VERSION ""

NS_ :

BS_:

BU_:

BO_ 2364747006 HVESP25MS1: 8 Vector__XXX
 SG_ Hvesp25Module1OperationalStatus : 0|2@1+ (1,0) [0|3] "" Vector__XXX
 SG_ Hvesp25Module2OperationalStatus : 2|2@1+ (1,0) [0|3] "" Vector__XXX
 SG_ Hvesp25Module3OperationalStatus : 4|2@1+ (1,0) [0|3] "" Vector__XXX
 SG_ Hvesp25Module4OperationalStatus : 6|2@1+ (1,0) [0|3] "" Vector__XXX
 SG_ Hvesp25Module5OperationalStatus : 8|2@1+ (1,0) [0|3] "" Vector__XXX
 SG_ Hvesp25Module6OperationalStatus : 10|2@1+ (1,0) [0|3] "" Vector__XXX
 SG_ Hvesp25Module7OperationalStatus : 12|2@1+ (1,0) [0|3] "" Vector__XXX
 SG_ Hvesp25Module8OperationalStatus : 14|2@1+ (1,0) [0|3] "" Vector__XXX
 SG_ Hvesp25Module9OperationalStatus : 16|2@1+ (1,0) [0|3] "" Vector__XXX
 SG_ Hvsp25Mdl10OprtnlStts : 18|2@1+ (1,0) [0|3] "" Vector__XXX
 SG_ Hvsp25Mdl11OprtnlStts : 20|2@1+ (1,0) [0|3] "" Vector__XXX
 SG_ Hvsp25Mdl12OprtnlStts : 22|2@1+ (1,0) [0|3] "" Vector__XXX
 SG_ Hvsp25Mdl13OprtnlStts : 24|2@1+ (1,0) [0|3] "" Vector__XXX
 SG_ Hvsp25Mdl14OprtnlStts : 26|2@1+ (1,0) [0|3] "" Vector__XXX
 SG_ Hvsp25Mdl15OprtnlStts : 28|2@1+ (1,0) [0|3] "" Vector__XXX
 SG_ Hvsp25Mdl16OprtnlStts : 30|2@1+ (1,0) [0|3] "" Vector__XXX
 SG_ Hvsp25Mdl17OprtnlStts : 32|2@1+ (1,0) [0|3] "" Vector__XXX
 SG_ Hvsp25Mdl18OprtnlStts : 34|2@1+ (1,0) [0|3] "" Vector__XXX
 SG_ Hvsp25Mdl19OprtnlStts : 36|2@1+ (1,0) [0|3] "" Vector__XXX
 SG_ Hvsp25Mdl20OprtnlStts : 38|2@1+ (1,0) [0|3] "" Vector__XXX
 SG_ Hvsp25Mdl21OprtnlStts : 40|2@1+ (1,0) [0|3] "" Vector__XXX
 SG_ Hvsp25Mdl22OprtnlStts : 42|2@1+ (1,0) [0|3] "" Vector__XXX
 SG_ Hvsp25Mdl23OprtnlStts : 44|2@1+ (1,0) [0|3] "" Vector__XXX
 SG_ Hvsp25Mdl24OprtnlStts : 46|2@1+ (1,0) [0|3] "" Vector__XXX
 SG_ Hvsp25Mdl25OprtnlStts : 48|2@1+ (1,0) [0|3] "" Vector__XXX
 SG_ Hvsp25Mdl26OprtnlStts : 50|2@1+ (1,0) [0|3] "" Vector__XXX
 SG_ Hvsp25Mdl27OprtnlStts : 52|2@1+ (1,0) [0|3] "" Vector__XXX
 SG_ Hvsp25Mdl28OprtnlStts : 54|2@1+ (1,0) [0|3] "" Vector__XXX
 SG_ Hvsp25Mdl29OprtnlStts : 56|2@1+ (1,0) [0|3] "" Vector__XXX
 SG_ Hvsp25Mdl30OprtnlStts : 58|2@1+ (1,0) [0|3] "" Vector__XXX
 SG_ Hvsp25Mdl31OprtnlStts : 60|2@1+ (1,0) [0|3] "" Vector__XXX
 SG_ Hvsp25Mdl32OprtnlStts : 62|2@1+ (1,0) [0|3] "" Vector__XXX

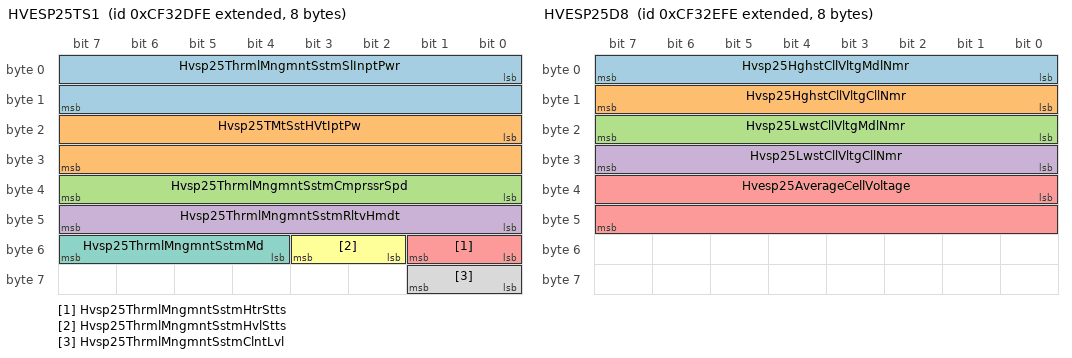
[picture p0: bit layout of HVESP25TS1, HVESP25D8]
BO_ 2364747262 HVESP25TS1: 8 Vector__XXX
 SG_ Hvsp25ThrmlMngmntSstmSlInptPwr : 0|16@1+ (0.5,0) [0|32127.5] "W" Vector__XXX
 SG_ Hvsp25TMtSstHVtIptPw : 16|16@1+ (0.5,0) [0|32127.5] "W" Vector__XXX
 SG_ Hvsp25ThrmlMngmntSstmCmprssrSpd : 32|8@1+ (32,0) [0|8000] "rpm" Vector__XXX
 SG_ Hvsp25ThrmlMngmntSstmRltvHmdt : 40|8@1+ (0.4,0) [0|100] "%" Vector__XXX
 SG_ Hvsp25ThrmlMngmntSstmHtrStts : 48|2@1+ (1,0) [0|3] "" Vector__XXX
 SG_ Hvsp25ThrmlMngmntSstmHvlStts : 50|2@1+ (1,0) [0|3] "" Vector__XXX
 SG_ Hvsp25ThrmlMngmntSstmMd : 52|4@1+ (1,0) [0|15] "" Vector__XXX
 SG_ Hvsp25ThrmlMngmntSstmClntLvl : 56|2@1+ (1,0) [0|3] "" Vector__XXX

BO_ 2364747518 HVESP25D8: 8 Vector__XXX
 SG_ Hvsp25HghstCllVltgMdlNmr : 0|8@1+ (1,0) [0|250] "count" Vector__XXX
 SG_ Hvsp25HghstCllVltgCllNmr : 8|8@1+ (1,0) [0|250] "count" Vector__XXX
 SG_ Hvsp25LwstCllVltgMdlNmr : 16|8@1+ (1,0) [0|250] "count" Vector__XXX
 SG_ Hvsp25LwstCllVltgCllNmr : 24|8@1+ (1,0) [0|250] "count" Vector__XXX
 SG_ Hvesp25AverageCellVoltage : 32|16@1+ (0.001,0) [0|64.255] "V" Vector__XXX

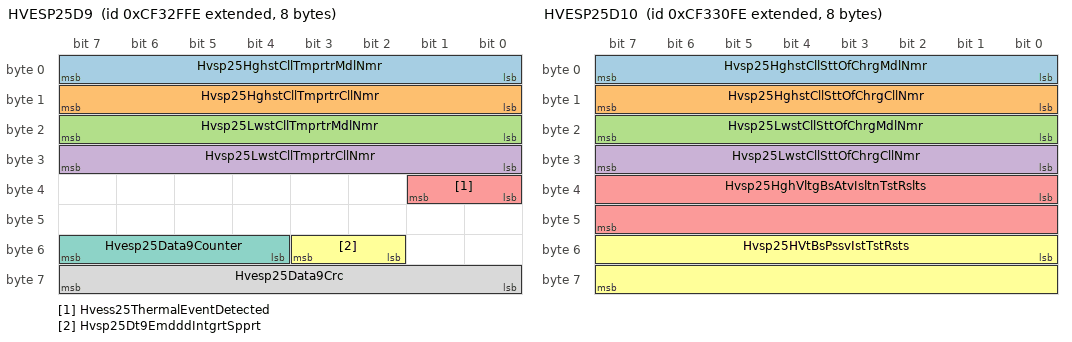
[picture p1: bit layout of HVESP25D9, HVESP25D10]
BO_ 2364747774 HVESP25D9: 8 Vector__XXX
 SG_ Hvsp25HghstCllTmprtrMdlNmr : 0|8@1+ (1,0) [0|250] "count" Vector__XXX
 SG_ Hvsp25HghstCllTmprtrCllNmr : 8|8@1+ (1,0) [0|250] "count" Vector__XXX
 SG_ Hvsp25LwstCllTmprtrMdlNmr : 16|8@1+ (1,0) [0|250] "count" Vector__XXX
 SG_ Hvsp25LwstCllTmprtrCllNmr : 24|8@1+ (1,0) [0|250] "count" Vector__XXX
 SG_ Hvess25ThermalEventDetected : 32|2@1+ (1,0) [0|3] "" Vector__XXX
 SG_ Hvsp25Dt9EmdddIntgrtSpprt : 50|2@1+ (1,0) [0|3] "" Vector__XXX
 SG_ Hvesp25Data9Counter : 52|4@1+ (1,0) [0|15] "" Vector__XXX
 SG_ Hvesp25Data9Crc : 56|8@1+ (1,0) [0|250] "count" Vector__XXX

BO_ 2364748030 HVESP25D10: 8 Vector__XXX
 SG_ Hvsp25HghstCllSttOfChrgMdlNmr : 0|8@1+ (1,0) [0|250] "count" Vector__XXX
 SG_ Hvsp25HghstCllSttOfChrgCllNmr : 8|8@1+ (1,0) [0|250] "count" Vector__XXX
 SG_ Hvsp25LwstCllSttOfChrgMdlNmr : 16|8@1+ (1,0) [0|250] "count" Vector__XXX
 SG_ Hvsp25LwstCllSttOfChrgCllNmr : 24|8@1+ (1,0) [0|250] "count" Vector__XXX
 SG_ Hvsp25HghVltgBsAtvIsltnTstRslts : 32|16@1+ (0.1,0) [0|6425.5] "OhmPerV" Vector__XXX
 SG_ Hvsp25HVtBsPssvIstTstRsts : 48|16@1+ (0.1,0) [0|6425.5] "OhmPerV" Vector__XXX

BO_ 2364748286 HVESP25D11: 8 Vector__XXX
 SG_ Hvsp25BsVltgNgtvTChsssGrndVltg : 0|16@1+ (0.05,0) [0|3212.75] "V" Vector__XXX
 SG_ Hvsp25VltgLvlNgtvTChsssGrndVltg : 16|16@1+ (0.05,0) [0|3212.75] "V" Vector__XXX
 SG_ Hvesp25ActualChargeRate : 32|16@1+ (0.05,0) [0|3212.75] "kW" Vector__XXX

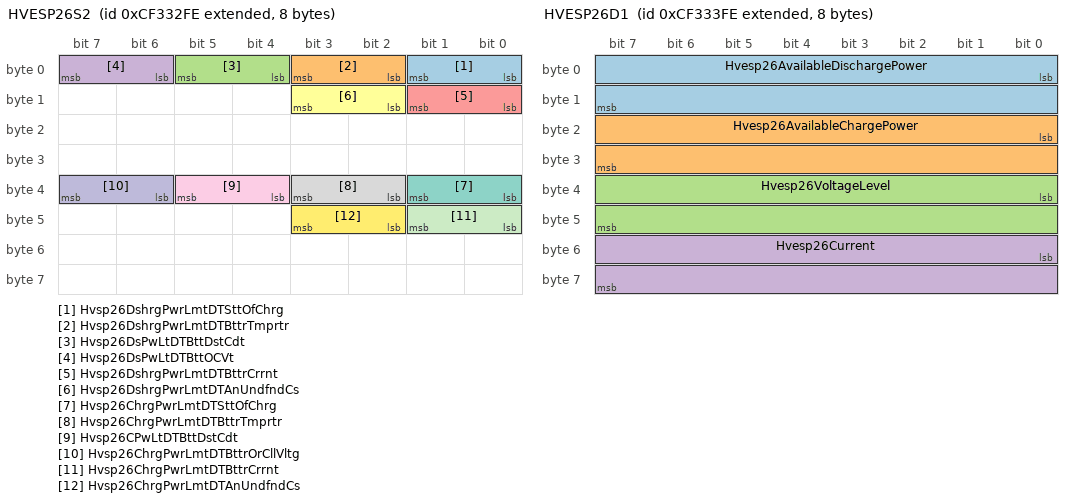
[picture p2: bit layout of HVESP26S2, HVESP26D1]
BO_ 2364748542 HVESP26S2: 8 Vector__XXX
 SG_ Hvsp26DshrgPwrLmtDTSttOfChrg : 0|2@1+ (1,0) [0|3] "" Vector__XXX
 SG_ Hvsp26DshrgPwrLmtDTBttrTmprtr : 2|2@1+ (1,0) [0|3] "" Vector__XXX
 SG_ Hvsp26DsPwLtDTBttDstCdt : 4|2@1+ (1,0) [0|3] "" Vector__XXX
 SG_ Hvsp26DsPwLtDTBttOCVt : 6|2@1+ (1,0) [0|3] "" Vector__XXX
 SG_ Hvsp26DshrgPwrLmtDTBttrCrrnt : 8|2@1+ (1,0) [0|3] "" Vector__XXX
 SG_ Hvsp26DshrgPwrLmtDTAnUndfndCs : 10|2@1+ (1,0) [0|3] "" Vector__XXX
 SG_ Hvsp26ChrgPwrLmtDTSttOfChrg : 32|2@1+ (1,0) [0|3] "" Vector__XXX
 SG_ Hvsp26ChrgPwrLmtDTBttrTmprtr : 34|2@1+ (1,0) [0|3] "" Vector__XXX
 SG_ Hvsp26CPwLtDTBttDstCdt : 36|2@1+ (1,0) [0|3] "" Vector__XXX
 SG_ Hvsp26ChrgPwrLmtDTBttrOrCllVltg : 38|2@1+ (1,0) [0|3] "" Vector__XXX
 SG_ Hvsp26ChrgPwrLmtDTBttrCrrnt : 40|2@1+ (1,0) [0|3] "" Vector__XXX
 SG_ Hvsp26ChrgPwrLmtDTAnUndfndCs : 42|2@1+ (1,0) [0|3] "" Vector__XXX

BO_ 2364748798 HVESP26D1: 8 Vector__XXX
 SG_ Hvesp26AvailableDischargePower : 0|16@1+ (0.05,0) [0|3212.75] "kW" Vector__XXX
 SG_ Hvesp26AvailableChargePower : 16|16@1+ (0.05,0) [0|3212.75] "kW" Vector__XXX
 SG_ Hvesp26VoltageLevel : 32|16@1+ (0.05,0) [0|3212.75] "V" Vector__XXX
 SG_ Hvesp26Current : 48|16@1+ (0.05,-1600) [-1600|1612.75] "A" Vector__XXX

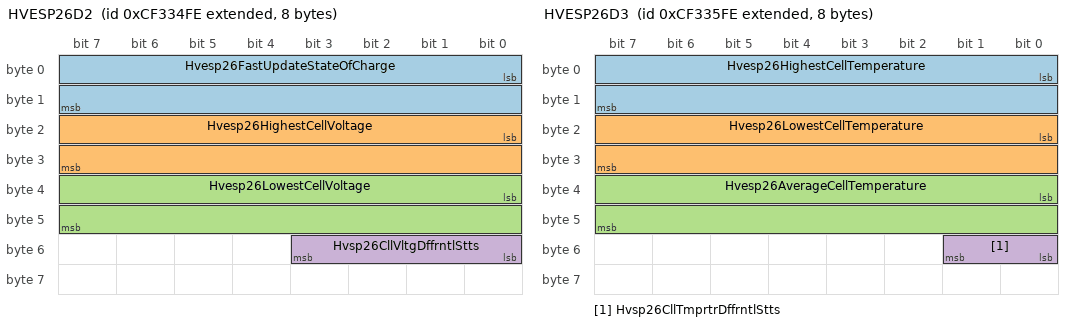
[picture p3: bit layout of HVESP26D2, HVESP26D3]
BO_ 2364749054 HVESP26D2: 8 Vector__XXX
 SG_ Hvesp26FastUpdateStateOfCharge : 0|16@1+ (0.0015625,0) [0|100.3984375] "%" Vector__XXX
 SG_ Hvesp26HighestCellVoltage : 16|16@1+ (0.001,0) [0|64.255] "V" Vector__XXX
 SG_ Hvesp26LowestCellVoltage : 32|16@1+ (0.001,0) [0|64.255] "V" Vector__XXX
 SG_ Hvsp26CllVltgDffrntlStts : 48|4@1+ (1,0) [0|15] "" Vector__XXX

BO_ 2364749310 HVESP26D3: 8 Vector__XXX
 SG_ Hvesp26HighestCellTemperature : 0|16@1+ (0.03125,-273) [-273|1734.96875] "degC" Vector__XXX
 SG_ Hvesp26LowestCellTemperature : 16|16@1+ (0.03125,-273) [-273|1734.96875] "degC" Vector__XXX
 SG_ Hvesp26AverageCellTemperature : 32|16@1+ (0.03125,-273) [-273|1734.96875] "degC" Vector__XXX
 SG_ Hvsp26CllTmprtrDffrntlStts : 48|2@1+ (1,0) [0|3] "" Vector__XXX

BO_ 2364749566 HVESP26D4: 8 Vector__XXX
 SG_ Hvesp26DischargeCapacity : 0|16@1+ (0.01,0) [0|642.55] "Ah" Vector__XXX
 SG_ Hvesp26ChargeCapacity : 16|16@1+ (0.01,0) [0|642.55] "Ah" Vector__XXX
 SG_ Hvesp26CellBalancingCount : 32|16@1+ (1,0) [0|64255] "count" Vector__XXX

BO_ 2364749822 HVESP26D5: 8 Vector__XXX
 SG_ Hvesp26LowestCellStateOfCharge : 32|16@1+ (0.0015625,0) [0|100.3984375] "%" Vector__XXX
 SG_ Hvesp26HighestCellStateOfCharge : 48|16@1+ (0.0015625,0) [0|100.3984375] "%" Vector__XXX
 SG_ Hvsp26MxmmInstntnsDshrgCrrntLmt : 0|16@1+ (0.05,-1600) [-1600|0] "A" Vector__XXX
 SG_ Hvsp26MxmmInstntnsChrgCrrntLmt : 16|16@1+ (0.05,-1600) [0|1612.75] "A" Vector__XXX

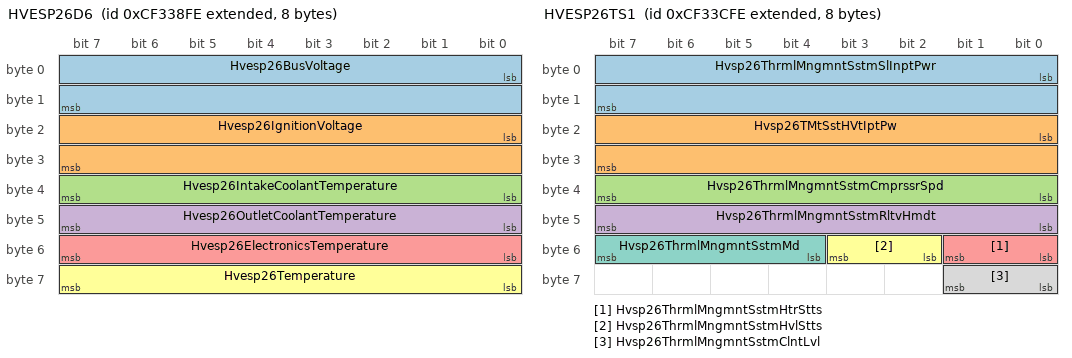
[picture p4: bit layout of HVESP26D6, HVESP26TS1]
BO_ 2364750078 HVESP26D6: 8 Vector__XXX
 SG_ Hvesp26BusVoltage : 0|16@1+ (0.05,0) [0|3212.75] "V" Vector__XXX
 SG_ Hvesp26IgnitionVoltage : 16|16@1+ (0.01,0) [0|642.55] "V" Vector__XXX
 SG_ Hvesp26IntakeCoolantTemperature : 32|8@1+ (1,-40) [-40|210] "degC" Vector__XXX
 SG_ Hvesp26OutletCoolantTemperature : 40|8@1+ (1,-40) [-40|210] "degC" Vector__XXX
 SG_ Hvesp26ElectronicsTemperature : 48|8@1+ (1,-40) [-40|210] "degC" Vector__XXX
 SG_ Hvesp26Temperature : 56|8@1+ (1,-40) [-40|210] "degC" Vector__XXX

BO_ 2364750334 HVESP26S1: 8 Vector__XXX
 SG_ Hvsp26HghVltgBsPstvCnttrStt : 0|2@1+ (1,0) [0|3] "" Vector__XXX
 SG_ Hvsp26HghVltgBsNgtvCnttrStt : 2|2@1+ (1,0) [0|3] "" Vector__XXX
 SG_ Hvsp26HghVltgBsDsnntFrwrnng : 4|4@1+ (1,0) [0|15] "" Vector__XXX
 SG_ Hvsp26HghVltgBsPrChrgRlStt : 8|2@1+ (1,0) [0|3] "" Vector__XXX
 SG_ Hvsp26CntrOfPkCnttrStt : 10|2@1+ (1,0) [0|3] "" Vector__XXX
 SG_ Hvsp26HghVltgBsAtvIsltnTstStts : 12|4@1+ (1,0) [0|15] "" Vector__XXX
 SG_ Hvsp26HghVltgBsPssvIsltnTstStts : 16|4@1+ (1,0) [0|15] "" Vector__XXX
 SG_ Hvesp26HvilStatus : 20|2@1+ (1,0) [0|3] "" Vector__XXX
 SG_ Hvesp26InertiaSwitchStatus : 22|2@1+ (1,0) [0|3] "" Vector__XXX
 SG_ Hvesp26StateOfChargeStatus : 24|4@1+ (1,0) [0|15] "" Vector__XXX
 SG_ Hvesp26CellBalanceStatus : 28|2@1+ (1,0) [0|3] "" Vector__XXX
 SG_ Hvesp26CellBalancingActive : 30|2@1+ (1,0) [0|3] "" Vector__XXX
 SG_ Hvesp26InternalChargerStatus : 32|2@1+ (1,0) [0|3] "" Vector__XXX
 SG_ Hvsp26HghVltgBsCnntnStts : 40|4@1+ (1,0) [0|15] "" Vector__XXX
 SG_ Hvesp26OperationalStatus : 44|4@1+ (1,0) [0|15] "" Vector__XXX
 SG_ Hvesp26Status1Counter : 52|4@1+ (1,0) [0|15] "" Vector__XXX
 SG_ Hvesp26Status1Crc : 56|8@1+ (1,0) [0|250] "count" Vector__XXX

BO_ 2364750590 HVESP26D7: 8 Vector__XXX
 SG_ Hvesp26DischargeEnergyCapacity : 0|24@1+ (0.001,0) [0|16449.535] "kWh" Vector__XXX
 SG_ Hvesp26ChargeEnergyCapacity : 24|24@1+ (0.001,0) [0|16449.535] "kWh" Vector__XXX
 SG_ Hvsp26MxmmChrgVltgLmt : 48|16@1+ (0.05,0) [0|3212.75] "V" Vector__XXX

BO_ 2364750846 HVESP26MS1: 8 Vector__XXX
 SG_ Hvesp26Module1OperationalStatus : 0|2@1+ (1,0) [0|3] "" Vector__XXX
 SG_ Hvesp26Module2OperationalStatus : 2|2@1+ (1,0) [0|3] "" Vector__XXX
 SG_ Hvesp26Module3OperationalStatus : 4|2@1+ (1,0) [0|3] "" Vector__XXX
 SG_ Hvesp26Module4OperationalStatus : 6|2@1+ (1,0) [0|3] "" Vector__XXX
 SG_ Hvesp26Module5OperationalStatus : 8|2@1+ (1,0) [0|3] "" Vector__XXX
 SG_ Hvesp26Module6OperationalStatus : 10|2@1+ (1,0) [0|3] "" Vector__XXX
 SG_ Hvesp26Module7OperationalStatus : 12|2@1+ (1,0) [0|3] "" Vector__XXX
 SG_ Hvesp26Module8OperationalStatus : 14|2@1+ (1,0) [0|3] "" Vector__XXX
 SG_ Hvesp26Module9OperationalStatus : 16|2@1+ (1,0) [0|3] "" Vector__XXX
 SG_ Hvsp26Mdl10OprtnlStts : 18|2@1+ (1,0) [0|3] "" Vector__XXX
 SG_ Hvsp26Mdl11OprtnlStts : 20|2@1+ (1,0) [0|3] "" Vector__XXX
 SG_ Hvsp26Mdl12OprtnlStts : 22|2@1+ (1,0) [0|3] "" Vector__XXX
 SG_ Hvsp26Mdl13OprtnlStts : 24|2@1+ (1,0) [0|3] "" Vector__XXX
 SG_ Hvsp26Mdl14OprtnlStts : 26|2@1+ (1,0) [0|3] "" Vector__XXX
 SG_ Hvsp26Mdl15OprtnlStts : 28|2@1+ (1,0) [0|3] "" Vector__XXX
 SG_ Hvsp26Mdl16OprtnlStts : 30|2@1+ (1,0) [0|3] "" Vector__XXX
 SG_ Hvsp26Mdl17OprtnlStts : 32|2@1+ (1,0) [0|3] "" Vector__XXX
 SG_ Hvsp26Mdl18OprtnlStts : 34|2@1+ (1,0) [0|3] "" Vector__XXX
 SG_ Hvsp26Mdl19OprtnlStts : 36|2@1+ (1,0) [0|3] "" Vector__XXX
 SG_ Hvsp26Mdl20OprtnlStts : 38|2@1+ (1,0) [0|3] "" Vector__XXX
 SG_ Hvsp26Mdl21OprtnlStts : 40|2@1+ (1,0) [0|3] "" Vector__XXX
 SG_ Hvsp26Mdl22OprtnlStts : 42|2@1+ (1,0) [0|3] "" Vector__XXX
 SG_ Hvsp26Mdl23OprtnlStts : 44|2@1+ (1,0) [0|3] "" Vector__XXX
 SG_ Hvsp26Mdl24OprtnlStts : 46|2@1+ (1,0) [0|3] "" Vector__XXX
 SG_ Hvsp26Mdl25OprtnlStts : 48|2@1+ (1,0) [0|3] "" Vector__XXX
 SG_ Hvsp26Mdl26OprtnlStts : 50|2@1+ (1,0) [0|3] "" Vector__XXX
 SG_ Hvsp26Mdl27OprtnlStts : 52|2@1+ (1,0) [0|3] "" Vector__XXX
 SG_ Hvsp26Mdl28OprtnlStts : 54|2@1+ (1,0) [0|3] "" Vector__XXX
 SG_ Hvsp26Mdl29OprtnlStts : 56|2@1+ (1,0) [0|3] "" Vector__XXX
 SG_ Hvsp26Mdl30OprtnlStts : 58|2@1+ (1,0) [0|3] "" Vector__XXX
 SG_ Hvsp26Mdl31OprtnlStts : 60|2@1+ (1,0) [0|3] "" Vector__XXX
 SG_ Hvsp26Mdl32OprtnlStts : 62|2@1+ (1,0) [0|3] "" Vector__XXX

BO_ 2364751102 HVESP26TS1: 8 Vector__XXX
 SG_ Hvsp26ThrmlMngmntSstmSlInptPwr : 0|16@1+ (0.5,0) [0|32127.5] "W" Vector__XXX
 SG_ Hvsp26TMtSstHVtIptPw : 16|16@1+ (0.5,0) [0|32127.5] "W" Vector__XXX
 SG_ Hvsp26ThrmlMngmntSstmCmprssrSpd : 32|8@1+ (32,0) [0|8000] "rpm" Vector__XXX
 SG_ Hvsp26ThrmlMngmntSstmRltvHmdt : 40|8@1+ (0.4,0) [0|100] "%" Vector__XXX
 SG_ Hvsp26ThrmlMngmntSstmHtrStts : 48|2@1+ (1,0) [0|3] "" Vector__XXX
 SG_ Hvsp26ThrmlMngmntSstmHvlStts : 50|2@1+ (1,0) [0|3] "" Vector__XXX
 SG_ Hvsp26ThrmlMngmntSstmMd : 52|4@1+ (1,0) [0|15] "" Vector__XXX
 SG_ Hvsp26ThrmlMngmntSstmClntLvl : 56|2@1+ (1,0) [0|3] "" Vector__XXX

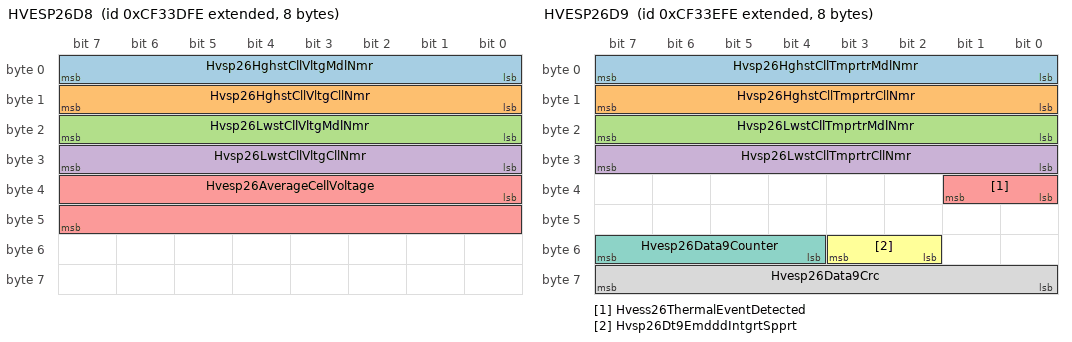
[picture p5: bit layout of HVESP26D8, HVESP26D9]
BO_ 2364751358 HVESP26D8: 8 Vector__XXX
 SG_ Hvsp26HghstCllVltgMdlNmr : 0|8@1+ (1,0) [0|250] "count" Vector__XXX
 SG_ Hvsp26HghstCllVltgCllNmr : 8|8@1+ (1,0) [0|250] "count" Vector__XXX
 SG_ Hvsp26LwstCllVltgMdlNmr : 16|8@1+ (1,0) [0|250] "count" Vector__XXX
 SG_ Hvsp26LwstCllVltgCllNmr : 24|8@1+ (1,0) [0|250] "count" Vector__XXX
 SG_ Hvesp26AverageCellVoltage : 32|16@1+ (0.001,0) [0|64.255] "V" Vector__XXX

BO_ 2364751614 HVESP26D9: 8 Vector__XXX
 SG_ Hvsp26HghstCllTmprtrMdlNmr : 0|8@1+ (1,0) [0|250] "count" Vector__XXX
 SG_ Hvsp26HghstCllTmprtrCllNmr : 8|8@1+ (1,0) [0|250] "count" Vector__XXX
 SG_ Hvsp26LwstCllTmprtrMdlNmr : 16|8@1+ (1,0) [0|250] "count" Vector__XXX
 SG_ Hvsp26LwstCllTmprtrCllNmr : 24|8@1+ (1,0) [0|250] "count" Vector__XXX
 SG_ Hvess26ThermalEventDetected : 32|2@1+ (1,0) [0|3] "" Vector__XXX
 SG_ Hvsp26Dt9EmdddIntgrtSpprt : 50|2@1+ (1,0) [0|3] "" Vector__XXX
 SG_ Hvesp26Data9Counter : 52|4@1+ (1,0) [0|15] "" Vector__XXX
 SG_ Hvesp26Data9Crc : 56|8@1+ (1,0) [0|250] "count" Vector__XXX

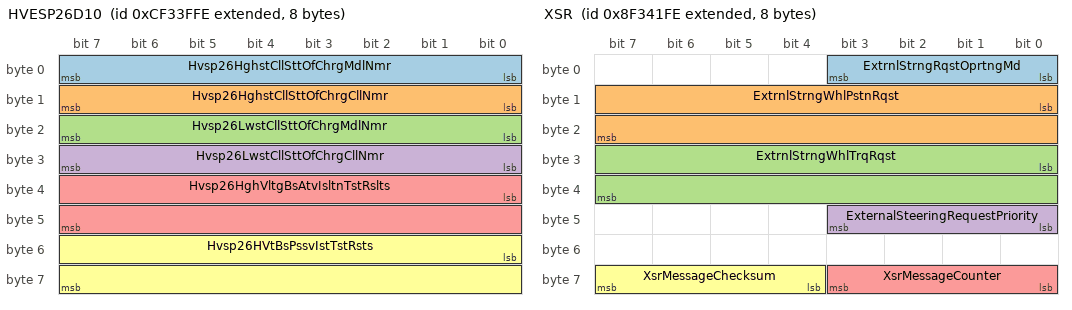
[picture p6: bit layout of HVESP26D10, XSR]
BO_ 2364751870 HVESP26D10: 8 Vector__XXX
 SG_ Hvsp26HghstCllSttOfChrgMdlNmr : 0|8@1+ (1,0) [0|250] "count" Vector__XXX
 SG_ Hvsp26HghstCllSttOfChrgCllNmr : 8|8@1+ (1,0) [0|250] "count" Vector__XXX
 SG_ Hvsp26LwstCllSttOfChrgMdlNmr : 16|8@1+ (1,0) [0|250] "count" Vector__XXX
 SG_ Hvsp26LwstCllSttOfChrgCllNmr : 24|8@1+ (1,0) [0|250] "count" Vector__XXX
 SG_ Hvsp26HghVltgBsAtvIsltnTstRslts : 32|16@1+ (0.1,0) [0|6425.5] "OhmPerV" Vector__XXX
 SG_ Hvsp26HVtBsPssvIstTstRsts : 48|16@1+ (0.1,0) [0|6425.5] "OhmPerV" Vector__XXX

BO_ 2364752126 HVESP26D11: 8 Vector__XXX
 SG_ Hvsp26BsVltgNgtvTChsssGrndVltg : 0|16@1+ (0.05,0) [0|3212.75] "V" Vector__XXX
 SG_ Hvsp26VltgLvlNgtvTChsssGrndVltg : 16|16@1+ (0.05,0) [0|3212.75] "V" Vector__XXX
 SG_ Hvesp26ActualChargeRate : 32|16@1+ (0.05,0) [0|3212.75] "kW" Vector__XXX

BO_ 2297643518 XSR: 8 Vector__XXX
 SG_ ExtrnlStrngRqstOprtngMd : 0|4@1+ (1,0) [0|15] "" Vector__XXX
 SG_ ExtrnlStrngWhlPstnRqst : 8|16@1+ (0.0625,-2008) [-2008|2007.9375] "deg" Vector__XXX
 SG_ ExtrnlStrngWhlTrqRqst : 24|16@1+ (0.0009765625,-31) [-31|31.7490234375] "Nm" Vector__XXX
 SG_ ExternalSteeringRequestPriority : 40|4@1+ (1,0) [0|15] "" Vector__XXX
 SG_ XsrMessageCounter : 56|4@1+ (1,0) [0|15] "count" Vector__XXX
 SG_ XsrMessageChecksum : 60|4@1+ (1,0) [0|15] "count" Vector__XXX

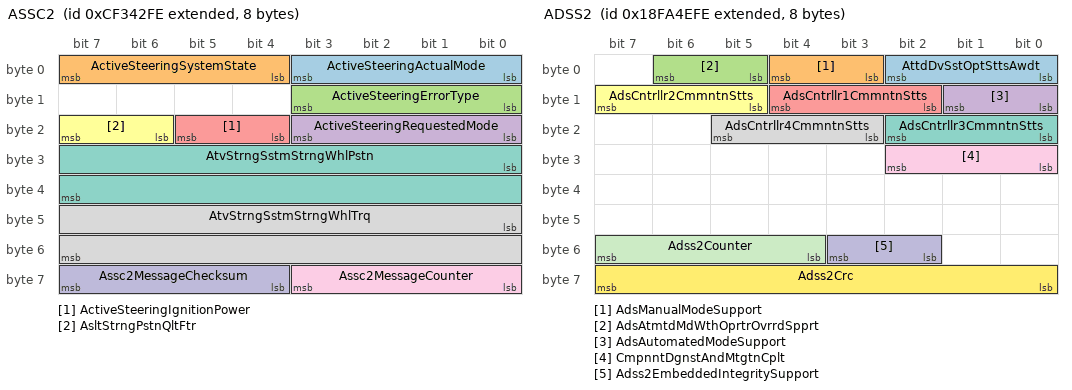
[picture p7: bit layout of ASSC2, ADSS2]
BO_ 2364752638 ASSC2: 8 Vector__XXX
 SG_ ActiveSteeringActualMode : 0|4@1+ (1,0) [0|15] "" Vector__XXX
 SG_ ActiveSteeringSystemState : 4|4@1+ (1,0) [0|15] "" Vector__XXX
 SG_ ActiveSteeringErrorType : 8|4@1+ (1,0) [0|15] "" Vector__XXX
 SG_ ActiveSteeringRequestedMode : 16|4@1+ (1,0) [0|15] "" Vector__XXX
 SG_ ActiveSteeringIgnitionPower : 20|2@1+ (1,0) [0|3] "" Vector__XXX
 SG_ AsltStrngPstnQltFtr : 22|2@1+ (1,0) [0|3] "" Vector__XXX
 SG_ AtvStrngSstmStrngWhlPstn : 24|16@1+ (0.0625,-2008) [-2008|2007.9375] "deg" Vector__XXX
 SG_ AtvStrngSstmStrngWhlTrq : 40|16@1+ (0.0009765625,-31) [-31|31.7490234375] "Nm" Vector__XXX
 SG_ Assc2MessageCounter : 56|4@1+ (1,0) [0|15] "count" Vector__XXX
 SG_ Assc2MessageChecksum : 60|4@1+ (1,0) [0|15] "count" Vector__XXX

BO_ 2566540286 A2SCRDSI5: 8 Vector__XXX
 SG_ Atttt2DsExstFdDs2PssExtddR : 0|16@1+ (0.1,-100) [-100|6325.5] "kPa" Vector__XXX
 SG_ Atttt2DsExstFdDs3PssExtddR : 16|16@1+ (0.1,-100) [-100|6325.5] "kPa" Vector__XXX

BO_ 2566540542 A1SCRDSI5: 8 Vector__XXX
 SG_ Atttt1DsExstFdDs2PssExtddR : 0|16@1+ (0.1,-100) [-100|6325.5] "kPa" Vector__XXX
 SG_ Atttt1DsExstFdDs3PssExtddR : 16|16@1+ (0.1,-100) [-100|6325.5] "kPa" Vector__XXX

BO_ 2566540798 EVEI: 8 Vector__XXX
 SG_ TotalTripEnergyConsumed : 0|32@1+ (0.1,0) [0|421108121.5] "kWh" Vector__XXX
 SG_ TripDriveEnergyEconomy : 32|16@1+ (0.001953125,0) [0|125.498046875] "kWh/km" Vector__XXX

BO_ 2566541054 ADSS2: 8 Vector__XXX
 SG_ AttdDvSstOptSttsAwdt : 0|3@1+ (1,0) [0|7] "" Vector__XXX
 SG_ AdsManualModeSupport : 3|2@1+ (1,0) [0|3] "" Vector__XXX
 SG_ AdsAtmtdMdWthOprtrOvrrdSpprt : 5|2@1+ (1,0) [0|3] "" Vector__XXX
 SG_ AdsAutomatedModeSupport : 8|2@1+ (1,0) [0|3] "" Vector__XXX
 SG_ AdsCntrllr1CmmntnStts : 10|3@1+ (1,0) [0|7] "" Vector__XXX
 SG_ AdsCntrllr2CmmntnStts : 13|3@1+ (1,0) [0|7] "" Vector__XXX
 SG_ AdsCntrllr3CmmntnStts : 16|3@1+ (1,0) [0|7] "" Vector__XXX
 SG_ AdsCntrllr4CmmntnStts : 19|3@1+ (1,0) [0|7] "" Vector__XXX
 SG_ CmpnntDgnstAndMtgtnCplt : 24|3@1+ (1,0) [0|7] "" Vector__XXX
 SG_ Adss2EmbeddedIntegritySupport : 50|2@1+ (1,0) [0|3] "" Vector__XXX
 SG_ Adss2Counter : 52|4@1+ (1,0) [0|15] "" Vector__XXX
 SG_ Adss2Crc : 56|8@1+ (1,0) [0|250] "count" Vector__XXX

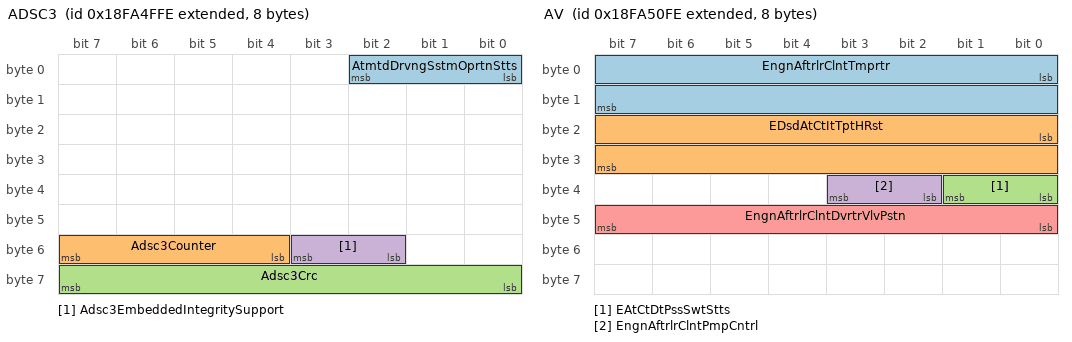
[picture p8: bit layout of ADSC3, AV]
BO_ 2566541310 ADSC3: 8 Vector__XXX
 SG_ AtmtdDrvngSstmOprtnStts : 0|3@1+ (1,0) [0|7] "" Vector__XXX
 SG_ Adsc3Counter : 52|4@1+ (1,0) [0|15] "" Vector__XXX
 SG_ Adsc3Crc : 56|8@1+ (1,0) [0|250] "count" Vector__XXX
 SG_ Adsc3EmbeddedIntegritySupport : 50|2@1+ (1,0) [0|3] "" Vector__XXX

BO_ 2566541566 AV: 8 Vector__XXX
 SG_ EngnAftrlrClntTmprtr : 0|16@1+ (0.03125,-273) [-273|1734.96875] "degC" Vector__XXX
 SG_ EDsdAtCtItTptHRst : 16|16@1+ (0.03125,-273) [-273|1734.96875] "degC" Vector__XXX
 SG_ EAtCtDtPssSwtStts : 32|2@1+ (1,0) [0|3] "" Vector__XXX
 SG_ EngnAftrlrClntPmpCntrl : 34|2@1+ (1,0) [0|3] "" Vector__XXX
 SG_ EngnAftrlrClntDvrtrVlvPstn : 40|8@1+ (0.4,0) [0|100] "%" Vector__XXX

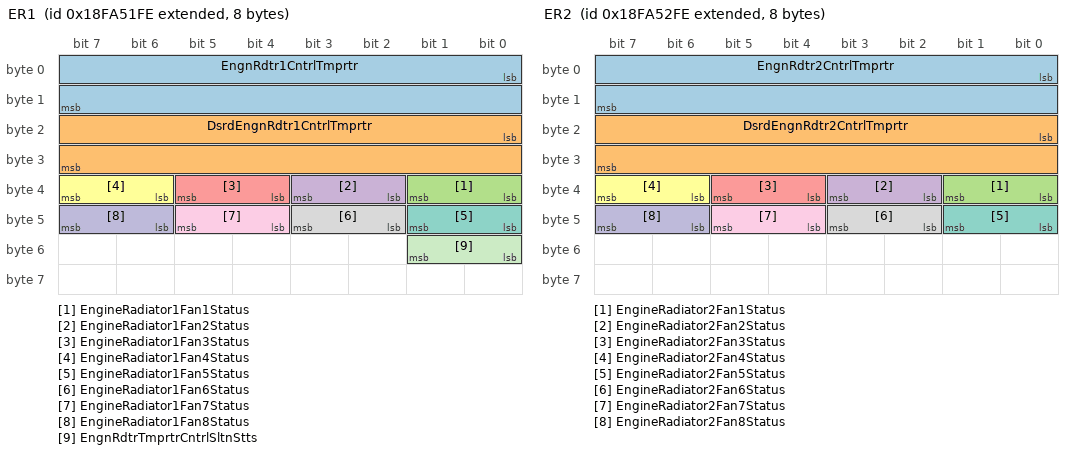
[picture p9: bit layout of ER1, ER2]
BO_ 2566541822 ER1: 8 Vector__XXX
 SG_ EngnRdtr1CntrlTmprtr : 0|16@1+ (0.03125,-273) [-273|1734.96875] "degC" Vector__XXX
 SG_ DsrdEngnRdtr1CntrlTmprtr : 16|16@1+ (0.03125,-273) [-273|1734.96875] "degC" Vector__XXX
 SG_ EngineRadiator1Fan1Status : 32|2@1+ (1,0) [0|3] "" Vector__XXX
 SG_ EngineRadiator1Fan2Status : 34|2@1+ (1,0) [0|3] "" Vector__XXX
 SG_ EngineRadiator1Fan3Status : 36|2@1+ (1,0) [0|3] "" Vector__XXX
 SG_ EngineRadiator1Fan4Status : 38|2@1+ (1,0) [0|3] "" Vector__XXX
 SG_ EngineRadiator1Fan5Status : 40|2@1+ (1,0) [0|3] "" Vector__XXX
 SG_ EngineRadiator1Fan6Status : 42|2@1+ (1,0) [0|3] "" Vector__XXX
 SG_ EngineRadiator1Fan7Status : 44|2@1+ (1,0) [0|3] "" Vector__XXX
 SG_ EngineRadiator1Fan8Status : 46|2@1+ (1,0) [0|3] "" Vector__XXX
 SG_ EngnRdtrTmprtrCntrlSltnStts : 48|2@1+ (1,0) [0|3] "" Vector__XXX

BO_ 2566542078 ER2: 8 Vector__XXX
 SG_ EngnRdtr2CntrlTmprtr : 0|16@1+ (0.03125,-273) [-273|1734.96875] "degC" Vector__XXX
 SG_ DsrdEngnRdtr2CntrlTmprtr : 16|16@1+ (0.03125,-273) [-273|1734.96875] "degC" Vector__XXX
 SG_ EngineRadiator2Fan1Status : 32|2@1+ (1,0) [0|3] "" Vector__XXX
 SG_ EngineRadiator2Fan2Status : 34|2@1+ (1,0) [0|3] "" Vector__XXX
 SG_ EngineRadiator2Fan3Status : 36|2@1+ (1,0) [0|3] "" Vector__XXX
 SG_ EngineRadiator2Fan4Status : 38|2@1+ (1,0) [0|3] "" Vector__XXX
 SG_ EngineRadiator2Fan5Status : 40|2@1+ (1,0) [0|3] "" Vector__XXX
 SG_ EngineRadiator2Fan6Status : 42|2@1+ (1,0) [0|3] "" Vector__XXX
 SG_ EngineRadiator2Fan7Status : 44|2@1+ (1,0) [0|3] "" Vector__XXX
 SG_ EngineRadiator2Fan8Status : 46|2@1+ (1,0) [0|3] "" Vector__XXX

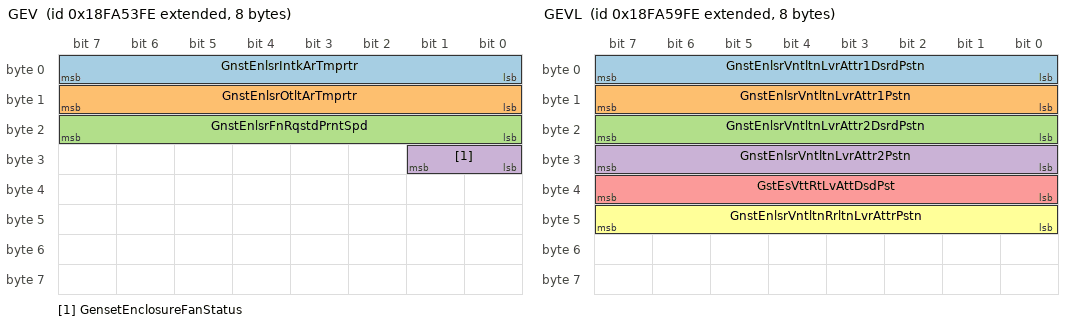
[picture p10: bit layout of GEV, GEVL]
BO_ 2566542334 GEV: 8 Vector__XXX
 SG_ GnstEnlsrIntkArTmprtr : 0|8@1+ (1,-40) [-40|210] "degC" Vector__XXX
 SG_ GnstEnlsrOtltArTmprtr : 8|8@1+ (1,-40) [-40|210] "degC" Vector__XXX
 SG_ GnstEnlsrFnRqstdPrntSpd : 16|8@1+ (0.4,0) [0|100] "%" Vector__XXX
 SG_ GensetEnclosureFanStatus : 24|2@1+ (1,0) [0|3] "" Vector__XXX

BO_ 2566542590 HE1: 8 Vector__XXX
 SG_ HtExhngr1PrmrIntkTmprtr : 0|16@1+ (0.03125,-273) [-273|1734.96875] "degC" Vector__XXX
 SG_ HtExhngr1PrmrOtltTmprtr : 16|16@1+ (0.03125,-273) [-273|1734.96875] "degC" Vector__XXX
 SG_ HtExhngr1SndrIntkTmprtr : 32|16@1+ (0.03125,-273) [-273|1734.96875] "degC" Vector__XXX
 SG_ HtExhngr1SndrOtltTmprtr : 48|16@1+ (0.03125,-273) [-273|1734.96875] "degC" Vector__XXX

BO_ 2566542846 HE2: 8 Vector__XXX
 SG_ HtExhngr2PrmrIntkTmprtr : 0|16@1+ (0.03125,-273) [-273|1734.96875] "degC" Vector__XXX
 SG_ HtExhngr2PrmrOtltTmprtr : 16|16@1+ (0.03125,-273) [-273|1734.96875] "degC" Vector__XXX
 SG_ HtExhngr2SndrIntkTmprtr : 32|16@1+ (0.03125,-273) [-273|1734.96875] "degC" Vector__XXX
 SG_ HtExhngr2SndrOtltTmprtr : 48|16@1+ (0.03125,-273) [-273|1734.96875] "degC" Vector__XXX

BO_ 2566543102 HE3: 8 Vector__XXX
 SG_ HtExhngr3PrmrIntkTmprtr : 0|16@1+ (0.03125,-273) [-273|1734.96875] "degC" Vector__XXX
 SG_ HtExhngr3PrmrOtltTmprtr : 16|16@1+ (0.03125,-273) [-273|1734.96875] "degC" Vector__XXX
 SG_ HtExhngr3SndrIntkTmprtr : 32|16@1+ (0.03125,-273) [-273|1734.96875] "degC" Vector__XXX
 SG_ HtExhngr3SndrOtltTmprtr : 48|16@1+ (0.03125,-273) [-273|1734.96875] "degC" Vector__XXX

BO_ 2566543358 HE4: 8 Vector__XXX
 SG_ HtExhngr4PrmrIntkTmprtr : 0|16@1+ (0.03125,-273) [-273|1734.96875] "degC" Vector__XXX
 SG_ HtExhngr4PrmrOtltTmprtr : 16|16@1+ (0.03125,-273) [-273|1734.96875] "degC" Vector__XXX
 SG_ HtExhngr4SndrIntkTmprtr : 32|16@1+ (0.03125,-273) [-273|1734.96875] "degC" Vector__XXX
 SG_ HtExhngr4SndrOtltTmprtr : 48|16@1+ (0.03125,-273) [-273|1734.96875] "degC" Vector__XXX

BO_ 2566543614 EEGHE: 8 Vector__XXX
 SG_ EngnExhstHtExhngrOtltTmprtr : 0|16@1+ (0.03125,-273) [-273|1734.96875] "degC" Vector__XXX
 SG_ EExstHtExBpssAtt1DsdPst : 16|8@1+ (0.4,0) [0|100] "%" Vector__XXX
 SG_ EngnExhstHtExhngrBpssAttr1Pstn : 24|8@1+ (0.4,0) [0|100] "%" Vector__XXX

BO_ 2566543870 GEVL: 8 Vector__XXX
 SG_ GnstEnlsrVntltnLvrAttr1DsrdPstn : 0|8@1+ (0.4,0) [0|100] "%" Vector__XXX
 SG_ GnstEnlsrVntltnLvrAttr1Pstn : 8|8@1+ (0.4,0) [0|100] "%" Vector__XXX
 SG_ GnstEnlsrVntltnLvrAttr2DsrdPstn : 16|8@1+ (0.4,0) [0|100] "%" Vector__XXX
 SG_ GnstEnlsrVntltnLvrAttr2Pstn : 24|8@1+ (0.4,0) [0|100] "%" Vector__XXX
 SG_ GstEsVttRtLvAttDsdPst : 32|8@1+ (0.4,0) [0|100] "%" Vector__XXX
 SG_ GnstEnlsrVntltnRrltnLvrAttrPstn : 40|8@1+ (0.4,0) [0|100] "%" Vector__XXX

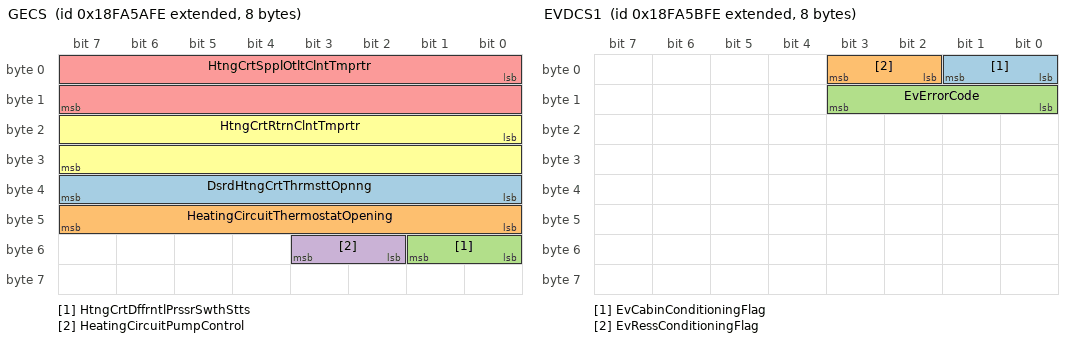
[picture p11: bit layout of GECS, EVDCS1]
BO_ 2566544126 GECS: 8 Vector__XXX
 SG_ DsrdHtngCrtThrmsttOpnng : 32|8@1+ (0.4,0) [0|100] "%" Vector__XXX
 SG_ HeatingCircuitThermostatOpening : 40|8@1+ (0.4,0) [0|100] "%" Vector__XXX
 SG_ HtngCrtDffrntlPrssrSwthStts : 48|2@1+ (1,0) [0|3] "" Vector__XXX
 SG_ HeatingCircuitPumpControl : 50|2@1+ (1,0) [0|3] "" Vector__XXX
 SG_ HtngCrtSpplOtltClntTmprtr : 0|16@1+ (0.03125,-273) [-273|1734.96875] "degC" Vector__XXX
 SG_ HtngCrtRtrnClntTmprtr : 16|16@1+ (0.03125,-273) [-273|1734.96875] "degC" Vector__XXX

BO_ 2566544382 EVDCS1: 8 Vector__XXX
 SG_ EvCabinConditioningFlag : 0|2@1+ (1,0) [0|3] "" Vector__XXX
 SG_ EvRessConditioningFlag : 2|2@1+ (1,0) [0|3] "" Vector__XXX
 SG_ EvErrorCode : 8|4@1+ (1,0) [0|15] "" Vector__XXX

BO_ 2566544638 EVSEDCLIM3: 8 Vector__XXX
 SG_ EvseEnergyToBeDelivered : 0|24@1+ (0.001,0) [0|16449.535] "kWh" Vector__XXX

BO_ 2566545406 EVDCLIM2: 8 Vector__XXX
 SG_ EvBulkStateOfCharge : 0|8@1+ (0.5,0) [0|125] "%" Vector__XXX
 SG_ EvFullStateOfCharge : 8|8@1+ (0.5,0) [0|125] "%" Vector__XXX
 SG_ EvEnergyCapacity : 16|16@1+ (1,0) [0|64255] "kWh" Vector__XXX
 SG_ EvEnergyRequested : 32|16@1+ (1,0) [0|64255] "kWh" Vector__XXX

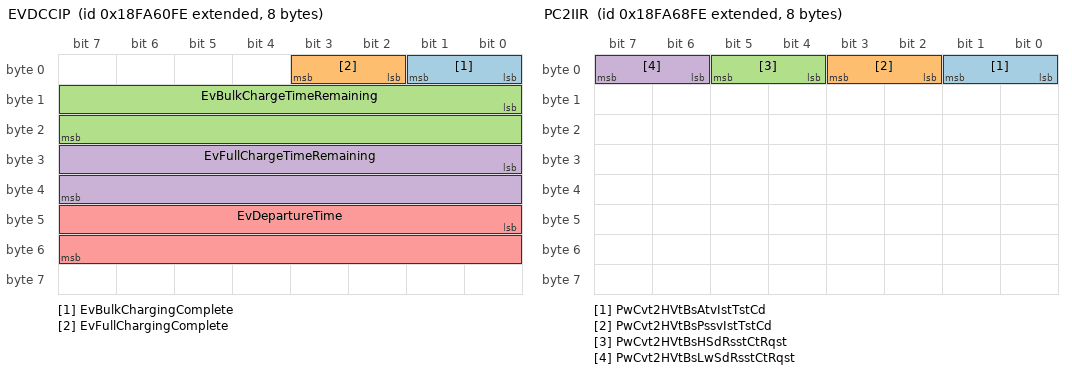
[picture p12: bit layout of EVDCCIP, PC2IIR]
BO_ 2566545662 EVDCCIP: 8 Vector__XXX
 SG_ EvBulkChargingComplete : 0|2@1+ (1,0) [0|3] "" Vector__XXX
 SG_ EvFullChargingComplete : 2|2@1+ (1,0) [0|3] "" Vector__XXX
 SG_ EvBulkChargeTimeRemaining : 8|16@1+ (10,0) [0|642550] "s" Vector__XXX
 SG_ EvFullChargeTimeRemaining : 24|16@1+ (10,0) [0|642550] "s" Vector__XXX
 SG_ EvDepartureTime : 40|16@1+ (10,0) [0|642550] "s" Vector__XXX

BO_ 2566546174 LD2: 8 Vector__XXX
 SG_ TractorHazardLights : 0|2@1+ (1,0) [0|3] "" Vector__XXX

BO_ 2365219838 LCMD2: 8 Vector__XXX
 SG_ LightingData2RequestCommand : 0|2@1+ (1,0) [0|3] "" Vector__XXX
 SG_ TractorHazardLightsCommand : 2|2@1+ (1,0) [0|3] "" Vector__XXX

BO_ 2566546686 ASI5: 8 Vector__XXX
 SG_ Aftrtrtmnt1SrIntkHghTmprtrCnt : 0|32@1+ (1,0) [0|4211081215] "count" Vector__XXX
 SG_ Aftrtrtmnt1TtlEvntCntWthNDfDlvr : 32|32@1+ (1,0) [0|4211081215] "count" Vector__XXX

BO_ 2566546942 ASI4: 8 Vector__XXX
 SG_ AftrtrtmntSrMlfntnCnt : 0|32@1+ (1,0) [0|4211081215] "count" Vector__XXX
 SG_ DieselExhaustFluidFrozenCount : 32|32@1+ (1,0) [0|4211081215] "count" Vector__XXX

BO_ 2566547198 ASI3: 8 Vector__XXX
 SG_ DslExhstFldTnk1EmptCnt : 0|32@1+ (1,0) [0|4211081215] "count" Vector__XXX
 SG_ DslExhstFldQltMlfntnCnt : 32|32@1+ (1,0) [0|4211081215] "count" Vector__XXX

BO_ 2633656318 FR1: 8 Vector__XXX
 SG_ EngineOilResistance : 0|32@1+ (1000,0) [0|4211081215000] "ohm" Vector__XXX
 SG_ HydraulicOilResistance : 32|32@1+ (1000,0) [0|4211081215000] "ohm" Vector__XXX

BO_ 2566547710 PC2IIR: 8 Vector__XXX
 SG_ PwCvt2HVtBsAtvIstTstCd : 0|2@1+ (1,0) [0|3] "" Vector__XXX
 SG_ PwCvt2HVtBsPssvIstTstCd : 2|2@1+ (1,0) [0|3] "" Vector__XXX
 SG_ PwCvt2HVtBsHSdRsstCtRqst : 4|2@1+ (1,0) [0|3] "" Vector__XXX
 SG_ PwCvt2HVtBsLwSdRsstCtRqst : 6|2@1+ (1,0) [0|3] "" Vector__XXX

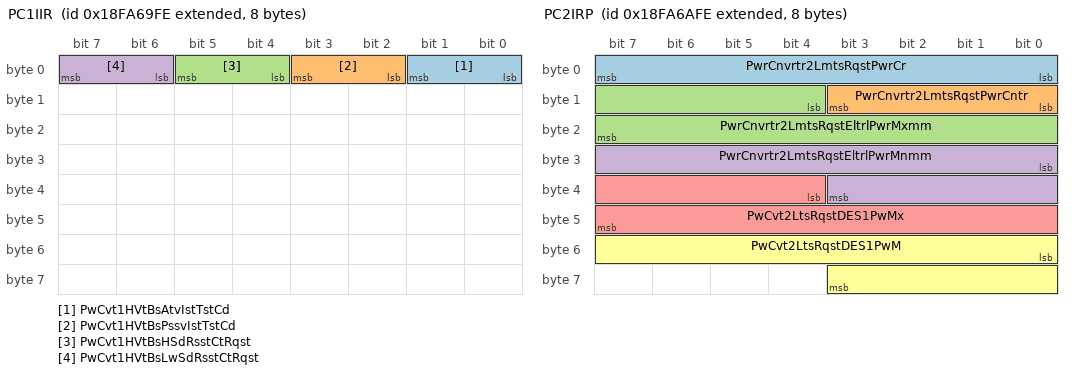
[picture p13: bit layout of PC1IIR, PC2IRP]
BO_ 2566547966 PC1IIR: 8 Vector__XXX
 SG_ PwCvt1HVtBsAtvIstTstCd : 0|2@1+ (1,0) [0|3] "" Vector__XXX
 SG_ PwCvt1HVtBsPssvIstTstCd : 2|2@1+ (1,0) [0|3] "" Vector__XXX
 SG_ PwCvt1HVtBsHSdRsstCtRqst : 4|2@1+ (1,0) [0|3] "" Vector__XXX
 SG_ PwCvt1HVtBsLwSdRsstCtRqst : 6|2@1+ (1,0) [0|3] "" Vector__XXX

BO_ 2566548222 PC2IRP: 8 Vector__XXX
 SG_ PwrCnvrtr2LmtsRqstPwrCr : 0|8@1+ (1,0) [0|250] "count" Vector__XXX
 SG_ PwrCnvrtr2LmtsRqstPwrCntr : 8|4@1+ (1,0) [0|15] "" Vector__XXX
 SG_ PwrCnvrtr2LmtsRqstEltrlPwrMxmm : 12|12@1+ (0.0625,-125) [-125|125.9375] "%" Vector__XXX
 SG_ PwrCnvrtr2LmtsRqstEltrlPwrMnmm : 24|12@1+ (0.0625,-125) [-125|125.9375] "%" Vector__XXX
 SG_ PwCvt2LtsRqstDES1PwMx : 36|12@1+ (0.0625,-125) [-125|125.9375] "%" Vector__XXX
 SG_ PwCvt2LtsRqstDES1PwM : 48|12@1+ (0.0625,-125) [-125|125.9375] "%" Vector__XXX

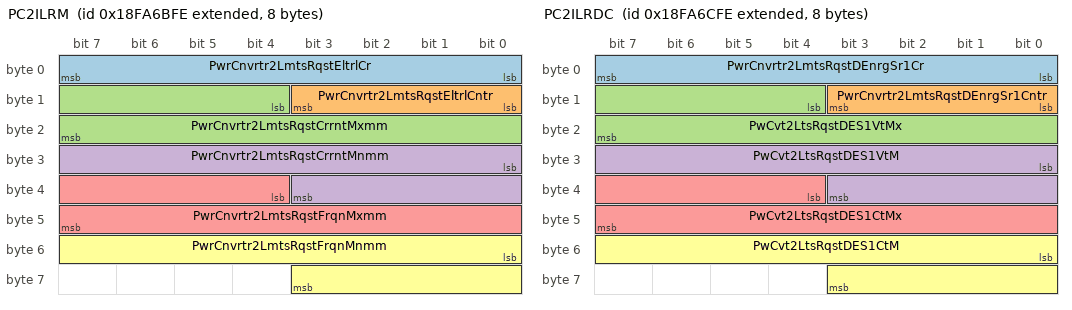
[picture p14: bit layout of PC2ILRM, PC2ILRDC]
BO_ 2566548478 PC2ILRM: 8 Vector__XXX
 SG_ PwrCnvrtr2LmtsRqstEltrlCr : 0|8@1+ (1,0) [0|250] "count" Vector__XXX
 SG_ PwrCnvrtr2LmtsRqstEltrlCntr : 8|4@1+ (1,0) [0|15] "" Vector__XXX
 SG_ PwrCnvrtr2LmtsRqstCrrntMxmm : 12|12@1+ (0.0625,-125) [-125|125.9375] "%" Vector__XXX
 SG_ PwrCnvrtr2LmtsRqstCrrntMnmm : 24|12@1+ (0.0625,-125) [-125|125.9375] "%" Vector__XXX
 SG_ PwrCnvrtr2LmtsRqstFrqnMxmm : 36|12@1+ (0.0625,-125) [-125|125.9375] "%" Vector__XXX
 SG_ PwrCnvrtr2LmtsRqstFrqnMnmm : 48|12@1+ (0.0625,-125) [-125|125.9375] "%" Vector__XXX

BO_ 2566548734 PC2ILRDC: 8 Vector__XXX
 SG_ PwrCnvrtr2LmtsRqstDEnrgSr1Cr : 0|8@1+ (1,0) [0|250] "count" Vector__XXX
 SG_ PwrCnvrtr2LmtsRqstDEnrgSr1Cntr : 8|4@1+ (1,0) [0|15] "" Vector__XXX
 SG_ PwCvt2LtsRqstDES1VtMx : 12|12@1+ (0.0625,-125) [-125|125.9375] "%" Vector__XXX
 SG_ PwCvt2LtsRqstDES1VtM : 24|12@1+ (0.0625,-125) [-125|125.9375] "%" Vector__XXX
 SG_ PwCvt2LtsRqstDES1CtMx : 36|12@1+ (0.0625,-125) [-125|125.9375] "%" Vector__XXX
 SG_ PwCvt2LtsRqstDES1CtM : 48|12@1+ (0.0625,-125) [-125|125.9375] "%" Vector__XXX

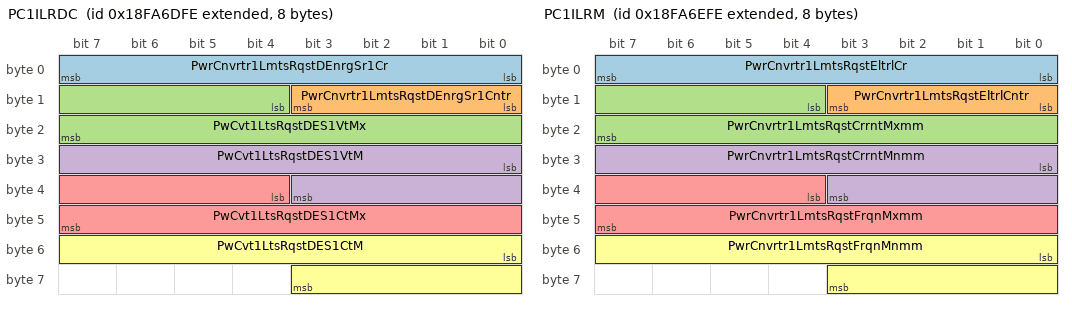
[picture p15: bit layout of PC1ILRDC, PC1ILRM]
BO_ 2566548990 PC1ILRDC: 8 Vector__XXX
 SG_ PwrCnvrtr1LmtsRqstDEnrgSr1Cr : 0|8@1+ (1,0) [0|250] "count" Vector__XXX
 SG_ PwrCnvrtr1LmtsRqstDEnrgSr1Cntr : 8|4@1+ (1,0) [0|15] "" Vector__XXX
 SG_ PwCvt1LtsRqstDES1VtMx : 12|12@1+ (0.0625,-125) [-125|125.9375] "%" Vector__XXX
 SG_ PwCvt1LtsRqstDES1VtM : 24|12@1+ (0.0625,-125) [-125|125.9375] "%" Vector__XXX
 SG_ PwCvt1LtsRqstDES1CtMx : 36|12@1+ (0.0625,-125) [-125|125.9375] "%" Vector__XXX
 SG_ PwCvt1LtsRqstDES1CtM : 48|12@1+ (0.0625,-125) [-125|125.9375] "%" Vector__XXX

BO_ 2566549246 PC1ILRM: 8 Vector__XXX
 SG_ PwrCnvrtr1LmtsRqstEltrlCr : 0|8@1+ (1,0) [0|250] "count" Vector__XXX
 SG_ PwrCnvrtr1LmtsRqstEltrlCntr : 8|4@1+ (1,0) [0|15] "" Vector__XXX
 SG_ PwrCnvrtr1LmtsRqstCrrntMxmm : 12|12@1+ (0.0625,-125) [-125|125.9375] "%" Vector__XXX
 SG_ PwrCnvrtr1LmtsRqstCrrntMnmm : 24|12@1+ (0.0625,-125) [-125|125.9375] "%" Vector__XXX
 SG_ PwrCnvrtr1LmtsRqstFrqnMxmm : 36|12@1+ (0.0625,-125) [-125|125.9375] "%" Vector__XXX
 SG_ PwrCnvrtr1LmtsRqstFrqnMnmm : 48|12@1+ (0.0625,-125) [-125|125.9375] "%" Vector__XXX

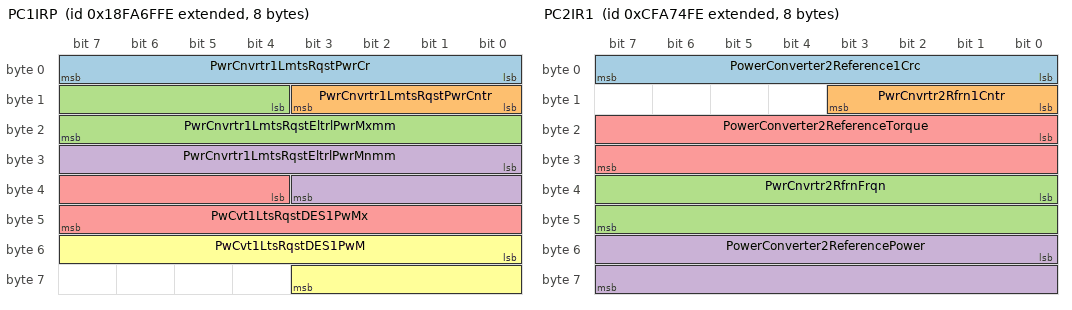
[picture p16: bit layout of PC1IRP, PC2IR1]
BO_ 2566549502 PC1IRP: 8 Vector__XXX
 SG_ PwrCnvrtr1LmtsRqstPwrCr : 0|8@1+ (1,0) [0|250] "count" Vector__XXX
 SG_ PwrCnvrtr1LmtsRqstPwrCntr : 8|4@1+ (1,0) [0|15] "" Vector__XXX
 SG_ PwrCnvrtr1LmtsRqstEltrlPwrMxmm : 12|12@1+ (0.0625,-125) [-125|125.9375] "%" Vector__XXX
 SG_ PwrCnvrtr1LmtsRqstEltrlPwrMnmm : 24|12@1+ (0.0625,-125) [-125|125.9375] "%" Vector__XXX
 SG_ PwCvt1LtsRqstDES1PwMx : 36|12@1+ (0.0625,-125) [-125|125.9375] "%" Vector__XXX
 SG_ PwCvt1LtsRqstDES1PwM : 48|12@1+ (0.0625,-125) [-125|125.9375] "%" Vector__XXX

BO_ 2566549758 PC1LD: 16 Vector__XXX
 SG_ PwrCnvrtr1TtlEnrgCnsmd : 0|32@1+ (100,0) [0|421108121500] "Watt-hour" Vector__XXX
 SG_ PwrCnvrtr1TtlEnrgGnrtd : 32|32@1+ (100,0) [0|421108121500] "Watt-hour" Vector__XXX
 SG_ PwrCnvrtr1TtlChrgCnsmd : 64|32@1+ (100,0) [0|421108121500] "Ah" Vector__XXX
 SG_ PwrCnvrtr1TtlChrgGnrtd : 96|32@1+ (100,0) [0|421108121500] "Ah" Vector__XXX

BO_ 2566550014 PC2LD: 16 Vector__XXX
 SG_ PwrCnvrtr2TtlEnrgCnsmd : 0|32@1+ (100,0) [0|421108121500] "Watt-hour" Vector__XXX
 SG_ PwrCnvrtr2TtlEnrgGnrtd : 32|32@1+ (100,0) [0|421108121500] "Watt-hour" Vector__XXX
 SG_ PwrCnvrtr2TtlChrgCnsmd : 64|32@1+ (100,0) [0|421108121500] "Ah" Vector__XXX
 SG_ PwrCnvrtr2TtlChrgGnrtd : 96|32@1+ (100,0) [0|421108121500] "Ah" Vector__XXX

BO_ 2566550270 PC2IAPL: 8 Vector__XXX
 SG_ PwrCnvrtr2PwrLmtdDTUndfndRsn : 0|2@1+ (1,0) [0|3] "" Vector__XXX
 SG_ PwCvt2PwLtdDTDES1CtMx : 2|2@1+ (1,0) [0|3] "" Vector__XXX
 SG_ PwCvt2PwLtdDTDES1CtM : 4|2@1+ (1,0) [0|3] "" Vector__XXX
 SG_ PwCvt2PwLtdDTDES1VtMx : 6|2@1+ (1,0) [0|3] "" Vector__XXX
 SG_ PwCvt2PwLtdDTDES1VtM : 8|2@1+ (1,0) [0|3] "" Vector__XXX
 SG_ PwrCnvrtr2PwrLmtdDTEltrlPwrMxmm : 10|2@1+ (1,0) [0|3] "" Vector__XXX
 SG_ PwrCnvrtr2PwrLmtdDTEltrlPwrMnmm : 12|2@1+ (1,0) [0|3] "" Vector__XXX
 SG_ PwCvt2PwLtdDTDES1PwMx : 14|2@1+ (1,0) [0|3] "" Vector__XXX
 SG_ PwCvt2PwLtdDTDES1PwM : 16|2@1+ (1,0) [0|3] "" Vector__XXX
 SG_ PwrCnvrtr2PwrLmtdDTCrrntMxmm : 18|2@1+ (1,0) [0|3] "" Vector__XXX
 SG_ PwrCnvrtr2PwrLmtdDTCrrntMnmm : 20|2@1+ (1,0) [0|3] "" Vector__XXX
 SG_ PwrCnvrtr2PwrLmtdDTFrqnMxmm : 22|2@1+ (1,0) [0|3] "" Vector__XXX
 SG_ PwrCnvrtr2PwrLmtdDTFrqnMnmm : 24|2@1+ (1,0) [0|3] "" Vector__XXX
 SG_ PwrCnvrtr2PwrLmtdDTInvrtrTmprtr : 28|2@1+ (1,0) [0|3] "" Vector__XXX
 SG_ PwrCnvrtr2PwrLmtdDTTmprtr : 30|2@1+ (1,0) [0|3] "" Vector__XXX
 SG_ PwrCnvrtr2PwrLmtdDTFltCndtn : 32|2@1+ (1,0) [0|3] "" Vector__XXX
 SG_ PwCvt2PwLtdDTAtvCtRtLt : 34|2@1+ (1,0) [0|3] "" Vector__XXX
 SG_ PwCvt2CtLtdDTMCtsts : 38|2@1+ (1,0) [0|3] "" Vector__XXX

BO_ 2566550526 PC1IAPL: 8 Vector__XXX
 SG_ PwrCnvrtr1PwrLmtdDTUndfndRsn : 0|2@1+ (1,0) [0|3] "" Vector__XXX
 SG_ PwCvt1PwLtdDTDES1CtMx : 2|2@1+ (1,0) [0|3] "" Vector__XXX
 SG_ PwCvt1PwLtdDTDES1CtM : 4|2@1+ (1,0) [0|3] "" Vector__XXX
 SG_ PwCvt1PwLtdDTDES1VtMx : 6|2@1+ (1,0) [0|3] "" Vector__XXX
 SG_ PwCvt1PwLtdDTDES1VtM : 8|2@1+ (1,0) [0|3] "" Vector__XXX
 SG_ PwrCnvrtr1PwrLmtdDTEltrlPwrMxmm : 10|2@1+ (1,0) [0|3] "" Vector__XXX
 SG_ PwrCnvrtr1PwrLmtdDTEltrlPwrMnmm : 12|2@1+ (1,0) [0|3] "" Vector__XXX
 SG_ PwCvt1PwLtdDTDES1PwMx : 14|2@1+ (1,0) [0|3] "" Vector__XXX
 SG_ PwCvt1PwLtdDTDES1PwM : 16|2@1+ (1,0) [0|3] "" Vector__XXX
 SG_ PwrCnvrtr1PwrLmtdDTCrrntMxmm : 18|2@1+ (1,0) [0|3] "" Vector__XXX
 SG_ PwrCnvrtr1PwrLmtdDTCrrntMnmm : 20|2@1+ (1,0) [0|3] "" Vector__XXX
 SG_ PwrCnvrtr1PwrLmtdDTFrqnMxmm : 22|2@1+ (1,0) [0|3] "" Vector__XXX
 SG_ PwrCnvrtr1PwrLmtdDTFrqnMnmm : 24|2@1+ (1,0) [0|3] "" Vector__XXX
 SG_ PwrCnvrtr1PwrLmtdDTInvrtrTmprtr : 28|2@1+ (1,0) [0|3] "" Vector__XXX
 SG_ PwrCnvrtr1PwrLmtdDTTmprtr : 30|2@1+ (1,0) [0|3] "" Vector__XXX
 SG_ PwrCnvrtr1PwrLmtdDTFltCndtn : 32|2@1+ (1,0) [0|3] "" Vector__XXX
 SG_ PwCvt1PwLtdDTAtvCtRtLt : 34|2@1+ (1,0) [0|3] "" Vector__XXX
 SG_ PwCvt1CtLtdDTMCtsts : 38|2@1+ (1,0) [0|3] "" Vector__XXX

BO_ 2365224190 PC2IR1: 8 Vector__XXX
 SG_ PowerConverter2Reference1Crc : 0|8@1+ (1,0) [0|250] "count" Vector__XXX
 SG_ PwrCnvrtr2Rfrn1Cntr : 8|4@1+ (1,0) [0|15] "" Vector__XXX
 SG_ PwrCnvrtr2RfrnFrqn : 32|16@1+ (4,0) [0|257020] "rpm" Vector__XXX
 SG_ PowerConverter2ReferencePower : 48|16@1+ (0.0625,0) [0|4015.9375] "kW" Vector__XXX
 SG_ PowerConverter2ReferenceTorque : 16|16@1+ (0.5,0) [0|32127.5] "Nm" Vector__XXX

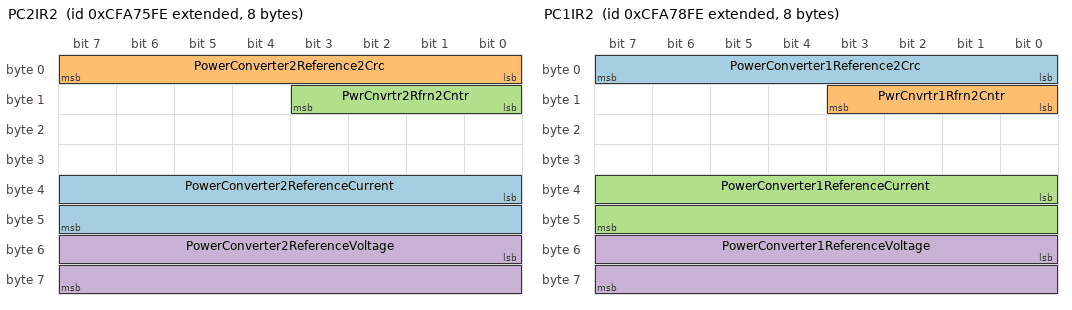
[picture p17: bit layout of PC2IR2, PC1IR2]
BO_ 2365224446 PC2IR2: 8 Vector__XXX
 SG_ PowerConverter2ReferenceCurrent : 32|16@1+ (0.125,0) [0|8031.875] "A" Vector__XXX
 SG_ PowerConverter2Reference2Crc : 0|8@1+ (1,0) [0|250] "count" Vector__XXX
 SG_ PwrCnvrtr2Rfrn2Cntr : 8|4@1+ (1,0) [0|15] "" Vector__XXX
 SG_ PowerConverter2ReferenceVoltage : 48|16@1+ (0.125,0) [0|8031.875] "V" Vector__XXX

BO_ 2566551294 PC2IT: 8 Vector__XXX
 SG_ PowerConverter2Temperature1 : 0|8@1+ (1,-40) [-40|210] "degC" Vector__XXX
 SG_ PowerConverter2Temperature2 : 8|8@1+ (1,-40) [-40|210] "degC" Vector__XXX
 SG_ PowerConverter2Temperature3 : 16|8@1+ (1,-40) [-40|210] "degC" Vector__XXX
 SG_ PowerConverter2Temperature4 : 24|8@1+ (1,-40) [-40|210] "degC" Vector__XXX

BO_ 2566551550 PC1IT: 8 Vector__XXX
 SG_ PowerConverter1Temperature1 : 0|8@1+ (1,-40) [-40|210] "degC" Vector__XXX
 SG_ PowerConverter1Temperature2 : 8|8@1+ (1,-40) [-40|210] "degC" Vector__XXX
 SG_ PowerConverter1Temperature3 : 16|8@1+ (1,-40) [-40|210] "degC" Vector__XXX
 SG_ PowerConverter1Temperature4 : 24|8@1+ (1,-40) [-40|210] "degC" Vector__XXX

BO_ 2365225214 PC1IR2: 8 Vector__XXX
 SG_ PowerConverter1Reference2Crc : 0|8@1+ (1,0) [0|250] "count" Vector__XXX
 SG_ PwrCnvrtr1Rfrn2Cntr : 8|4@1+ (1,0) [0|15] "" Vector__XXX
 SG_ PowerConverter1ReferenceCurrent : 32|16@1+ (0.125,0) [0|8031.875] "A" Vector__XXX
 SG_ PowerConverter1ReferenceVoltage : 48|16@1+ (0.125,0) [0|8031.875] "V" Vector__XXX

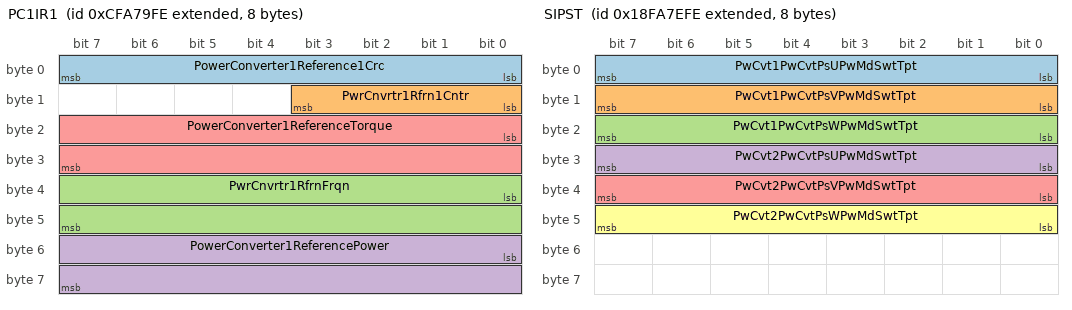
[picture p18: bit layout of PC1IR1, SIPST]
BO_ 2365225470 PC1IR1: 8 Vector__XXX
 SG_ PowerConverter1Reference1Crc : 0|8@1+ (1,0) [0|250] "count" Vector__XXX
 SG_ PwrCnvrtr1Rfrn1Cntr : 8|4@1+ (1,0) [0|15] "" Vector__XXX
 SG_ PwrCnvrtr1RfrnFrqn : 32|16@1+ (4,0) [0|257020] "rpm" Vector__XXX
 SG_ PowerConverter1ReferencePower : 48|16@1+ (0.0625,0) [0|4015.9375] "kW" Vector__XXX
 SG_ PowerConverter1ReferenceTorque : 16|16@1+ (0.5,0) [0|32127.5] "Nm" Vector__XXX

BO_ 2365225726 PC1PC: 8 Vector__XXX
 SG_ PwrCnvrtr1PwrCnvrtrPhsUCrrnt : 0|16@1+ (0.125,0) [0|8031.875] "A" Vector__XXX
 SG_ PwrCnvrtr1PwrCnvrtrPhsVCrrnt : 16|16@1+ (0.125,0) [0|8031.875] "A" Vector__XXX
 SG_ PwrCnvrtr1PwrCnvrtrPhsWCrrnt : 32|16@1+ (0.125,0) [0|8031.875] "A" Vector__XXX

BO_ 2365225982 S21PC: 8 Vector__XXX
 SG_ PwrCnvrtr2PwrCnvrtrPhsUCrrnt : 0|16@1+ (0.125,0) [0|8031.875] "A" Vector__XXX
 SG_ PwrCnvrtr2PwrCnvrtrPhsVCrrnt : 16|16@1+ (0.125,0) [0|8031.875] "A" Vector__XXX
 SG_ PwrCnvrtr2PwrCnvrtrPhsWCrrnt : 32|16@1+ (0.125,0) [0|8031.875] "A" Vector__XXX

BO_ 2365226238 PC1PV: 8 Vector__XXX
 SG_ PwrCnvrtr1PwrCnvrtrPhsUVltg : 0|16@1+ (0.125,0) [0|8031.875] "V" Vector__XXX
 SG_ PwrCnvrtr1PwrCnvrtrPhsVVltg : 16|16@1+ (0.125,0) [0|8031.875] "V" Vector__XXX
 SG_ PwrCnvrtr1PwrCnvrtrPhsWVltg : 32|16@1+ (0.125,0) [0|8031.875] "V" Vector__XXX

BO_ 2365226494 PC2PV: 8 Vector__XXX
 SG_ PwrCnvrtr2PwrCnvrtrPhsUVltg : 0|16@1+ (0.125,0) [0|8031.875] "V" Vector__XXX
 SG_ PwrCnvrtr2PwrCnvrtrPhsVVltg : 16|16@1+ (0.125,0) [0|8031.875] "V" Vector__XXX
 SG_ PwrCnvrtr2PwrCnvrtrPhsWVltg : 32|16@1+ (0.125,0) [0|8031.875] "V" Vector__XXX

BO_ 2566553342 SIPST: 8 Vector__XXX
 SG_ PwCvt1PwCvtPsUPwMdSwtTpt : 0|8@1+ (1,-40) [-40|210] "degC" Vector__XXX
 SG_ PwCvt1PwCvtPsVPwMdSwtTpt : 8|8@1+ (1,-40) [-40|210] "degC" Vector__XXX
 SG_ PwCvt1PwCvtPsWPwMdSwtTpt : 16|8@1+ (1,-40) [-40|210] "degC" Vector__XXX
 SG_ PwCvt2PwCvtPsUPwMdSwtTpt : 24|8@1+ (1,-40) [-40|210] "degC" Vector__XXX
 SG_ PwCvt2PwCvtPsVPwMdSwtTpt : 32|8@1+ (1,-40) [-40|210] "degC" Vector__XXX
 SG_ PwCvt2PwCvtPsWPwMdSwtTpt : 40|8@1+ (1,-40) [-40|210] "degC" Vector__XXX

BO_ 2365227006 PC1PSV: 8 Vector__XXX
 SG_ PwCvt1PwCvtPsUPwMdSwtPwSppVt : 0|16@1+ (0.125,0) [0|8031.875] "V" Vector__XXX
 SG_ PwCvt1PwCvtPsVPwMdSwtPwSppVt : 16|16@1+ (0.125,0) [0|8031.875] "V" Vector__XXX
 SG_ PwCvt1PwCvtPsWPwMdSwtPwSppVt : 32|16@1+ (0.125,0) [0|8031.875] "V" Vector__XXX

BO_ 2365227262 PC2PSV: 8 Vector__XXX
 SG_ PwCvt2PwCvtPsUPwMdSwtPwSppVt : 0|16@1+ (0.125,0) [0|8031.875] "V" Vector__XXX
 SG_ PwCvt2PwCvtPsVPwMdSwtPwSppVt : 16|16@1+ (0.125,0) [0|8031.875] "V" Vector__XXX
 SG_ PwCvt2PwCvtPsWPwMdSwtPwSppVt : 32|16@1+ (0.125,0) [0|8031.875] "V" Vector__XXX

BO_ 2365227518 SIT1: 8 Vector__XXX
 SG_ PwrCnvrtr1PwrCnvrtrACrrntOtpt : 0|16@1+ (0.125,0) [0|8031.875] "A" Vector__XXX
 SG_ PwrCnvrtr2PwrCnvrtrACrrntOtpt : 16|16@1+ (0.125,0) [0|8031.875] "A" Vector__XXX
 SG_ PwCvt1PwCvtPwMdSwtTpt : 32|8@1+ (1,-40) [-40|210] "degC" Vector__XXX
 SG_ PwCvt2PwCvtPwMdSwtTpt : 40|8@1+ (1,-40) [-40|210] "degC" Vector__XXX

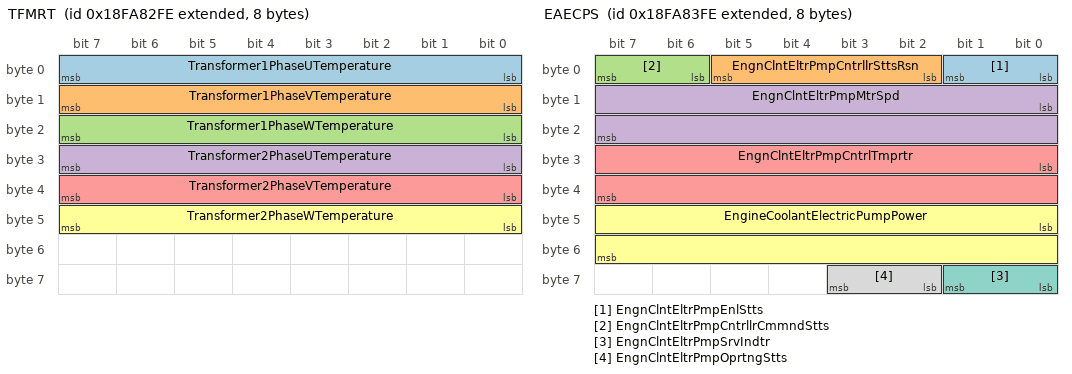
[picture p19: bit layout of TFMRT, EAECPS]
BO_ 2566554366 TFMRT: 8 Vector__XXX
 SG_ Transformer1PhaseUTemperature : 0|8@1+ (1,-40) [-40|210] "degC" Vector__XXX
 SG_ Transformer1PhaseVTemperature : 8|8@1+ (1,-40) [-40|210] "degC" Vector__XXX
 SG_ Transformer1PhaseWTemperature : 16|8@1+ (1,-40) [-40|210] "degC" Vector__XXX
 SG_ Transformer2PhaseUTemperature : 24|8@1+ (1,-40) [-40|210] "degC" Vector__XXX
 SG_ Transformer2PhaseVTemperature : 32|8@1+ (1,-40) [-40|210] "degC" Vector__XXX
 SG_ Transformer2PhaseWTemperature : 40|8@1+ (1,-40) [-40|210] "degC" Vector__XXX

BO_ 2566554622 EAECPS: 8 Vector__XXX
 SG_ EngnClntEltrPmpEnlStts : 0|2@1+ (1,0) [0|3] "" Vector__XXX
 SG_ EngnClntEltrPmpCntrllrSttsRsn : 2|4@1+ (1,0) [0|15] "" Vector__XXX
 SG_ EngnClntEltrPmpCntrllrCmmndStts : 6|2@1+ (1,0) [0|3] "" Vector__XXX
 SG_ EngnClntEltrPmpMtrSpd : 8|16@1+ (0.5,0) [0|32127.5] "rpm" Vector__XXX
 SG_ EngnClntEltrPmpCntrlTmprtr : 24|16@1+ (0.03125,-273) [-273|1734.96875] "degC" Vector__XXX
 SG_ EngineCoolantElectricPumpPower : 40|16@1+ (0.5,0) [0|32127.5] "W" Vector__XXX
 SG_ EngnClntEltrPmpSrvIndtr : 56|2@1+ (1,0) [0|3] "" Vector__XXX
 SG_ EngnClntEltrPmpOprtngStts : 58|2@1+ (1,0) [0|3] "" Vector__XXX

CM_ BO_ 2364747006 "High Voltage Energy Storage Pack 25 Module Status 1";
CM_ SG_ 2364747006 Hvesp25Module1OperationalStatus "HVESP25 Module 1 Operational Status: Operational Status of Module 1 in this High Voltage Energy Storage Pack Instance.  Not Operational is used when the module is initializing or not able to function (e.g. internal module level monitors have failed)....";
CM_ SG_ 2364747006 Hvesp25Module2OperationalStatus "HVESP25 Module 2 Operational Status: Operational Status of Module 2 in this High Voltage Energy Storage Pack Instance.  Not Operational is used when the module is initializing or not able to function (e.g. internal module level monitors have failed)....";
CM_ SG_ 2364747006 Hvesp25Module3OperationalStatus "HVESP25 Module 3 Operational Status: Operational Status of Module 3 in this High Voltage Energy Storage Pack Instance.  Not Operational is used when the module is initializing or not able to function (e.g. internal module level monitors have failed)....";
CM_ SG_ 2364747006 Hvesp25Module4OperationalStatus "HVESP25 Module 4 Operational Status: Operational Status of Module 4 in this High Voltage Energy Storage Pack Instance.  Not Operational is used when the module is initializing or not able to function (e.g. internal module level monitors have failed)....";
CM_ SG_ 2364747006 Hvesp25Module5OperationalStatus "HVESP25 Module 5 Operational Status: Operational Status of Module 5 in this High Voltage Energy Storage Pack Instance.  Not Operational is used when the module is initializing or not able to function (e.g. internal module level monitors have failed)....";
CM_ SG_ 2364747006 Hvesp25Module6OperationalStatus "HVESP25 Module 6 Operational Status: Operational Status of Module 6 in this High Voltage Energy Storage Pack Instance.  Not Operational is used when the module is initializing or not able to function (e.g. internal module level monitors have failed)....";
CM_ SG_ 2364747006 Hvesp25Module7OperationalStatus "HVESP25 Module 7 Operational Status: Operational Status of Module 7 in this High Voltage Energy Storage Pack Instance.  Not Operational is used when the module is initializing or not able to function (e.g. internal module level monitors have failed)....";
CM_ SG_ 2364747006 Hvesp25Module8OperationalStatus "HVESP25 Module 8 Operational Status: Operational Status of Module 8 in this High Voltage Energy Storage Pack Instance.  Not Operational is used when the module is initializing or not able to function (e.g. internal module level monitors have failed)....";
CM_ SG_ 2364747006 Hvesp25Module9OperationalStatus "HVESP25 Module 9 Operational Status: Operational Status of Module 9 in this High Voltage Energy Storage Pack Instance.  Not Operational is used when the module is initializing or not able to function (e.g. internal module level monitors have failed)....";
CM_ SG_ 2364747006 Hvsp25Mdl10OprtnlStts "HVESP25 Module 10 Operational Status: Operational Status of Module 10 in this High Voltage Energy Storage Pack Instance.  Not Operational is used when the module is initializing or not able to function (e.g. internal module level monitors have failed...";
CM_ SG_ 2364747006 Hvsp25Mdl11OprtnlStts "HVESP25 Module 11 Operational Status: Operational Status of Module 11 in this High Voltage Energy Storage Pack Instance.  Not Operational is used when the module is initializing or not able to function (e.g. internal module level monitors have failed...";
CM_ SG_ 2364747006 Hvsp25Mdl12OprtnlStts "HVESP25 Module 12 Operational Status: Operational Status of Module 12 in this High Voltage Energy Storage Pack Instance.  Not Operational is used when the module is initializing or not able to function (e.g. internal module level monitors have failed...";
CM_ SG_ 2364747006 Hvsp25Mdl13OprtnlStts "HVESP25 Module 13 Operational Status: Operational Status of Module 13 in this High Voltage Energy Storage Pack Instance.  Not Operational is used when the module is initializing or not able to function (e.g. internal module level monitors have failed...";
CM_ SG_ 2364747006 Hvsp25Mdl14OprtnlStts "HVESP25 Module 14 Operational Status: Operational Status of Module 14 in this High Voltage Energy Storage Pack Instance.  Not Operational is used when the module is initializing or not able to function (e.g. internal module level monitors have failed...";
CM_ SG_ 2364747006 Hvsp25Mdl15OprtnlStts "HVESP25 Module 15 Operational Status: Operational Status of Module 15 in this High Voltage Energy Storage Pack Instance.  Not Operational is used when the module is initializing or not able to function (e.g. internal module level monitors have failed...";
CM_ SG_ 2364747006 Hvsp25Mdl16OprtnlStts "HVESP25 Module 16 Operational Status: Operational Status of Module 16 in this High Voltage Energy Storage Pack Instance.  Not Operational is used when the module is initializing or not able to function (e.g. internal module level monitors have failed...";
CM_ SG_ 2364747006 Hvsp25Mdl17OprtnlStts "HVESP25 Module 17 Operational Status: Operational Status of Module 17 in this High Voltage Energy Storage Pack Instance.  Not Operational is used when the module is initializing or not able to function (e.g. internal module level monitors have failed...";
CM_ SG_ 2364747006 Hvsp25Mdl18OprtnlStts "HVESP25 Module 18 Operational Status: Operational Status of Module 18 in this High Voltage Energy Storage Pack Instance.  Not Operational is used when the module is initializing or not able to function (e.g. internal module level monitors have failed...";
CM_ SG_ 2364747006 Hvsp25Mdl19OprtnlStts "HVESP25 Module 19 Operational Status: Operational Status of Module 19 in this High Voltage Energy Storage Pack Instance.  Not Operational is used when the module is initializing or not able to function (e.g. internal module level monitors have failed...";
CM_ SG_ 2364747006 Hvsp25Mdl20OprtnlStts "HVESP25 Module 20 Operational Status: Operational Status of Module 20 in this High Voltage Energy Storage Pack Instance.  Not Operational is used when the module is initializing or not able to function (e.g. internal module level monitors have failed...";
CM_ SG_ 2364747006 Hvsp25Mdl21OprtnlStts "HVESP25 Module 21 Operational Status: Operational Status of Module 21 in this High Voltage Energy Storage Pack Instance.  Not Operational is used when the module is initializing or not able to function (e.g. internal module level monitors have failed...";
CM_ SG_ 2364747006 Hvsp25Mdl22OprtnlStts "HVESP25 Module 22 Operational Status: Operational Status of Module 22 in this High Voltage Energy Storage Pack Instance.  Not Operational is used when the module is initializing or not able to function (e.g. internal module level monitors have failed...";
CM_ SG_ 2364747006 Hvsp25Mdl23OprtnlStts "HVESP25 Module 23 Operational Status: Operational Status of Module 23 in this High Voltage Energy Storage Pack Instance.  Not Operational is used when the module is initializing or not able to function (e.g. internal module level monitors have failed...";
CM_ SG_ 2364747006 Hvsp25Mdl24OprtnlStts "HVESP25 Module 24 Operational Status: Operational Status of Module 24 in this High Voltage Energy Storage Pack Instance.  Not Operational is used when the module is initializing or not able to function (e.g. internal module level monitors have failed...";
CM_ SG_ 2364747006 Hvsp25Mdl25OprtnlStts "HVESP25 Module 25 Operational Status: Operational Status of Module 25 in this High Voltage Energy Storage Pack Instance.  Not Operational is used when the module is initializing or not able to function (e.g. internal module level monitors have failed...";
CM_ SG_ 2364747006 Hvsp25Mdl26OprtnlStts "HVESP25 Module 26 Operational Status: Operational Status of Module 26 in this High Voltage Energy Storage Pack Instance.  Not Operational is used when the module is initializing or not able to function (e.g. internal module level monitors have failed...";
CM_ SG_ 2364747006 Hvsp25Mdl27OprtnlStts "HVESP25 Module 27 Operational Status: Operational Status of Module 27 in this High Voltage Energy Storage Pack Instance.  Not Operational is used when the module is initializing or not able to function (e.g. internal module level monitors have failed...";
CM_ SG_ 2364747006 Hvsp25Mdl28OprtnlStts "HVESP25 Module 28 Operational Status: Operational Status of Module 28 in this High Voltage Energy Storage Pack Instance.  Not Operational is used when the module is initializing or not able to function (e.g. internal module level monitors have failed...";
CM_ SG_ 2364747006 Hvsp25Mdl29OprtnlStts "HVESP25 Module 29 Operational Status: Operational Status of Module 29 in this High Voltage Energy Storage Pack Instance.  Not Operational is used when the module is initializing or not able to function (e.g. internal module level monitors have failed...";
CM_ SG_ 2364747006 Hvsp25Mdl30OprtnlStts "HVESP25 Module 30 Operational Status: Operational Status of Module 30 in this High Voltage Energy Storage Pack Instance.  Not Operational is used when the module is initializing or not able to function (e.g. internal module level monitors have failed...";
CM_ SG_ 2364747006 Hvsp25Mdl31OprtnlStts "HVESP25 Module 31 Operational Status: Operational Status of Module 31 in this High Voltage Energy Storage Pack Instance.  Not Operational is used when the module is initializing or not able to function (e.g. internal module level monitors have failed...";
CM_ SG_ 2364747006 Hvsp25Mdl32OprtnlStts "HVESP25 Module 32 Operational Status: Operational Status of Module 32 in this High Voltage Energy Storage Pack Instance.  Not Operational is used when the module is initializing or not able to function (e.g. internal module level monitors have failed...";
CM_ BO_ 2364747262 "High Voltage Energy Storage Pack 25 Thermal Management System Status 1";
CM_ SG_ 2364747262 Hvsp25ThrmlMngmntSstmSlInptPwr "HVESP25 Thermal Management System SLI Input Power: This is the low-voltage power consumed by this HVES Thermal Management System (TMS).This parameter is for one of multiple packs in an HVESS.  If there is only one pack in the system, the HVESS parame...";
CM_ SG_ 2364747262 Hvsp25TMtSstHVtIptPw "HVESP25 Thermal Management System High-Voltage Input Power: This is the high-voltage power consumed by this HVES Thermal Management System (TMS).This parameter is for one of multiple packs in an HVESS.  If there is only one pack in the system, the HV...";
CM_ SG_ 2364747262 Hvsp25ThrmlMngmntSstmCmprssrSpd "HVESP25 Thermal Management System Compressor Speed: When this High Voltage Energy Storage Pack Thermal Management System is equipped with an active cooling system (e.g. air conditioner), this is the Compressor Speed.This parameter is for one of multi...";
CM_ SG_ 2364747262 Hvsp25ThrmlMngmntSstmRltvHmdt "HVESP25 Thermal Management System Relative Humidty: When this High Voltage Energy Storage Pack Thermal Management System is equipped with a relative humidity sensor, this is the  measured Relative Humidity.This parameter is for one of multiple packs ...";
CM_ SG_ 2364747262 Hvsp25ThrmlMngmntSstmHtrStts "HVESP25 Thermal Management System Heater Status: The state of this High Voltage Energy Storage Pack heaterThis parameter is for one of multiple packs in an HVESS.  If there is only one pack in the system, the HVESS parameters should be used. If there...";
CM_ SG_ 2364747262 Hvsp25ThrmlMngmntSstmHvlStts "HVESP25 Thermal Management System HVIL Status: In multiple HVES configurations, this is the status of the High Voltage Interlock Loop from the viewpoint of this Thermal Management System.00b = HVIL Closed01b = HVIL Open10b = Error11b = Not AvailableT...";
CM_ SG_ 2364747262 Hvsp25ThrmlMngmntSstmMd "HVESP25 Thermal Management System Mode: Indicates the operating mode of the Thermal Management System.  The heat transfer medium may be (e.g. liquid or air).  The cooling system may be fans, liquid coolant, or a combination of mediums.  The system ma...";
CM_ SG_ 2364747262 Hvsp25ThrmlMngmntSstmClntLvl "HVESP25 Thermal Management System Coolant Level: Indicates the coolant level in this HVES Thermal Management System (TMS).This parameter is for one of multiple packs in an HVESS.  If there is only one pack in the system, the HVESS parameters should b...";
CM_ BO_ 2364747518 "High Voltage Energy Storage Pack 25 Data 8";
CM_ SG_ 2364747518 Hvsp25HghstCllVltgMdlNmr "HVESP25 Highest Cell Voltage Module Number: Identifies the location of the module containing SPN 17285 (HVESP25 Highest Cell Voltage).This parameter is for one of multiple packs in an HVESS. If there is only one pack in the system, the HVESS paramete...";
CM_ SG_ 2364747518 Hvsp25HghstCllVltgCllNmr "HVESP25 Highest Cell Voltage Cell Number: Identifies the location of SPN 17285 (HVESP25 Highest Cell Voltage) within SPN 17365 (HVESP25 Highest Cell Voltage Module Number).This parameter is for one of multiple packs in an HVESS. If there is only one ...";
CM_ SG_ 2364747518 Hvsp25LwstCllVltgMdlNmr "HVESP25 Lowest Cell Voltage Module Number: Identifies the location of the module containing SPN 17286 (HVESP25 Lowest Cell Voltage).This parameter is for one of multiple packs in an HVESS. If there is only one pack in the system, the HVESS parameters...";
CM_ SG_ 2364747518 Hvsp25LwstCllVltgCllNmr "HVESP25 Lowest Cell Voltage Cell Number: Identifies the location of SPN 17286 (HVESP25 Lowest Cell Voltage) within SPN 17367 (HVESP25 Lowest Cell Voltage Module Number).This parameter is for one of multiple packs in an HVESS. If there is only one pac...";
CM_ SG_ 2364747518 Hvesp25AverageCellVoltage "HVESP25 Average Cell Voltage: The average cell voltage in this High Voltage Energy Storage Pack instance.This parameter is for one of multiple packs in an HVESS.  If there is only one pack in the system, the HVESS parameters should be used. If there ...";
CM_ BO_ 2364747774 "High Voltage Energy Storage Pack 25 Data 9";
CM_ SG_ 2364747774 Hvsp25HghstCllTmprtrMdlNmr "HVESP25 Highest Cell Temperature Module Number: Identifies the location of the module containing SPN 17288 (HVESP25 Highest Cell Temperature).This parameter is for one of multiple packs in an HVESS. If there is only one pack in the system, the HVESS ...";
CM_ SG_ 2364747774 Hvsp25HghstCllTmprtrCllNmr "HVESP25 Highest Cell Temperature Cell Number: Identifies the location of SPN 17288 (HVESP25 Highest Cell Temperature) within SPN 17370 (HVESP25 Highest Cell Temperature Module Number).This parameter is for one of multiple packs in an HVESS. If there ...";
CM_ SG_ 2364747774 Hvsp25LwstCllTmprtrMdlNmr "HVESP25 Lowest Cell Temperature Module Number: Identifies the location of the module containing SPN 17289 (HVESP25 Lowest Cell Temperature).This parameter is for one of multiple packs in an HVESS. If there is only one pack in the system, the HVESS pa...";
CM_ SG_ 2364747774 Hvsp25LwstCllTmprtrCllNmr "HVESP25 Lowest Cell Temperature Cell Number: Identifies the location of SPN 17289 (HVESP25 Lowest Cell Temperature) within SPN 17372 (HVESP25 Lowest Cell Temperature Module Number).This parameter is for one of multiple packs in an HVESS. If there is ...";
CM_ SG_ 2364747774 Hvess25ThermalEventDetected "HVESS25 Thermal Event Detected: A sensor has detected the presence of a thermal event at or near High Voltage Energy Storage Pack instance.00b = No Thermal Event Detected01b = Thermal Event Detected10b = Error11b = Not availableThis parameter is for ...";
CM_ SG_ 2364747774 Hvsp25Dt9EmdddIntgrtSpprt "HVESP25 Data 9 Embedded Integrity Support: Indicates SPN 23048 (HVESP25 Data 9 CRC) and SPN 23047 (HVESP25 Data 9 Counter) are supported by the sender.00b = Embedded CRC and Counter are supported by the sender01b = Protection is provided using an ext...";
CM_ SG_ 2364747774 Hvesp25Data9Counter "HVESP25 Data 9 Counter: The message counter is used to detect situations where the transmitting ECU malfunction repeats the same frame all the time. The receiver of the information may use the counter parameter to detect this situation. The transmitt...";
CM_ SG_ 2364747774 Hvesp25Data9Crc "HVESP25 Data 9 CRC: The CRC is defined as follows: - Length: 8 bits- Polynomial: x^8+x^5+x^3+x^2+x+1- Initial Value: FFh- Input Data Reflection: Not reflected- Result Data Reflection: Not reflected- XOR value: FFh SAE makes no claim of the functional...";
CM_ BO_ 2364748030 "High Voltage Energy Storage Pack 25 Data 10";
CM_ SG_ 2364748030 Hvsp25HghstCllSttOfChrgMdlNmr "HVESP25 Highest Cell State of Charge Module Number: Identifies the location of the module containing SPN 17298 (HVESP25 Highest Cell State of Charge).This parameter is for one of multiple packs in an HVESS. If there is only one pack in the system, th...";
CM_ SG_ 2364748030 Hvsp25HghstCllSttOfChrgCllNmr "HVESP25 Highest Cell State of Charge Cell Number: Identifies the location of SPN 17298 (HVESP25 Highest Cell State of Charge) within SPN 17374 (HVESP25 Highest Cell State of Charge Module Number).This parameter is for one of multiple packs in an HVES...";
CM_ SG_ 2364748030 Hvsp25LwstCllSttOfChrgMdlNmr "HVESP25 Lowest Cell State of Charge Module Number: Identifies the location of the module containing SPN 17297 (HVESP25 Lowest Cell State of Charge).This parameter is for one of multiple packs in an HVESS. If there is only one pack in the system, the ...";
CM_ SG_ 2364748030 Hvsp25LwstCllSttOfChrgCllNmr "HVESP25 Lowest Cell State of Charge Cell Number: Identifies the location of SPN 17297 (HVESP25 Lowest Cell State of Charge) within SPN 17376 (HVESP25 Lowest Cell State of Charge Module Number).This parameter is for one of multiple packs in an HVESS. ...";
CM_ SG_ 2364748030 Hvsp25HghVltgBsAtvIsltnTstRslts "HVESP25 High-Voltage Bus Active Isolation Test Results: The isolation resistance expressed in Ohms per Volt that resulted from the High-Voltage Bus Active Isolation Test.See SPN 17310 (HVESP25 High-Voltage Bus Active Isolation Test Status) for test s...";
CM_ SG_ 2364748030 Hvsp25HVtBsPssvIstTstRsts "HVESP25 High-Voltage Bus Passive Isolation Test Results: The isolation resistance expressed in Ohms per Volt that resulted from the High-Voltage Bus Passive Isolation Test.See SPN 17311 (HVESP25 High-Voltage Bus Passive Isolation Test Status) for tes...";
CM_ BO_ 2364748286 "High Voltage Energy Storage Pack 25 Data 11";
CM_ SG_ 2364748286 Hvsp25BsVltgNgtvTChsssGrndVltg "HVESP25 Bus Voltage Negative to Chassis Ground Voltage: Voltage difference between the most negative terminal of the HVES battery and chassis measured on the hybrid or EV system bus side (not the battery side) of any HVES contained output contactor. ...";
CM_ SG_ 2364748286 Hvsp25VltgLvlNgtvTChsssGrndVltg "HVESP25 Voltage Level Negative to Chassis Ground Voltage: Voltage difference between the most negative terminal of the HVES battery and chassis measured at the battery side of any HVES contained output contactor.  This voltage may be used for system ...";
CM_ SG_ 2364748286 Hvesp25ActualChargeRate "HVESP25 Actual Charge Rate: This signal represents the actual present charge rate of this High Voltage Energy Storage Pack instance.This parameter is for one of multiple packs in an HVESS. If there is only one pack in the system, the HVESS parameters...";
CM_ BO_ 2364748542 "High Voltage Energy Storage Pack 26 Status 2";
CM_ SG_ 2364748542 Hvsp26DshrgPwrLmtDTSttOfChrg "HVESP26 Discharge Power Limit Due to State of Charge: Indicates whether or not discharge power of this HVES instance is being limited due to state of charge.This parameter is for one of multiple packs in an HVESS.  If there is only one pack in the sy...";
CM_ SG_ 2364748542 Hvsp26DshrgPwrLmtDTBttrTmprtr "HVESP26 Discharge Power Limit Due to Battery Temperature: Indicates whether or not discharge power of this HVES instance is being limited due to battery temperature.This parameter is for one of multiple packs in an HVESS.  If there is only one pack i...";
CM_ SG_ 2364748542 Hvsp26DsPwLtDTBttDstCdt "HVESP26 Discharge Power Limit Due to Battery Diagnostic Condition: Indicates whether or not discharge power of this HVES instance is being limited due to a battery diagnostic condition.This parameter is for one of multiple packs in an HVESS.  If ther...";
CM_ SG_ 2364748542 Hvsp26DsPwLtDTBttOCVt "HVESP26 Discharge Power Limit Due to Battery or Cell Voltage: Indicates whether or not discharge power of this HVES instance is being limited due to a battery or cell voltage level.This parameter is for one of multiple packs in an HVESS.  If there is...";
CM_ SG_ 2364748542 Hvsp26DshrgPwrLmtDTBttrCrrnt "HVESP26 Discharge Power Limit Due to Battery Current: Indicates whether or not discharge power of this HVES instance is being limited due to battery current.This parameter is for one of multiple packs in an HVESS.  If there is only one pack in the sy...";
CM_ SG_ 2364748542 Hvsp26DshrgPwrLmtDTAnUndfndCs "HVESP26 Discharge Power Limit Due to an Undefined Cause: Indicates whether or not discharge power of this HVES instance is being limited due to an undefined cause.This parameter is for one of multiple packs in an HVESS.  If there is only one pack in ...";
CM_ SG_ 2364748542 Hvsp26ChrgPwrLmtDTSttOfChrg "HVESP26 Charge Power Limit Due to State of Charge: Indicates whether or not charge power of this HVES instance is being limited due to state of charge.This parameter is for one of multiple packs in an HVESS.  If there is only one pack in the system, ...";
CM_ SG_ 2364748542 Hvsp26ChrgPwrLmtDTBttrTmprtr "HVESP26 Charge Power Limit Due to Battery Temperature: Indicates whether or not charge power of this HVES instance is being limited due to battery temperature.This parameter is for one of multiple packs in an HVESS.  If there is only one pack in the ...";
CM_ SG_ 2364748542 Hvsp26CPwLtDTBttDstCdt "HVESP26 Charge Power Limit Due to Battery Diagnostic Condition: Indicates whether or not charge power of this HVES instance is being limited due to a battery diagnostic condition.This parameter is for one of multiple packs in an HVESS.  If there is o...";
CM_ SG_ 2364748542 Hvsp26ChrgPwrLmtDTBttrOrCllVltg "HVESP26 Charge Power Limit Due to Battery or Cell Voltage: Indicates whether or not charge power of this HVES instance is being limited due to a battery or cell voltage level.This parameter is for one of multiple packs in an HVESS.  If there is only ...";
CM_ SG_ 2364748542 Hvsp26ChrgPwrLmtDTBttrCrrnt "HVESP26 Charge Power Limit Due to Battery Current: Indicates whether or not charge power of this HVES instance is being limited due to battery current.This parameter is for one of multiple packs in an HVESS.  If there is only one pack in the system, ...";
CM_ SG_ 2364748542 Hvsp26ChrgPwrLmtDTAnUndfndCs "HVESP26 Charge Power Limit Due to an Undefined Cause: Indicates whether or not charge power of this HVES instance is being limited due to an undefined cause.This parameter is for one of multiple packs in an HVESS.  If there is only one pack in the sy...";
CM_ BO_ 2364748798 "High Voltage Energy Storage Pack 26 Data 1";
CM_ SG_ 2364748798 Hvesp26AvailableDischargePower "HVESP26 Available Discharge Power: The rate at which this High Voltage Energy Storage Pack instance can currently provide energy for propulsion or other uses.This parameter is for one of multiple packs in an HVESS.  If there is only one pack in the s...";
CM_ SG_ 2364748798 Hvesp26AvailableChargePower "HVESP26 Available Charge Power: The rate at which this High Voltage Energy Storage Pack instance can currently receive energy from a regenerative or recharging system.This parameter is for one of multiple packs in an HVESS.  If there is only one pack...";
CM_ SG_ 2364748798 Hvesp26VoltageLevel "HVESP26 Voltage Level: The voltage level of this High Voltage Energy Storage Pack instance. This parameter should be synchronized with SPN 17425 (HVESP26 Current) such that a realized power value can be calculated. If the HVES component physically co...";
CM_ SG_ 2364748798 Hvesp26Current "HVESP26 Current: The current in or out of this High Voltage Energy Storage Pack instance. This parameter should be synchronized with SPN 17424 (HVESP26 Voltage Level) such that a realized power value can be calculated. This parameter is defined from ...";
CM_ BO_ 2364749054 "High Voltage Energy Storage Pack 26 Data 2";
CM_ SG_ 2364749054 Hvesp26FastUpdateStateOfCharge "HVESP26 Fast Update State of Charge: Indicates this High Voltage Energy Storage Pack instance state of charge. 0% means no charge remaining, 100% means the system is fully charged in terms of physical limits of this energy storage pack instance. Acce...";
CM_ SG_ 2364749054 Hvesp26HighestCellVoltage "HVESP26 Highest Cell Voltage: The highest voltage level reported by any cell in this High Voltage Energy Storage Pack instance. If a single voltage sensor covers more than one cell, the value in this parameter is for the smallest group of cells measu...";
CM_ SG_ 2364749054 Hvesp26LowestCellVoltage "HVESP26 Lowest Cell Voltage: The lowest voltage level reported by any cell in this High Voltage Energy Storage Pack instance. If a single voltage sensor covers more than one cell, the value in this parameter is for the smallest group of cells measure...";
CM_ SG_ 2364749054 Hvsp26CllVltgDffrntlStts "HVESP26 Cell Voltage Differential Status: Indicates whether or not the differential between the highest and lowest cell voltages are within acceptable limits, according to this High Voltage Energy Storage Pack instance. The actual voltage differentia...";
CM_ BO_ 2364749310 "High Voltage Energy Storage Pack 26 Data 3";
CM_ SG_ 2364749310 Hvesp26HighestCellTemperature "HVESP26 Highest Cell Temperature: The highest temperature level reported by any cell in this High Voltage Energy Storage Pack instance. If a single temperature sensor covers more than one cell, the value in this parameter is for the smallest group of...";
CM_ SG_ 2364749310 Hvesp26LowestCellTemperature "HVESP26 Lowest Cell Temperature: The lowest temperature level reported by any cell in this High Voltage Energy Storage Pack instance. If a single temperature sensor covers more than one cell, the value in this parameter is for the smallest group of c...";
CM_ SG_ 2364749310 Hvesp26AverageCellTemperature "HVESP26 Average Cell Temperature: The average temperature level of all cells in this High Voltage Energy Storage Pack instance.This parameter is for one of multiple packs in an HVESS.  If there is only one pack in the system, the HVESS parameters sho...";
CM_ SG_ 2364749310 Hvsp26CllTmprtrDffrntlStts "HVESP26 Cell Temperature Differential Status: Indicates whether or not the differential between the highest and lowest cell temperatures are within acceptable limits per this High Voltage Energy Storage Pack instance. The actual temperature different...";
CM_ BO_ 2364749566 "High Voltage Energy Storage Pack 26 Data 4";
CM_ SG_ 2364749566 Hvesp26DischargeCapacity "HVESP26 Discharge Capacity: The amount of stored electrical charge in this High Voltage Energy Storage Pack instance that is available for use by the hybrid or EV system, i.e. 'how full is the tank'. See SPN 17464 (HVESP26 Discharge Energy Capacity) ...";
CM_ SG_ 2364749566 Hvesp26ChargeCapacity "HVESP26 Charge Capacity: The amount of unused electrical charge storage in this High Voltage Energy Storage Pack instance that is available to be filled by charging, i.e. 'how much empty space is remaining in the tank'. See SPN 17465 (HVESP26 Charge ...";
CM_ SG_ 2364749566 Hvesp26CellBalancingCount "HVESP26 Cell Balancing Count: The number of cells that are currently being balanced in this High Voltage Energy Storage Pack instance.This parameter is for one of multiple packs in an HVESS.  If there is only one pack in the system, the HVESS paramet...";
CM_ BO_ 2364749822 "High Voltage Energy Storage Pack 26 Data 5";
CM_ SG_ 2364749822 Hvesp26LowestCellStateOfCharge "HVESP26 Lowest Cell State of Charge: Indicates the state of charge of the lowest-charged cell in this High Voltage Energy Storage Pack instance. 0% means no charge remaining, 100% means the cell is fully charged. If a single state of charge value cov...";
CM_ SG_ 2364749822 Hvesp26HighestCellStateOfCharge "HVESP26 Highest Cell State of Charge: Indicates the state of charge of the highest-charged cell in this High Voltage Energy Storage Pack instance. 0% means no charge remaining, 100% means the cell is fully charged. If a single state of charge value c...";
CM_ SG_ 2364749822 Hvsp26MxmmInstntnsDshrgCrrntLmt "HVESP26 Maximum Instantaneous Discharge Current Limit: The maximum instantaneous current flow limit out of this High Voltage Energy Storage Pack instance. This parameter is defined from the high voltage energy storage pack's point of view and should ...";
CM_ SG_ 2364749822 Hvsp26MxmmInstntnsChrgCrrntLmt "HVESP26 Maximum Instantaneous Charge Current Limit: The maximum instantaneous current flow limit into this High Voltage Energy Storage Pack instance. This parameter is defined from the high voltage energy storage pack's point of view and should refle...";
CM_ BO_ 2364750078 "High Voltage Energy Storage Pack 26 Data 6";
CM_ SG_ 2364750078 Hvesp26BusVoltage "HVESP26 Bus Voltage: The voltage level of the high voltage bus, as measured by this High Voltage Energy Storage Pack instance on the bus side (not the battery side) of its contactors.This parameter is for one of multiple packs in an HVESS.  If there ...";
CM_ SG_ 2364750078 Hvesp26IgnitionVoltage "HVESP26 Ignition Voltage: The voltage level at the ignition input of this High Voltage Energy Storage Pack controller.This parameter is for one of multiple packs in an HVESS.  If there is only one pack in the system, the HVESS parameters should be us...";
CM_ SG_ 2364750078 Hvesp26IntakeCoolantTemperature "HVESP26 Intake Coolant Temperature: The temperature of liquid coolant as it enters this High Voltage Energy Storage Pack instance.This parameter is for one of multiple packs in an HVESS.  If there is only one pack in the system, the HVESS parameters ...";
CM_ SG_ 2364750078 Hvesp26OutletCoolantTemperature "HVESP26 Outlet Coolant Temperature: The temperature of liquid coolant as it exits this High Voltage Energy Storage Pack instance.This parameter is for one of multiple packs in an HVESS.  If there is only one pack in the system, the HVESS parameters s...";
CM_ SG_ 2364750078 Hvesp26ElectronicsTemperature "HVESP26 Electronics Temperature: The temperature of the electronics or control modules in this High Voltage Energy Storage Pack instance.  If there are multiple temperature sensors then this parameter would be set to the maximum sensor reading.This p...";
CM_ SG_ 2364750078 Hvesp26Temperature "HVESP26 Temperature: The temperature of this High Voltage Energy Storage Pack instance. The value may be determined from a unique sensor specifically for this purpose, or by aggregating various temperature sensor readings within the pack.This paramet...";
CM_ BO_ 2364750334 "High Voltage Energy Storage Pack 26 Status 1";
CM_ SG_ 2364750334 Hvsp26HghVltgBsPstvCnttrStt "HVESP26 High-Voltage Bus (Positive) Contactor State: Position of this High Voltage Energy Storage Pack instance positive side bus contactor.  When this contactor is closed, the positive side of this HVES instance is connected to the positive side of ...";
CM_ SG_ 2364750334 Hvsp26HghVltgBsNgtvCnttrStt "HVESP26 High-Voltage Bus (Negative) Contactor State: Position of this High Voltage Energy Storage Pack instance negative side bus contactor. When this contactor is closed, the negative side of this HVES instance is connected to the negative side of t...";
CM_ SG_ 2364750334 Hvsp26HghVltgBsDsnntFrwrnng "HVESP26 High-Voltage Bus Disconnect Forewarning: Indicates that this High Voltage Energy Storage Pack instance is about to disconnect from the high voltage bus due to unacceptable conditions.This parameter is for one of multiple packs in an HVESS. If...";
CM_ SG_ 2364750334 Hvsp26HghVltgBsPrChrgRlStt "HVESP26 High-Voltage Bus Pre-Charge Relay State: Position of the high-voltage bus contactor pre-charge relay.  When this relay is closed, this High Voltage Energy Storage Pack instance is bringing the high-voltage bus up to its operating level.This p...";
CM_ SG_ 2364750334 Hvsp26CntrOfPkCnttrStt "HVESP26 Center of Pack Contactor State: Position of the center high-voltage contactor. When this contactor is closed, the positive half of this High Voltage Energy Storage Pack instance is connected to the negative half. If a system controls the posi...";
CM_ SG_ 2364750334 Hvsp26HghVltgBsAtvIsltnTstStts "HVESP26 High-Voltage Bus Active Isolation Test Status: Status of the high-voltage bus electrical active isolation test as performed by this High Voltage Energy Storage Pack instance.This parameter is for one of multiple packs in an HVESS. If there is...";
CM_ SG_ 2364750334 Hvsp26HghVltgBsPssvIsltnTstStts "HVESP26 High-Voltage Bus Passive Isolation Test Status: Status of the high-voltage bus electrical passive isolation test as performed by this High Voltage Energy Storage Pack instance.This parameter is for one of multiple packs in an HVESS. If there ...";
CM_ SG_ 2364750334 Hvesp26HvilStatus "HVESP26 HVIL Status: Status of the High Voltage Interlock Loop from the viewpoint of this High Voltage Energy Storage Pack instance.This parameter is for one of multiple packs in an HVESS. If there is only one pack in the system, the HVESS parameters...";
CM_ SG_ 2364750334 Hvesp26InertiaSwitchStatus "HVESP26 Inertia Switch Status: Switch indicating that an impact has been sensed by this High Voltage Energy Storage Pack instance. The impact indication may require action by another controller, or by this HVES instance itself.  For example, a contro...";
CM_ SG_ 2364750334 Hvesp26StateOfChargeStatus "HVESP26 State of Charge Status: Status of this High Voltage Energy Storage Pack instance State of Charge (SOC).  Note:  A given HVES controller may not support all of the states.This parameter is for one of multiple packs in an HVESS.  If there is on...";
CM_ SG_ 2364750334 Hvesp26CellBalanceStatus "HVESP26 Cell Balance Status: Indicates whether or not the cells in this High Voltage Energy Storage Pack instance are balanced.This parameter is for one of multiple packs in an HVESS.  If there is only one pack in the system, the HVESS parameters sho...";
CM_ SG_ 2364750334 Hvesp26CellBalancingActive "HVESP26 Cell Balancing Active: Indicates whether or not the cells in this High Voltage Energy Storage Pack instance are currently being balanced.This parameter is for one of multiple packs in an HVESS.  If there is only one pack in the system, the HV...";
CM_ SG_ 2364750334 Hvesp26InternalChargerStatus "HVESP26 Internal Charger Status: Indicates that the charger in this HVES instance is on.  External chargers may use the External Energy Source Connection Status (SPN 7898) and related SPs.This parameter is for one of multiple packs in an HVESS. If th...";
CM_ SG_ 2364750334 Hvsp26HghVltgBsCnntnStts "HVESP26 High-Voltage Bus Connection Status: This parameter provides high level feedback on this High Voltage Energy Storage Pack instance high voltage bus connection. For specific contactor information, see SPN 17447 (HVESP26 High-Voltage Bus (Positi...";
CM_ SG_ 2364750334 Hvesp26OperationalStatus "HVESP26 Operational Status: Provides feedback on where this High Voltage Energy Storage Pack instance is in its operating spectrum, and includes feedback in response to the Operation Consent [i.e. SPN 17405 (HVESP26 Operation Consent)] and Power Down...";
CM_ SG_ 2364750334 Hvesp26Status1Counter "HVESP26 Status 1 Counter: The message counter is used to detect situations where the transmitting ECU malfunction repeats the same frame all the time. The receiver of the information may use the counter parameter to detect this situation. The transmi...";
CM_ SG_ 2364750334 Hvesp26Status1Crc "HVESP26 Status 1 CRC: The CRC is defined as follows: - Length: 8 bits- Polynomial: x^8+x^5+x^3+x^2+x+1- Initial Value: FFh- Input Data Reflection: Not reflected- Result Data Reflection: Not reflected- XOR value: FFh SAE makes no claim of the function...";
CM_ BO_ 2364750590 "High Voltage Energy Storage Pack 26 Data 7";
CM_ SG_ 2364750590 Hvesp26DischargeEnergyCapacity "HVESP26 Discharge Energy Capacity: The amount of stored electrical energy in this High Voltage Energy Storage Pack instance that is available for use by the hybrid or EV system, i.e. 'how full is the tank'. See SPN 17434 (HVESP26 Discharge Capacity) ...";
CM_ SG_ 2364750590 Hvesp26ChargeEnergyCapacity "HVESP26 Charge Energy Capacity: The amount of unused electrical energy storage available to be filled by charging this High Voltage Energy Storage Pack instance, i.e. 'how much empty space is remaining in the tank'. See SPN 17435 (HVESP26 Charge Capa...";
CM_ SG_ 2364750590 Hvsp26MxmmChrgVltgLmt "HVESP26 Maximum Charge Voltage Limit: The maximum voltage level not to be exceeded while charging this High Voltage Energy Storage Pack instance. If this parameter is not supported, the maximum charge voltage should be limited to SPN 17533 (HVESP26 R...";
CM_ BO_ 2364750846 "High Voltage Energy Storage Pack 26 Module Status 1";
CM_ SG_ 2364750846 Hvesp26Module1OperationalStatus "HVESP26 Module 1 Operational Status: Operational Status of Module 1 in this High Voltage Energy Storage Pack Instance.  Not Operational is used when the module is initializing or not able to function (e.g. internal module level monitors have failed)....";
CM_ SG_ 2364750846 Hvesp26Module2OperationalStatus "HVESP26 Module 2 Operational Status: Operational Status of Module 2 in this High Voltage Energy Storage Pack Instance.  Not Operational is used when the module is initializing or not able to function (e.g. internal module level monitors have failed)....";
CM_ SG_ 2364750846 Hvesp26Module3OperationalStatus "HVESP26 Module 3 Operational Status: Operational Status of Module 3 in this High Voltage Energy Storage Pack Instance.  Not Operational is used when the module is initializing or not able to function (e.g. internal module level monitors have failed)....";
CM_ SG_ 2364750846 Hvesp26Module4OperationalStatus "HVESP26 Module 4 Operational Status: Operational Status of Module 4 in this High Voltage Energy Storage Pack Instance.  Not Operational is used when the module is initializing or not able to function (e.g. internal module level monitors have failed)....";
CM_ SG_ 2364750846 Hvesp26Module5OperationalStatus "HVESP26 Module 5 Operational Status: Operational Status of Module 5 in this High Voltage Energy Storage Pack Instance.  Not Operational is used when the module is initializing or not able to function (e.g. internal module level monitors have failed)....";
CM_ SG_ 2364750846 Hvesp26Module6OperationalStatus "HVESP26 Module 6 Operational Status: Operational Status of Module 6 in this High Voltage Energy Storage Pack Instance.  Not Operational is used when the module is initializing or not able to function (e.g. internal module level monitors have failed)....";
CM_ SG_ 2364750846 Hvesp26Module7OperationalStatus "HVESP26 Module 7 Operational Status: Operational Status of Module 7 in this High Voltage Energy Storage Pack Instance.  Not Operational is used when the module is initializing or not able to function (e.g. internal module level monitors have failed)....";
CM_ SG_ 2364750846 Hvesp26Module8OperationalStatus "HVESP26 Module 8 Operational Status: Operational Status of Module 8 in this High Voltage Energy Storage Pack Instance.  Not Operational is used when the module is initializing or not able to function (e.g. internal module level monitors have failed)....";
CM_ SG_ 2364750846 Hvesp26Module9OperationalStatus "HVESP26 Module 9 Operational Status: Operational Status of Module 9 in this High Voltage Energy Storage Pack Instance.  Not Operational is used when the module is initializing or not able to function (e.g. internal module level monitors have failed)....";
CM_ SG_ 2364750846 Hvsp26Mdl10OprtnlStts "HVESP26 Module 10 Operational Status: Operational Status of Module 10 in this High Voltage Energy Storage Pack Instance.  Not Operational is used when the module is initializing or not able to function (e.g. internal module level monitors have failed...";
CM_ SG_ 2364750846 Hvsp26Mdl11OprtnlStts "HVESP26 Module 11 Operational Status: Operational Status of Module 11 in this High Voltage Energy Storage Pack Instance.  Not Operational is used when the module is initializing or not able to function (e.g. internal module level monitors have failed...";
CM_ SG_ 2364750846 Hvsp26Mdl12OprtnlStts "HVESP26 Module 12 Operational Status: Operational Status of Module 12 in this High Voltage Energy Storage Pack Instance.  Not Operational is used when the module is initializing or not able to function (e.g. internal module level monitors have failed...";
CM_ SG_ 2364750846 Hvsp26Mdl13OprtnlStts "HVESP26 Module 13 Operational Status: Operational Status of Module 13 in this High Voltage Energy Storage Pack Instance.  Not Operational is used when the module is initializing or not able to function (e.g. internal module level monitors have failed...";
CM_ SG_ 2364750846 Hvsp26Mdl14OprtnlStts "HVESP26 Module 14 Operational Status: Operational Status of Module 14 in this High Voltage Energy Storage Pack Instance.  Not Operational is used when the module is initializing or not able to function (e.g. internal module level monitors have failed...";
CM_ SG_ 2364750846 Hvsp26Mdl15OprtnlStts "HVESP26 Module 15 Operational Status: Operational Status of Module 15 in this High Voltage Energy Storage Pack Instance.  Not Operational is used when the module is initializing or not able to function (e.g. internal module level monitors have failed...";
CM_ SG_ 2364750846 Hvsp26Mdl16OprtnlStts "HVESP26 Module 16 Operational Status: Operational Status of Module 16 in this High Voltage Energy Storage Pack Instance.  Not Operational is used when the module is initializing or not able to function (e.g. internal module level monitors have failed...";
CM_ SG_ 2364750846 Hvsp26Mdl17OprtnlStts "HVESP26 Module 17 Operational Status: Operational Status of Module 17 in this High Voltage Energy Storage Pack Instance.  Not Operational is used when the module is initializing or not able to function (e.g. internal module level monitors have failed...";
CM_ SG_ 2364750846 Hvsp26Mdl18OprtnlStts "HVESP26 Module 18 Operational Status: Operational Status of Module 18 in this High Voltage Energy Storage Pack Instance.  Not Operational is used when the module is initializing or not able to function (e.g. internal module level monitors have failed...";
CM_ SG_ 2364750846 Hvsp26Mdl19OprtnlStts "HVESP26 Module 19 Operational Status: Operational Status of Module 19 in this High Voltage Energy Storage Pack Instance.  Not Operational is used when the module is initializing or not able to function (e.g. internal module level monitors have failed...";
CM_ SG_ 2364750846 Hvsp26Mdl20OprtnlStts "HVESP26 Module 20 Operational Status: Operational Status of Module 20 in this High Voltage Energy Storage Pack Instance.  Not Operational is used when the module is initializing or not able to function (e.g. internal module level monitors have failed...";
CM_ SG_ 2364750846 Hvsp26Mdl21OprtnlStts "HVESP26 Module 21 Operational Status: Operational Status of Module 21 in this High Voltage Energy Storage Pack Instance.  Not Operational is used when the module is initializing or not able to function (e.g. internal module level monitors have failed...";
CM_ SG_ 2364750846 Hvsp26Mdl22OprtnlStts "HVESP26 Module 22 Operational Status: Operational Status of Module 22 in this High Voltage Energy Storage Pack Instance.  Not Operational is used when the module is initializing or not able to function (e.g. internal module level monitors have failed...";
CM_ SG_ 2364750846 Hvsp26Mdl23OprtnlStts "HVESP26 Module 23 Operational Status: Operational Status of Module 23 in this High Voltage Energy Storage Pack Instance.  Not Operational is used when the module is initializing or not able to function (e.g. internal module level monitors have failed...";
CM_ SG_ 2364750846 Hvsp26Mdl24OprtnlStts "HVESP26 Module 24 Operational Status: Operational Status of Module 24 in this High Voltage Energy Storage Pack Instance.  Not Operational is used when the module is initializing or not able to function (e.g. internal module level monitors have failed...";
CM_ SG_ 2364750846 Hvsp26Mdl25OprtnlStts "HVESP26 Module 25 Operational Status: Operational Status of Module 25 in this High Voltage Energy Storage Pack Instance.  Not Operational is used when the module is initializing or not able to function (e.g. internal module level monitors have failed...";
CM_ SG_ 2364750846 Hvsp26Mdl26OprtnlStts "HVESP26 Module 26 Operational Status: Operational Status of Module 26 in this High Voltage Energy Storage Pack Instance.  Not Operational is used when the module is initializing or not able to function (e.g. internal module level monitors have failed...";
CM_ SG_ 2364750846 Hvsp26Mdl27OprtnlStts "HVESP26 Module 27 Operational Status: Operational Status of Module 27 in this High Voltage Energy Storage Pack Instance.  Not Operational is used when the module is initializing or not able to function (e.g. internal module level monitors have failed...";
CM_ SG_ 2364750846 Hvsp26Mdl28OprtnlStts "HVESP26 Module 28 Operational Status: Operational Status of Module 28 in this High Voltage Energy Storage Pack Instance.  Not Operational is used when the module is initializing or not able to function (e.g. internal module level monitors have failed...";
CM_ SG_ 2364750846 Hvsp26Mdl29OprtnlStts "HVESP26 Module 29 Operational Status: Operational Status of Module 29 in this High Voltage Energy Storage Pack Instance.  Not Operational is used when the module is initializing or not able to function (e.g. internal module level monitors have failed...";
CM_ SG_ 2364750846 Hvsp26Mdl30OprtnlStts "HVESP26 Module 30 Operational Status: Operational Status of Module 30 in this High Voltage Energy Storage Pack Instance.  Not Operational is used when the module is initializing or not able to function (e.g. internal module level monitors have failed...";
CM_ SG_ 2364750846 Hvsp26Mdl31OprtnlStts "HVESP26 Module 31 Operational Status: Operational Status of Module 31 in this High Voltage Energy Storage Pack Instance.  Not Operational is used when the module is initializing or not able to function (e.g. internal module level monitors have failed...";
CM_ SG_ 2364750846 Hvsp26Mdl32OprtnlStts "HVESP26 Module 32 Operational Status: Operational Status of Module 32 in this High Voltage Energy Storage Pack Instance.  Not Operational is used when the module is initializing or not able to function (e.g. internal module level monitors have failed...";
CM_ BO_ 2364751102 "High Voltage Energy Storage Pack 26 Thermal Management System Status 1";
CM_ SG_ 2364751102 Hvsp26ThrmlMngmntSstmSlInptPwr "HVESP26 Thermal Management System SLI Input Power: This is the low-voltage power consumed by this HVES Thermal Management System (TMS).This parameter is for one of multiple packs in an HVESS.  If there is only one pack in the system, the HVESS parame...";
CM_ SG_ 2364751102 Hvsp26TMtSstHVtIptPw "HVESP26 Thermal Management System High-Voltage Input Power: This is the high-voltage power consumed by this HVES Thermal Management System (TMS).This parameter is for one of multiple packs in an HVESS.  If there is only one pack in the system, the HV...";
CM_ SG_ 2364751102 Hvsp26ThrmlMngmntSstmCmprssrSpd "HVESP26 Thermal Management System Compressor Speed: When this High Voltage Energy Storage Pack Thermal Management System is equipped with an active cooling system (e.g. air conditioner), this is the Compressor Speed.This parameter is for one of multi...";
CM_ SG_ 2364751102 Hvsp26ThrmlMngmntSstmRltvHmdt "HVESP26 Thermal Management System Relative Humidty: When this High Voltage Energy Storage Pack Thermal Management System is equipped with a relative humidity sensor, this is the  measured Relative Humidity.This parameter is for one of multiple packs ...";
CM_ SG_ 2364751102 Hvsp26ThrmlMngmntSstmHtrStts "HVESP26 Thermal Management System Heater Status: The state of this High Voltage Energy Storage Pack heaterThis parameter is for one of multiple packs in an HVESS.  If there is only one pack in the system, the HVESS parameters should be used. If there...";
CM_ SG_ 2364751102 Hvsp26ThrmlMngmntSstmHvlStts "HVESP26 Thermal Management System HVIL Status: In multiple HVES configurations, this is the status of the High Voltage Interlock Loop from the viewpoint of this Thermal Management System.00b = HVIL Closed01b = HVIL Open10b = Error11b = Not AvailableT...";
CM_ SG_ 2364751102 Hvsp26ThrmlMngmntSstmMd "HVESP26 Thermal Management System Mode: Indicates the operating mode of the Thermal Management System.  The heat transfer medium may be (e.g. liquid or air).  The cooling system may be fans, liquid coolant, or a combination of mediums.  The system ma...";
CM_ SG_ 2364751102 Hvsp26ThrmlMngmntSstmClntLvl "HVESP26 Thermal Management System Coolant Level: Indicates the coolant level in this HVES Thermal Management System (TMS).This parameter is for one of multiple packs in an HVESS.  If there is only one pack in the system, the HVESS parameters should b...";
CM_ BO_ 2364751358 "High Voltage Energy Storage Pack 26 Data 8";
CM_ SG_ 2364751358 Hvsp26HghstCllVltgMdlNmr "HVESP26 Highest Cell Voltage Module Number: Identifies the location of the module containing SPN 17427 (HVESP26 Highest Cell Voltage).This parameter is for one of multiple packs in an HVESS. If there is only one pack in the system, the HVESS paramete...";
CM_ SG_ 2364751358 Hvsp26HghstCllVltgCllNmr "HVESP26 Highest Cell Voltage Cell Number: Identifies the location of SPN 17427 (HVESP26 Highest Cell Voltage) within SPN 17507 (HVESP26 Highest Cell Voltage Module Number).This parameter is for one of multiple packs in an HVESS. If there is only one ...";
CM_ SG_ 2364751358 Hvsp26LwstCllVltgMdlNmr "HVESP26 Lowest Cell Voltage Module Number: Identifies the location of the module containing SPN 17428 (HVESP26 Lowest Cell Voltage).This parameter is for one of multiple packs in an HVESS. If there is only one pack in the system, the HVESS parameters...";
CM_ SG_ 2364751358 Hvsp26LwstCllVltgCllNmr "HVESP26 Lowest Cell Voltage Cell Number: Identifies the location of SPN 17428 (HVESP26 Lowest Cell Voltage) within SPN 17509 (HVESP26 Lowest Cell Voltage Module Number).This parameter is for one of multiple packs in an HVESS. If there is only one pac...";
CM_ SG_ 2364751358 Hvesp26AverageCellVoltage "HVESP26 Average Cell Voltage: The average cell voltage in this High Voltage Energy Storage Pack instance.This parameter is for one of multiple packs in an HVESS.  If there is only one pack in the system, the HVESS parameters should be used. If there ...";
CM_ BO_ 2364751614 "High Voltage Energy Storage Pack 26 Data 9";
CM_ SG_ 2364751614 Hvsp26HghstCllTmprtrMdlNmr "HVESP26 Highest Cell Temperature Module Number: Identifies the location of the module containing SPN 17430 (HVESP26 Highest Cell Temperature).This parameter is for one of multiple packs in an HVESS. If there is only one pack in the system, the HVESS ...";
CM_ SG_ 2364751614 Hvsp26HghstCllTmprtrCllNmr "HVESP26 Highest Cell Temperature Cell Number: Identifies the location of SPN 17430 (HVESP26 Highest Cell Temperature) within SPN 17512 (HVESP26 Highest Cell Temperature Module Number).This parameter is for one of multiple packs in an HVESS. If there ...";
CM_ SG_ 2364751614 Hvsp26LwstCllTmprtrMdlNmr "HVESP26 Lowest Cell Temperature Module Number: Identifies the location of the module containing SPN 17431 (HVESP26 Lowest Cell Temperature).This parameter is for one of multiple packs in an HVESS. If there is only one pack in the system, the HVESS pa...";
CM_ SG_ 2364751614 Hvsp26LwstCllTmprtrCllNmr "HVESP26 Lowest Cell Temperature Cell Number: Identifies the location of SPN 17431 (HVESP26 Lowest Cell Temperature) within SPN 17514 (HVESP26 Lowest Cell Temperature Module Number).This parameter is for one of multiple packs in an HVESS. If there is ...";
CM_ SG_ 2364751614 Hvess26ThermalEventDetected "HVESS26 Thermal Event Detected: A sensor has detected the presence of a thermal event at or near High Voltage Energy Storage Pack instance.00b = No Thermal Event Detected01b = Thermal Event Detected10b = Error11b = Not availableThis parameter is for ...";
CM_ SG_ 2364751614 Hvsp26Dt9EmdddIntgrtSpprt "HVESP26 Data 9 Embedded Integrity Support: Indicates SPN 23051 (HVESP26 Data 9 CRC) and SPN 23050 (HVESP26 Data 9 Counter) are supported by the sender.00b = Embedded CRC and Counter are supported by the sender01b = Protection is provided using an ext...";
CM_ SG_ 2364751614 Hvesp26Data9Counter "HVESP26 Data 9 Counter: The message counter is used to detect situations where the transmitting ECU malfunction repeats the same frame all the time. The receiver of the information may use the counter parameter to detect this situation. The transmitt...";
CM_ SG_ 2364751614 Hvesp26Data9Crc "HVESP26 Data 9 CRC: The CRC is defined as follows: - Length: 8 bits- Polynomial: x^8+x^5+x^3+x^2+x+1- Initial Value: FFh- Input Data Reflection: Not reflected- Result Data Reflection: Not reflected- XOR value: FFh SAE makes no claim of the functional...";
CM_ BO_ 2364751870 "High Voltage Energy Storage Pack 26 Data 10";
CM_ SG_ 2364751870 Hvsp26HghstCllSttOfChrgMdlNmr "HVESP26 Highest Cell State of Charge Module Number: Identifies the location of the module containing SPN 17440 (HVESP26 Highest Cell State of Charge).This parameter is for one of multiple packs in an HVESS. If there is only one pack in the system, th...";
CM_ SG_ 2364751870 Hvsp26HghstCllSttOfChrgCllNmr "HVESP26 Highest Cell State of Charge Cell Number: Identifies the location of SPN 17440 (HVESP26 Highest Cell State of Charge) within SPN 17516 (HVESP26 Highest Cell State of Charge Module Number).This parameter is for one of multiple packs in an HVES...";
CM_ SG_ 2364751870 Hvsp26LwstCllSttOfChrgMdlNmr "HVESP26 Lowest Cell State of Charge Module Number: Identifies the location of the module containing SPN 17439 (HVESP26 Lowest Cell State of Charge).This parameter is for one of multiple packs in an HVESS. If there is only one pack in the system, the ...";
CM_ SG_ 2364751870 Hvsp26LwstCllSttOfChrgCllNmr "HVESP26 Lowest Cell State of Charge Cell Number: Identifies the location of SPN 17439 (HVESP26 Lowest Cell State of Charge) within SPN 17518 (HVESP26 Lowest Cell State of Charge Module Number).This parameter is for one of multiple packs in an HVESS. ...";
CM_ SG_ 2364751870 Hvsp26HghVltgBsAtvIsltnTstRslts "HVESP26 High-Voltage Bus Active Isolation Test Results: The isolation resistance expressed in Ohms per Volt that resulted from the High-Voltage Bus Active Isolation Test.See SPN 17452 (HVESP26 High-Voltage Bus Active Isolation Test Status) for test s...";
CM_ SG_ 2364751870 Hvsp26HVtBsPssvIstTstRsts "HVESP26 High-Voltage Bus Passive Isolation Test Results: The isolation resistance expressed in Ohms per Volt that resulted from the High-Voltage Bus Passive Isolation Test.See SPN 17453 (HVESP26 High-Voltage Bus Passive Isolation Test Status) for tes...";
CM_ BO_ 2364752126 "High Voltage Energy Storage Pack 26 Data 11";
CM_ SG_ 2364752126 Hvsp26BsVltgNgtvTChsssGrndVltg "HVESP26 Bus Voltage Negative to Chassis Ground Voltage: Voltage difference between the most negative terminal of the HVES battery and chassis measured on the hybrid or EV system bus side (not the battery side) of any HVES contained output contactor. ...";
CM_ SG_ 2364752126 Hvsp26VltgLvlNgtvTChsssGrndVltg "HVESP26 Voltage Level Negative to Chassis Ground Voltage: Voltage difference between the most negative terminal of the HVES battery and chassis measured at the battery side of any HVES contained output contactor.  This voltage may be used for system ...";
CM_ SG_ 2364752126 Hvesp26ActualChargeRate "HVESP26 Actual Charge Rate: This signal represents the actual present charge rate of this High Voltage Energy Storage Pack instance.This parameter is for one of multiple packs in an HVESS. If there is only one pack in the system, the HVESS parameters...";
CM_ BO_ 2297643518 "External Steering Request";
CM_ SG_ 2297643518 ExtrnlStrngRqstOprtngMd "External Steering Request Operating Mode: The operating mode is used as an input to the steering system and defines the desired operating mode requested by an external controlling device. When the driver override is enabled, the steering command will...";
CM_ SG_ 2297643518 ExtrnlStrngWhlPstnRqst "External Steering Wheel Position Request: Indicates the steering wheel position input command value to the active steering system and is enabled when the steering position control mode is selected.This commanded value is referenced at the main operat...";
CM_ SG_ 2297643518 ExtrnlStrngWhlTrqRqst "External Steering Wheel Torque Request: Indicates the steering torque input command value to the active steering system from the controlling device and is enabled when the torque control mode is selected.This commanded torque is referenced at the mai...";
CM_ SG_ 2297643518 ExternalSteeringRequestPriority "External Steering Request Priority: XSR Priority is used as an input to the steering system to manage the priority of overlapping external and internal requests.0000b = Priority 10001b = Priority 20010b = Priority 30011b = Priority 40100b = Reserved0...";
CM_ SG_ 2297643518 XsrMessageCounter "XSR Message Counter: The XSR message counter is to verify the signal path from the demanding device to the active steering system.Note: The initial value of the 4 bit message counter for the first message during a driving cycle is arbitrary. In every...";
CM_ SG_ 2297643518 XsrMessageChecksum "XSR Message Checksum: The XSR message checksum is used to verify the signal path from the demanding device to the active steering system.The 4 bit XSR message checksum is calculated using the first 7 data bytes, the 4 bit message counter and the byte...";
CM_ BO_ 2364752638 "Active Steering System Controller 2";
CM_ SG_ 2364752638 ActiveSteeringActualMode "Active Steering Actual Mode: Signal indicates the current mode of the active steering system.0000b = External Request Disabled - Default Mode0001b = Steering Position Control with Driver Override0010b = Steering Position Control without Driverride001...";
CM_ SG_ 2364752638 ActiveSteeringSystemState "Active Steering System State: Indicates the current state of the active steering system controller for external steering requests.0000b = System is not ready0001b = System is temporarily not available0010b = System is ready0011b = System Malfunction ...";
CM_ SG_ 2364752638 ActiveSteeringErrorType "Active Steering Error Type: Indicates the error type of the steering controller. The signal can be used to initiate various fail operational methods.0000b = No Error0001b = External Request Missing0010b = Redundant Communication Error0011b = Internal...";
CM_ SG_ 2364752638 ActiveSteeringRequestedMode "Active Steering Requested Mode: Indicates the input received for desired operating mode in the XSR message. Not all modes may be relevant for a given device. Some devices may not implement all functions.0000b = External Request Disabled - Default Mod...";
CM_ SG_ 2364752638 ActiveSteeringIgnitionPower "Active Steering Ignition Power: Indicates that the ignition (or run) voltage that is being supplied to the active steering system. This state is also known in DIN 75552 as KL15.This parameter may or may not represent the physical position of a rotary...";
CM_ SG_ 2364752638 AsltStrngPstnQltFtr "Absolute Steering Position Quality Factor: Absolute Steering Position Quality Factor indicates the integrity of the Active Steering System Steering Wheel Position (SPN 21102) reported by the active steering system controller.  The external vehicle co...";
CM_ SG_ 2364752638 AtvStrngSstmStrngWhlPstn "Active Steering System Steering Wheel Position: Measured absolute steering hand wheel position from the active steering system.This value is referenced at the main operator`s steering wheel angle (on the steering column, not the actual road wheel ang...";
CM_ SG_ 2364752638 AtvStrngSstmStrngWhlTrq "Active Steering System Steering Wheel Torque: Measured steering torque at the hand wheel from the active steering system.This value is referenced at the main operator`s steering wheel angle (on the steering column, not the actual road wheel angle).  ...";
CM_ SG_ 2364752638 Assc2MessageCounter "ASSC2 Message Counter: The ASSC2 message counter is to verify the signal path from the demanding device to the active steering system.Note: The initial value of the 4 bit message counter for the first message during a driving cycle is arbitrary. In e...";
CM_ SG_ 2364752638 Assc2MessageChecksum "ASSC2 Message Checksum: The ASSC2 message checksum is used to verify the signal path from the demanding device to the active steering system.The 4 bit ASSC2 message checksum is calculated using the first 7 data bytes, the 4 bit message counter and th...";
CM_ BO_ 2566540286 "Aftertreatment 2 SCR Dosing System Information 5";
CM_ SG_ 2566540286 Atttt2DsExstFdDs2PssExtddR "Aftertreatment 2 Diesel Exhaust Fluid Doser 2 Pressure (Extended Range): The SCR doser 2 diesel exhaust fluid gage pressure (measured closest to dosing valve) for aftertreatment system 2 ( exhaust bank 2).See SPN 8153 for alternate range and resoluti...";
CM_ SG_ 2566540286 Atttt2DsExstFdDs3PssExtddR "Aftertreatment 2 Diesel Exhaust Fluid Doser 3 Pressure (Extended Range): The SCR doser 3 diesel exhaust fluid gage pressure (measured closest to dosing valve) for aftertreatment system 2 (exhaust bank 2).";
CM_ BO_ 2566540542 "Aftertreatment 1 SCR Dosing System Information 5";
CM_ SG_ 2566540542 Atttt1DsExstFdDs2PssExtddR "Aftertreatment 1 Diesel Exhaust Fluid Doser 2 Pressure (Extended Range): The SCR doser 2 diesel exhaust fluid gage pressure (measured closest to dosing valve) for aftertreatment system 1 (exhaust bank 1).See SPN 8152 for alternate range and resolutio...";
CM_ SG_ 2566540542 Atttt1DsExstFdDs3PssExtddR "Aftertreatment 1 Diesel Exhaust Fluid Doser 3 Pressure (Extended Range): The SCR doser 3 diesel exhaust fluid gage pressure (measured closest to dosing valve) for aftertreatment system 1 (exhaust bank 1).";
CM_ BO_ 2566540798 "EV Economy Information";
CM_ SG_ 2566540798 TotalTripEnergyConsumed "Total Trip Energy Consumed: Energy consumed by all the vehicle active powertrain and electrified accessories since the last Trip Reset. (See PGN 56832 RESET)";
CM_ SG_ 2566540798 TripDriveEnergyEconomy "Trip Drive Energy Economy: Trip Drive Energy Economy (i.e. powertrain and electrified accessory energy) is equal to the electric vehicle Total Trip Energy Consumed (SPN 20876) divided by the vehicle distance traveled (in KM) since the last Trip Reset...";
CM_ BO_ 2566541054 "Automated Driving System Status 2";
CM_ SG_ 2566541054 AttdDvSstOptSttsAwdt "Automated Driving System Operation Status Acknowledgement: This parameter indicates the current mode of an ADSC recipient. It is expected to be same as the SPN 20870 (Automated Driving System Operation Status).000b = ADS Manual Mode 001b = ADS Automa...";
CM_ SG_ 2566541054 AdsManualModeSupport "ADS Manual Mode Support: This parameter indicates the support for ADS Manual Mode by a ADS recipient. This parameter is expected to change as defined in SPN 20870 (Automated Driving System Operation Status).00b - Disabled01b - Enabled10b - Reserved11...";
CM_ SG_ 2566541054 AdsAtmtdMdWthOprtrOvrrdSpprt "ADS Automated Mode with Operator Override Support: This parameter indicates the support for Automated Mode with Operator Override by a ADS recipient. This parameter is expected to change as defined in SPN 20870 (Automated Driving System Operation Sta...";
CM_ SG_ 2566541054 AdsAutomatedModeSupport "ADS Automated Mode Support: This parameter indicates the support for Automated Mode by a ADS recipient. This parameter is expected to change as defined in SPN 20870 (Automated Driving System Operation Status).00 - Disabled01 - Enabled10 - Reserved11 ...";
CM_ SG_ 2566541054 AdsCntrllr1CmmntnStts "ADS Controller 1 Communication Status: This parameter indicates the current status of the ADS controller 1 detected by the controller application under the control of automated driving system.000b = System is not ready (initialization not finished)00...";
CM_ SG_ 2566541054 AdsCntrllr2CmmntnStts "ADS Controller 2 Communication Status: This parameter indicates the current status of the ADS controller 2 detected by the controller application under the control of automated driving system.000b = System is not ready (initialization not finished)00...";
CM_ SG_ 2566541054 AdsCntrllr3CmmntnStts "ADS Controller 3 Communication Status: This parameter indicates the current status of the ADS controller 3 detected by the controller application under the control of automated driving system.000b = System is not ready (initialization not finished)00...";
CM_ SG_ 2566541054 AdsCntrllr4CmmntnStts "ADS Controller 4 Communication Status: This parameter indicates the current status of the ADS controller 4 detected by the controller application under the control of automated driving system.000b = System is not ready (initialization not finished)00...";
CM_ SG_ 2566541054 CmpnntDgnstAndMtgtnCplt "Component Diagnostic and Mitigation Capability: This parameter is sent by a controller application that is integrated with an Automated Driving System (ADS), such as the engine control module, transmission control module, etc. This parameter indicate...";
CM_ SG_ 2566541054 Adss2EmbeddedIntegritySupport "ADSS2 Embedded Integrity Support: Indicates that SPN 23064 (ADSS2 CRC) and SPN 23063 (ADSS2 Counter) are supported by the sender.00b = ADSS2 embedded CRC and Counter are supported by the sender01b = ADSS2 protection is provided using an external (not...";
CM_ SG_ 2566541054 Adss2Counter "ADSS2 Counter: The message counter is used to detect situations where the transmitting ECU malfunction repeats the same frame all the time. The receiver of the information may use the counter parameter to detect this situation. The transmitting devic...";
CM_ SG_ 2566541054 Adss2Crc "ADSS2 CRC: The CRC is defined as follows:  - Length: 8 bits  - Polynomial: x^8+x^5+x^3+x^2+x+1  - Initial Value: FFh  - Input Data Reflection: Not reflected  - Result Data Reflection: Not reflected  - XOR value: FFhSAE makes no claim of the functiona...";
CM_ BO_ 2566541310 "Automated Driving System Control 3";
CM_ SG_ 2566541310 AtmtdDrvngSstmOprtnStts "Automated Driving System Operation Status: This parameter indicates the current engagement mode of the automated driving system. This parameter is only expected to change when the vehicle's ADS configuration is capable of changing.In the event the AD...";
CM_ SG_ 2566541310 Adsc3Counter "ADSC3 Counter: The message counter is used to detect situations where the transmitting ECU malfunction repeats the same frame all the time. The receiver of the information may use the counter parameter to detect this situation. The transmitting devic...";
CM_ SG_ 2566541310 Adsc3Crc "ADSC3 CRC: The CRC is defined as follows:- Length: 8 bits- Polynomial: x^8+x^5+x^3+x^2+x+1- Initial Value: FFh- Input Data Reflection: Not reflected- Result Data Reflection: Not reflected- XOR value: FFhSAE makes no claim of the functional safety lev...";
CM_ SG_ 2566541310 Adsc3EmbeddedIntegritySupport "ADSC3 Embedded Integrity Support: Indicates that SPN 14456 (ADSC3 CRC) and SPN 14455 (ADSC3 Counter) are supported by the sender.00b = ADSC3 embedded CRC and Counter are supported by the sender01b = ADSC3 protection is provided using an external (not...";
CM_ BO_ 2566541566 "Aftercooler Valve";
CM_ SG_ 2566541566 EngnAftrlrClntTmprtr "Engine Aftercooler Coolant Temperature: Temperature of liquid found at the intake to the engine low temperature aftercooler located after the turbocharger.";
CM_ SG_ 2566541566 EDsdAtCtItTptHRst "Engine Desired Aftercooler Coolant Intake Temperature (High Resolution): Indicates the desired temperature of the fluid in the engine low temperature aftercooler circuit to an electronic thermostat.See SPN 4199 for alternate resolution.";
CM_ SG_ 2566541566 EAtCtDtPssSwtStts "Engine Aftercooler Coolant Differential Pressure Switch Status: The differential pressure measured across the input and output of the engine low temperature aftercooler coolant pump.00b = OK (Pressure Normal)01b = Not OK (Pressure Out of Range)10b = ...";
CM_ SG_ 2566541566 EngnAftrlrClntPmpCntrl "Engine Aftercooler Coolant Pump Control: This control is used to activate an engine low temperature aftercooler coolant pump.00b = Off01b = On10b = Reserved11b = Unavailable";
CM_ SG_ 2566541566 EngnAftrlrClntDvrtrVlvPstn "Engine Aftercooler Coolant Diverter Valve Position: Indicates the position of the engine aftercooler coolant diverter valve. 0% represents the valve is commanded to allow flow to completely bypass the radiator and 100% represents the flow is fully th...";
CM_ BO_ 2566541822 "Engine Radiator 1";
CM_ SG_ 2566541822 EngnRdtr1CntrlTmprtr "Engine Radiator 1 Control Temperature : Temperature measured and reported by the device. It may be used for direct or remote (by another controller) control of radiator 1.";
CM_ SG_ 2566541822 DsrdEngnRdtr1CntrlTmprtr "Desired Engine Radiator 1 Control Temperature: The desired temperature of the temperature used to control the radiator fan speed.";
CM_ SG_ 2566541822 EngineRadiator1Fan1Status "Engine Radiator 1 Fan 1 Status: Status of electrically operated cooling Radiator 1 Fan 1 on an engine.00b = Inactive01b = Active10b = Error11b = Not available";
CM_ SG_ 2566541822 EngineRadiator1Fan2Status "Engine Radiator 1 Fan 2 Status: Status of electrically operated cooling Radiator 1 Fan 2 on an engine.00b = Inactive01b = Active10b = Error11b = Not available";
CM_ SG_ 2566541822 EngineRadiator1Fan3Status "Engine Radiator 1 Fan 3 Status: Status of electrically operated cooling Radiator 1 Fan 3 on an engine.00b = Inactive01b = Active10b = Error11b = Not available";
CM_ SG_ 2566541822 EngineRadiator1Fan4Status "Engine Radiator 1 Fan 4 Status: Status of electrically operated cooling Radiator 1 Fan 4 on an engine.00b = Inactive01b = Active10b = Error11b = Not available";
CM_ SG_ 2566541822 EngineRadiator1Fan5Status "Engine Radiator 1 Fan 5 Status: Status of electrically operated cooling Radiator 1 Fan 5 on an engine.00b = Inactive01b = Active10b = Error11b = Not available";
CM_ SG_ 2566541822 EngineRadiator1Fan6Status "Engine Radiator 1 Fan 6 Status: Status of electrically operated cooling Radiator 1 Fan 6 on an engine.00b = Inactive01b = Active10b = Error11b = Not available";
CM_ SG_ 2566541822 EngineRadiator1Fan7Status "Engine Radiator 1 Fan 7 Status: Status of electrically operated cooling Radiator 1 Fan 7 on an engine.00b = Inactive01b = Active10b = Error11b = Not available";
CM_ SG_ 2566541822 EngineRadiator1Fan8Status "Engine Radiator 1 Fan 8 Status: Status of electrically operated cooling Radiator 1 Fan 8 on an engine.00b = Inactive01b = Active10b = Error11b = Not available";
CM_ SG_ 2566541822 EngnRdtrTmprtrCntrlSltnStts "Engine Radiator Temperature Control Selection Status: Indicates the active control temperature setpoint used to control the radiator.00b = Engine Radiator 1 Control Temperature01b = Engine Radiator 2 Control Temperature10b = Error11b = Not Available...";
CM_ BO_ 2566542078 "Engine Radiator 2";
CM_ SG_ 2566542078 EngnRdtr2CntrlTmprtr "Engine Radiator 2 Control Temperature : Temperature measured and reported by the device. It may be used for direct or remote (by another controller) control of the Fan 2. For example, this may be the temperature of the fluid flowing through the Fan 2...";
CM_ SG_ 2566542078 DsrdEngnRdtr2CntrlTmprtr "Desired Engine Radiator 2 Control Temperature: Indicates the desired temperature of the temperature used to control the fan speed.";
CM_ SG_ 2566542078 EngineRadiator2Fan1Status "Engine Radiator 2 Fan 1 Status: Status of electrically operated cooling Radiator 2 Fan 1 on an engine.00b = Inactive01b = Active10b = Error11b = Not available";
CM_ SG_ 2566542078 EngineRadiator2Fan2Status "Engine Radiator 2 Fan 2 Status: Status of electrically operated cooling Radiator 2 Fan 2 on an engine.00b = Inactive01b = Active10b = Error11b = Not available";
CM_ SG_ 2566542078 EngineRadiator2Fan3Status "Engine Radiator 2 Fan 3 Status: Status of electrically operated cooling Radiator 2 Fan 3 on an engine.00b = Inactive01b = Active10b = Error11b = Not available";
CM_ SG_ 2566542078 EngineRadiator2Fan4Status "Engine Radiator 2 Fan 4 Status: Status of electrically operated cooling Radiator 2 Fan 4 on an engine.00b = Inactive01b = Active10b = Error11b = Not available";
CM_ SG_ 2566542078 EngineRadiator2Fan5Status "Engine Radiator 2 Fan 5 Status: Status of electrically operated cooling Radiator 2 Fan 5 on an engine.00b = Inactive01b = Active10b = Error11b = Not available";
CM_ SG_ 2566542078 EngineRadiator2Fan6Status "Engine Radiator 2 Fan 6 Status: Status of electrically operated cooling Radiator 2 Fan 6 on an engine.00b = Inactive01b = Active10b = Error11b = Not available";
CM_ SG_ 2566542078 EngineRadiator2Fan7Status "Engine Radiator 2 Fan 7 Status: Status of electrically operated cooling Radiator 2 Fan 7 on an engine.00b = Inactive01b = Active10b = Error11b = Not available";
CM_ SG_ 2566542078 EngineRadiator2Fan8Status "Engine Radiator 2 Fan 8 Status: Status of electrically operated cooling Radiator 2 Fan 8 on an engine.00b = Inactive01b = Active10b = Error11b = Not available";
CM_ BO_ 2566542334 "Genset Enclosure Ventilation";
CM_ SG_ 2566542334 GnstEnlsrIntkArTmprtr "Genset Enclosure Intake Air Temperature: Temperature of air at the inlet of the genset enclosure.";
CM_ SG_ 2566542334 GnstEnlsrOtltArTmprtr "Genset Enclosure Outlet Air Temperature: Temperature of air at the outlet of the genset enclosure.";
CM_ SG_ 2566542334 GnstEnlsrFnRqstdPrntSpd "Genset Enclosure Fan Requested Percent Speed: Fan speed in the system as a ratio of the actual fan drive (current speed) to the fully engaged fan drive (maximum fan speed). A two state fan (off/on) will use 0% and 100% respectively. A three statefan ...";
CM_ SG_ 2566542334 GensetEnclosureFanStatus "Genset Enclosure Fan Status: Status of an electrically operated genset enclosure ventilation fan.00b = Inactive01b = Active10b = Error11b = Not available";
CM_ BO_ 2566542590 "Heat Exchanger 1";
CM_ SG_ 2566542590 HtExhngr1PrmrIntkTmprtr "Heat Exchanger 1 Primary Intake Temperature: Temperature of the liquid found at the intake of the heat exchanger 1 primary intake.";
CM_ SG_ 2566542590 HtExhngr1PrmrOtltTmprtr "Heat Exchanger 1 Primary Outlet Temperature: Temperature of the liquid found at the outlet of the heat exchanger 1 primary intake.";
CM_ SG_ 2566542590 HtExhngr1SndrIntkTmprtr "Heat Exchanger 1 Secondary Intake Temperature: Temperature of the liquid found at the intake of the heat exchanger 1 secondary intake.";
CM_ SG_ 2566542590 HtExhngr1SndrOtltTmprtr "Heat Exchanger 1 Secondary Outlet Temperature: Temperature of the liquid found at the outlet of the heat exchanger 1 secondary intake.";
CM_ BO_ 2566542846 "Heat Exchanger 2";
CM_ SG_ 2566542846 HtExhngr2PrmrIntkTmprtr "Heat Exchanger 2 Primary Intake Temperature: Temperature of the liquid found at the intake of the heat exchanger 2 primary intake.";
CM_ SG_ 2566542846 HtExhngr2PrmrOtltTmprtr "Heat Exchanger 2 Primary Outlet Temperature: Temperature of the liquid found at the outlet of the heat exchanger 2 primary intake.";
CM_ SG_ 2566542846 HtExhngr2SndrIntkTmprtr "Heat Exchanger 2 Secondary Intake Temperature: Temperature of the liquid found at the intake of the heat exchanger 2 secondary intake.";
CM_ SG_ 2566542846 HtExhngr2SndrOtltTmprtr "Heat Exchanger 2 Secondary Outlet Temperature: Temperature of the liquid found at the outlet of the heat exchanger 2 secondary intake.";
CM_ BO_ 2566543102 "Heat Exchanger 3";
CM_ SG_ 2566543102 HtExhngr3PrmrIntkTmprtr "Heat Exchanger 3 Primary Intake Temperature: Temperature of the liquid found at the intake of the heat exchanger 3 primary intake.";
CM_ SG_ 2566543102 HtExhngr3PrmrOtltTmprtr "Heat Exchanger 3 Primary Outlet Temperature: Temperature of the liquid found at the outlet of the heat exchanger 3 primary intake.";
CM_ SG_ 2566543102 HtExhngr3SndrIntkTmprtr "Heat Exchanger 3 Secondary Intake Temperature: Temperature of the liquid found at the intake of the heat exchanger 3 secondary intake.";
CM_ SG_ 2566543102 HtExhngr3SndrOtltTmprtr "Heat Exchanger 3 Secondary Outlet Temperature: Temperature of the liquid found at the outlet of the heat exchanger 3 secondary intake.";
CM_ BO_ 2566543358 "Heat Exchanger 4";
CM_ SG_ 2566543358 HtExhngr4PrmrIntkTmprtr "Heat Exchanger 4 Primary Intake Temperature: Temperature of the liquid found at the intake of the heat exchanger 4 primary intake.";
CM_ SG_ 2566543358 HtExhngr4PrmrOtltTmprtr "Heat Exchanger 4 Primary Outlet Temperature: Temperature of the liquid found at the outlet of the heat exchanger 4 primary intake.";
CM_ SG_ 2566543358 HtExhngr4SndrIntkTmprtr "Heat Exchanger 4 Secondary Intake Temperature: Temperature of the liquid found at the intake of the heat exchanger 4 secondary intake.";
CM_ SG_ 2566543358 HtExhngr4SndrOtltTmprtr "Heat Exchanger 4 Secondary Outlet Temperature: Temperature of the liquid found at the outlet of the heat exchanger 4 secondary intake.";
CM_ BO_ 2566543614 "Engine Exhaust Gas Heat Exchanger";
CM_ SG_ 2566543614 EngnExhstHtExhngrOtltTmprtr "Engine Exhaust Heat Exchanger Outlet Temperature: Temperature of engine combustion byproducts leaving the exhaust heat exchanger system.";
CM_ SG_ 2566543614 EExstHtExBpssAtt1DsdPst "Engine Exhaust Heat Exchanger Bypass Actuator 1 Desired Position: Used to transmit the desired position of the exhaust heat exchanger bypass control valve.  0% represents the bypass valve is closed and 100% represents the bypass is fully open allowin...";
CM_ SG_ 2566543614 EngnExhstHtExhngrBpssAttr1Pstn "Engine Exhaust Heat Exchanger Bypass Actuator 1 Position: Position of the exhaust heat exchanger bypass control valve.  0% represents the bypass valve is closed and 100% represents the bypass is fully open allowing all of the exhaust gas to bypass th...";
CM_ BO_ 2566543870 "Genset Enclosure Ventilation Louver";
CM_ SG_ 2566543870 GnstEnlsrVntltnLvrAttr1DsrdPstn "Genset Enclosure Ventilation Louver Actuator 1 Desired Position: Actuator that controls the opening of the ventilation louver 1. The control command to the actuator, normalized to percent, where 0% nominally represents fully closed (minimum air flow)...";
CM_ SG_ 2566543870 GnstEnlsrVntltnLvrAttr1Pstn "Genset Enclosure Ventilation Louver Actuator 1 Position: Position of the ventilation louver 1. A value of 0% represents fully closed and 100% represents fully open.";
CM_ SG_ 2566543870 GnstEnlsrVntltnLvrAttr2DsrdPstn "Genset Enclosure Ventilation Louver Actuator 2 Desired Position: Actuator that controls the opening of the ventilation louver 2. The control command to the actuator, normalized to percent, where 0% nominally represents fully closed (minimum air flow)...";
CM_ SG_ 2566543870 GnstEnlsrVntltnLvrAttr2Pstn "Genset Enclosure Ventilation Louver Actuator 2 Position: Position of the ventilation louver 2. A value of 0% represents fully closed and 100% represents fully open.";
CM_ SG_ 2566543870 GstEsVttRtLvAttDsdPst "Genset Enclosure Ventilation Recirculation Louver Actuator Desired Position: Actuator that controls the opening of the recirculation ventilation louver. The control command to the actuator, normalized to percent, where 0% nominally represents fully c...";
CM_ SG_ 2566543870 GnstEnlsrVntltnRrltnLvrAttrPstn "Genset Enclosure Ventilation Recirculation Louver Actuator Position: Position of the recirculation ventilation louver. A value of 0% represents fully closed and 100% represents fully open.";
CM_ BO_ 2566544126 "Genset External Coolant System";
CM_ SG_ 2566544126 DsrdHtngCrtThrmsttOpnng "Desired Heating Circuit Thermostat Opening: Indicates the desired position of the heating circuit control valve. 0% represents the thermostat allows flow to completely bypass the radiator and 100% represents the flow is fully through theradiator.";
CM_ SG_ 2566544126 HeatingCircuitThermostatOpening "Heating Circuit Thermostat Opening: Indicates the position of the heating circuit control valve. 0% represents the thermostat allows flow to completely bypass the radiator and 100% represents the flow is fully through the radiator.";
CM_ SG_ 2566544126 HtngCrtDffrntlPrssrSwthStts "Heating Circuit Differential Pressure Switch Status: The differential pressure measured across the input and output of the heating circuit pump.00b = OK (Pressure Normal)01b = Not OK (Pressure Out of Range)10b = Error (Switch State Cannot Be Determin...";
CM_ SG_ 2566544126 HeatingCircuitPumpControl "Heating Circuit Pump Control: Control setting for an electrically actuated customer site heating circuit pump.00b = Off01b = On10b = Reserved11b = Don't care / take no action";
CM_ SG_ 2566544126 HtngCrtSpplOtltClntTmprtr "Heating Circuit Supply Outlet Coolant Temperature: Temperature of the liquid found at the heating circuit supply outlet.";
CM_ SG_ 2566544126 HtngCrtRtrnClntTmprtr "Heating Circuit Return Coolant Temperature: Temperature of the liquid found at the heating circuit return.";
CM_ BO_ 2566544382 "EV DC Status 1";
CM_ SG_ 2566544382 EvCabinConditioningFlag "EV Cabin Conditioning Flag: Informs the EVSE that the EV is performing cabin conditioning.See SAE J2847-2 (April 2015 Section 4.2.23)00b = Cabin conditioning not active01b = Cabin conditioning active10b = Reserved11b = Not available";
CM_ SG_ 2566544382 EvRessConditioningFlag "EV RESS Conditioning Flag: Informs the EVSE that the EV is using energy from the EVSE  to perform battery (RESS/HVES) conditioning.See SAE J2847-2 (April 2015 Section 4.2.33)00b = Battery conditioning not active01b = Battery conditioning active10b = ...";
CM_ SG_ 2566544382 EvErrorCode "EV Error Code: Indicates the highest priority EV internal error state that may inhibit/abort chargingSee SAE J2847-2 (April 2015 Section 4.2.26)0000b = No Error0001b = Battery Temperature too hot/cold0010b = Shift Position  (Vehicle not in park)0011b...";
CM_ BO_ 2566544638 "EVSE DC Charging Limits 3";
CM_ SG_ 2566544638 EvseEnergyToBeDelivered "EVSE Energy to be Delivered: This signal represents the allowed or requested units of energy to be delivered during charging (a charging target). This allows public charging stations to limit charging session by limiting the energy transfer (i.e., fo...";
CM_ BO_ 2566545406 "EV DC Charging Limits 2";
CM_ SG_ 2566545406 EvBulkStateOfCharge "EV Bulk State of Charge: State of charge value, as indicated by SPN 7895, where bulk charging is considered to be complete. (For example 80%)See SAE J2847-2 201504 Sect. 4.2.3";
CM_ SG_ 2566545406 EvFullStateOfCharge "EV Full State of Charge: State of charge value, as indicated by SPN 7895, where charging is considered to be complete. (Typically 100%)See SAE J2847-2 201504 Sect. 4.2.57";
CM_ SG_ 2566545406 EvEnergyCapacity "EV Energy Capacity: Maximum energy capacity supported by the EV.See SAE J2847-2 201504 Sect 4.2.24";
CM_ SG_ 2566545406 EvEnergyRequested "EV Energy Requested: Amount of energy the EV requests from the EVSESee SAE J2847-2 201504 Sect 4.2.25";
CM_ BO_ 2566545662 "EV DC Charging In Progress";
CM_ SG_ 2566545662 EvBulkChargingComplete "EV Bulk Charging Complete: Optional, for EVSE display purposes, this parameter indicates if bulk charging is complete.00b = Bulk charging not complete01b = Bulk charging complete10b = Error11b = Not availableSee SAE J2847-2 201504 Sect 4.2.2...";
CM_ SG_ 2566545662 EvFullChargingComplete "EV Full Charging Complete: For EVSE display purposes, this parameter indicates if full charging is complete.00b = Full charging not complete01b = Full charging complete10b = Error11b = Not availableSee SAE J2847-2 201504 Sect 4.2.5";
CM_ SG_ 2566545662 EvBulkChargeTimeRemaining "EV Bulk Charge Time Remaining: Remaining time to complete bulk charging.See SAE J2847-2 201504 Sect 4.2.76";
CM_ SG_ 2566545662 EvFullChargeTimeRemaining "EV Full Charge Time Remaining: Remaining time to complete full charging.See SAE J2847-2 201504 Sect 4.2.77";
CM_ SG_ 2566545662 EvDepartureTime "EV Departure Time: Time remaining until the vehicle's expected departure.See ISO 15118-2/Figure 92 Ref. V2G2-371";
CM_ BO_ 2566546174 "Lighting Data 2";
CM_ SG_ 2566546174 TractorHazardLights "Tractor Hazard Lights: This parameter provides measured data from the vehicle's hazard lights.00b = De-activated01b = Activated10b = Fault Detected11b = Not Available";
CM_ BO_ 2365219838 "Lighting Command 2";
CM_ SG_ 2365219838 LightingData2RequestCommand "Lighting Data 2 Request Command: Command to provide a response of the light state for the light commands in this message.00b = Response not requested01b = Response requested10b = Reserved11b = Don't Care";
CM_ SG_ 2365219838 TractorHazardLightsCommand "Tractor Hazard Lights Command: Command to activate or de-activate the tractor hazard lights.00b = De-activate01b = Activate10b = Reserved11b = Don't Care";
CM_ BO_ 2566546686 "Aftertreatment System Information 5";
CM_ SG_ 2566546686 Aftrtrtmnt1SrIntkHghTmprtrCnt "Aftertreatment 1 SCR Intake High Temperature Count: The total occurrences of diagnostic code for the Aftertreatment 1 SCR Intake High Temperature.This parameter will accumulate over the life of the product and will never be reset.(Reference EU Commis...";
CM_ SG_ 2566546686 Aftrtrtmnt1TtlEvntCntWthNDfDlvr "Aftertreatment 1 Total Event Count With No DEF Delivery: The total occurrences of diagnostic code for the Aftertreatment With No DEF Delivery that have been active above a predetermined time threshold. A bucket that has been active less than the pred...";
CM_ BO_ 2566546942 "Aftertreatment System Information 4";
CM_ SG_ 2566546942 AftrtrtmntSrMlfntnCnt "Aftertreatment SCR Malfunction Count: The total occurrences of diagnostic code for the Aftertreatment SCR Malfunction that have been active above a predetermined time threshold. A bucket that has been active less than the predetermined time threshold...";
CM_ SG_ 2566546942 DieselExhaustFluidFrozenCount "Diesel Exhaust Fluid Frozen Count: The total occurrences of diagnostic code for the Diesel Exhaust Fluid Frozen.This parameter will accumulate over the life of the product and will never be reset.(Reference EU Commission Delegated Regulation 2016-838...";
CM_ BO_ 2566547198 "Aftertreatment System Information 3";
CM_ SG_ 2566547198 DslExhstFldTnk1EmptCnt "Diesel Exhaust Fluid Tank 1 Empty Count: The total occurrences of diagnostic code for the Diesel Exhaust Fluid Tank 1 Empty. This parameter will accumulate over the life of the product and will never be reset.(Reference EU Commission Delegated Regula...";
CM_ SG_ 2566547198 DslExhstFldQltMlfntnCnt "Diesel Exhaust Fluid Quality Malfunction Count: The total occurrences of diagnostic code for the Diesel Exhaust Fluid Quality Malfunction that have been active above a predetermined time threshold. A bucket that has been active less than the predeter...";
CM_ BO_ 2633656318 "Fluid Resistance 1";
CM_ SG_ 2633656318 EngineOilResistance "Engine Oil Resistance: Electric resistance of engine oil";
CM_ SG_ 2633656318 HydraulicOilResistance "Hydraulic Oil Resistance: Electric resistance of hydraulic oil";
CM_ BO_ 2566547710 "Power Converter 2 Isolation Integrity Request";
CM_ SG_ 2566547710 PwCvt2HVtBsAtvIstTstCd "Power Converter 2 High-Voltage Bus Active Isolation Test Command: Command for the Power Converter to perform an active electrical isolation test on the high voltage bus.An active isolation test might use a generated signal (e.g. an injected AC signal...";
CM_ SG_ 2566547710 PwCvt2HVtBsPssvIstTstCd "Power Converter 2 High-Voltage Bus Passive Isolation Test Command: Command for the Power Converter to perform a passive electrical isolation test on the high voltage bus.A passive isolation test uses additional circuitry (e.g. a high impedance networ...";
CM_ SG_ 2566547710 PwCvt2HVtBsHSdRsstCtRqst "Power Converter 2 High-Voltage Bus High Side Resistor Connect Request: This parameter is used to request connection of the Power Converter High-Voltage bus high side resistor in order to perform an isolation test.00b = Connection not Requested01b = C...";
CM_ SG_ 2566547710 PwCvt2HVtBsLwSdRsstCtRqst "Power Converter 2 High-Voltage Bus Low Side Resistor Connect Request: This parameter is used to request connection of the Power Converter High-Voltage bus low side resistor in order to perform an isolation test.00b = Connection not Requested01b = Con...";
CM_ BO_ 2566547966 "Power Converter 1 Isolation Integrity Request";
CM_ SG_ 2566547966 PwCvt1HVtBsAtvIstTstCd "Power Converter 1 High-Voltage Bus Active Isolation Test Command: Command for the Power Converter to perform an active electrical isolation test on the high voltage bus.An active isolation test might use a generated signal (e.g. an injected AC signal...";
CM_ SG_ 2566547966 PwCvt1HVtBsPssvIstTstCd "Power Converter 1 High-Voltage Bus Passive Isolation Test Command: Command for the Power Converter to perform a passive electrical isolation test on the high voltage bus.A passive isolation test uses additional circuitry (e.g. a high impedance networ...";
CM_ SG_ 2566547966 PwCvt1HVtBsHSdRsstCtRqst "Power Converter 1 High-Voltage Bus High Side Resistor Connect Request: This parameter is used to request connection of the Power Converter High-Voltage bus high side resistor in order to perform an isolation test. 00b = Connection not Requested01b = ...";
CM_ SG_ 2566547966 PwCvt1HVtBsLwSdRsstCtRqst "Power Converter 1 High-Voltage Bus Low Side Resistor Connect Request: This parameter is used to request connection of the Power Converter High-Voltage bus low side resistor in order to perform an isolation test.  00b = Connection not Requested01b = C...";
CM_ BO_ 2566548222 "Power Converter 2 Limits Request Power";
CM_ SG_ 2566548222 PwrCnvrtr2LmtsRqstPwrCr "Power Converter 2 Limits Request Power CRC: The CRC is defined as follows: - Length: 8 bits- Polynomial: x^8+x^5+x^3+x^2+x+1- Initial Value: FFh- Input Data Reflection: Not reflected- Result Data Reflection: Not reflected- XOR value: FFh SAE makes no...";
CM_ SG_ 2566548222 PwrCnvrtr2LmtsRqstPwrCntr "Power Converter 2 Limits Request Power Counter: The message counter is used to detect situations where the transmitting ECU malfunction repeats the same frame all the time. The receiver of the information may use the counter parameter to detect this ...";
CM_ SG_ 2566548222 PwrCnvrtr2LmtsRqstEltrlPwrMxmm "Power Converter 2 Limits Request Electrical Power Maximum: This requests a maximum limit for the electrical power.Refer to SPN 20669 (Power Converter 2 Reference Power) to convert % to kW. Request a value of FBFh to instruct the Power Converter to us...";
CM_ SG_ 2566548222 PwrCnvrtr2LmtsRqstEltrlPwrMnmm "Power Converter 2 Limits Request Electrical Power Minimum: This requests a minimum limit for the electrical power.Refer to SPN 20702 (Power Converter 1 Reference Power) to convert % to kW. Request a value of FBFh to instruct the Power Converter to us...";
CM_ SG_ 2566548222 PwCvt2LtsRqstDES1PwMx "Power Converter 2 Limits Request DC Energy Source 1 Power Maximum: This requests a maximum limit for the DC Energy Source 1 power.Refer to SPN 20669 (Power Converter 2 Reference Power) to convert % to kW. Request a value of FBFh to instruct the Power...";
CM_ SG_ 2566548222 PwCvt2LtsRqstDES1PwM "Power Converter 2 Limits Request DC Energy Source 1 Power Minimum: This requests a minimum limit for the DC Energy Source 1 power.Refer to SPN 20669 (Power Converter 2 Reference Power) to convert % to kW. Request a value of FBFh to instruct the Power...";
CM_ BO_ 2566548478 "Power Converter 2 Limits Request Electrical";
CM_ SG_ 2566548478 PwrCnvrtr2LmtsRqstEltrlCr "Power Converter 2 Limits Request Electrical CRC: The CRC is defined as follows: - Length: 8 bits- Polynomial: x^8+x^5+x^3+x^2+x+1- Initial Value: FFh- Input Data Reflection: Not reflected- Result Data Reflection: Not reflected- XOR value: FFh SAE mak...";
CM_ SG_ 2566548478 PwrCnvrtr2LmtsRqstEltrlCntr "Power Converter 2 Limits Request Electrical Counter: The message counter is used to detect situations where the transmitting ECU malfunction repeats the same frame all the time. The receiver of the information may use the counter parameter to detect ...";
CM_ SG_ 2566548478 PwrCnvrtr2LmtsRqstCrrntMxmm "Power Converter 2 Limits Request Current Maximum: This requests a maximum current the Power Converter should command for this device.Refer to SPN 20667 (Power Converter 2 Reference Current) to convert % to A. Request a value of FBFh to instruct the P...";
CM_ SG_ 2566548478 PwrCnvrtr2LmtsRqstCrrntMnmm "Power Converter 2 Limits Request Current Minimum: This requests a minimum current the Power Converter should command for this device.Refer to SPN 20667 (Power Converter 2 Reference Current) to convert % to A. Request a value of FBFh to instruct the P...";
CM_ SG_ 2566548478 PwrCnvrtr2LmtsRqstFrqnMxmm "Power Converter 2 Limits Request Frequency Maximum: This is a request to the Power Converter to set a maximum frequency limit for this device.Refer to SPN 20668 (Power Converter 2 Reference Frequency) to convert % to Hz. Request a value of FBFh to in...";
CM_ SG_ 2566548478 PwrCnvrtr2LmtsRqstFrqnMnmm "Power Converter 2 Limits Request Frequency Minimum: This is a request to the Power Converter to set a minimum frequency limit for this device.Refer to SPN 20668 (Power Converter 2 Reference Frequency) to convert % to Hz. Request a value of FBFh to in...";
CM_ BO_ 2566548734 "Power Converter 2 Limits Request DC Energy Source 1";
CM_ SG_ 2566548734 PwrCnvrtr2LmtsRqstDEnrgSr1Cr "Power Converter 2 Limits Request DC Energy Source 1 CRC: The CRC is defined as follows: - Length: 8 bits- Polynomial: x^8+x^5+x^3+x^2+x+1- Initial Value: FFh- Input Data Reflection: Not reflected- Result Data Reflection: Not reflected- XOR value: FFh...";
CM_ SG_ 2566548734 PwrCnvrtr2LmtsRqstDEnrgSr1Cntr "Power Converter 2 Limits Request DC Energy Source 1 Counter: The message counter is used to detect situations where the transmitting ECU malfunction repeats the same frame all the time. The receiver of the information may use the counter parameter to...";
CM_ SG_ 2566548734 PwCvt2LtsRqstDES1VtMx "Power Converter 2 Limits Request DC Energy Source 1 Voltage Maximum: This is a request to the Power Converter to set a maximum DC Energy Source 1 Voltage limit for this device instance.Refer to SPN 20679 (Power Converter 2 Reference Voltage) to conve...";
CM_ SG_ 2566548734 PwCvt2LtsRqstDES1VtM "Power Converter 2 Limits Request DC Energy Source 1 Voltage Minimum: This is a request to the Power Converter to set a minimum DC Energy Source 1 Voltage limit for this device instance.Refer to SPN 20679 (Power Converter 2 Reference Voltage) to conve...";
CM_ SG_ 2566548734 PwCvt2LtsRqstDES1CtMx "Power Converter 2 Limits Request DC Energy Source 1 Current Maximum: This is a request to the Power Converter to set a maximum DC Energy Source 1 Current limit for this device instance.Refer to SPN 20667 (Power Converter 2 Reference Current) to conve...";
CM_ SG_ 2566548734 PwCvt2LtsRqstDES1CtM "Power Converter 2 Limits Request DC Energy Source 1 Current Minimum: This is a request to the Power Converter to set a minimum DC Energy Source 1 Current limit for this device instance.Refer to SPN 20667 (Power Converter 2 Reference Current) to conve...";
CM_ BO_ 2566548990 "Power Converter 1 Limits Request DC Energy Source 1";
CM_ SG_ 2566548990 PwrCnvrtr1LmtsRqstDEnrgSr1Cr "Power Converter 1 Limits Request DC Energy Source 1 CRC: The CRC is defined as follows: - Length: 8 bits- Polynomial: x^8+x^5+x^3+x^2+x+1- Initial Value: FFh- Input Data Reflection: Not reflected- Result Data Reflection: Not reflected- XOR value: FFh...";
CM_ SG_ 2566548990 PwrCnvrtr1LmtsRqstDEnrgSr1Cntr "Power Converter 1 Limits Request DC Energy Source 1 Counter: The message counter is used to detect situations where the transmitting ECU malfunction repeats the same frame all the time. The receiver of the information may use the counter parameter to...";
CM_ SG_ 2566548990 PwCvt1LtsRqstDES1VtMx "Power Converter 1 Limits Request DC Energy Source 1 Voltage Maximum: This is a request to the Power Converter to set a maximum DC Energy Source 1 Voltage limit for this device instance.Refer to SPN 20691 (Power Converter 1 Reference Voltage) to conve...";
CM_ SG_ 2566548990 PwCvt1LtsRqstDES1VtM "Power Converter 1 Limits Request DC Energy Source 1 Voltage Minimum: This is a request to the Power Converter to set a minimum DC Energy Source 1 Voltage limit for this device instance.Refer to SPN 20691 (Power Converter 1 Reference Voltage) to conve...";
CM_ SG_ 2566548990 PwCvt1LtsRqstDES1CtMx "Power Converter 1 Limits Request DC Energy Source 1 Current Maximum: This is a request to the Power Converter to set a maximum DC Energy Source 1 Current limit for this device instance.Refer to SPN 20690 (Power Converter 1 Reference Current) to conve...";
CM_ SG_ 2566548990 PwCvt1LtsRqstDES1CtM "Power Converter 1 Limits Request DC Energy Source 1 Current Minimum: This is a request to the Power Converter to set a minimum DC Energy Source 1 Current limit for this device instance.Refer to SPN 20690 (Power Converter 1 Reference Current) to conve...";
CM_ BO_ 2566549246 "Power Converter 1 Limits Request Electrical";
CM_ SG_ 2566549246 PwrCnvrtr1LmtsRqstEltrlCr "Power Converter 1 Limits Request Electrical CRC: The CRC is defined as follows: - Length: 8 bits- Polynomial: x^8+x^5+x^3+x^2+x+1- Initial Value: FFh- Input Data Reflection: Not reflected- Result Data Reflection: Not reflected- XOR value: FFh SAE mak...";
CM_ SG_ 2566549246 PwrCnvrtr1LmtsRqstEltrlCntr "Power Converter 1 Limits Request Electrical Counter: The message counter is used to detect situations where the transmitting ECU malfunction repeats the same frame all the time. The receiver of the information may use the counter parameter to detect ...";
CM_ SG_ 2566549246 PwrCnvrtr1LmtsRqstCrrntMxmm "Power Converter 1 Limits Request Current Maximum: This requests a maximum current the Power Converter should command for this device.Refer to SPN 20690 (Power Converter 1 Reference Current) to convert % to A. Request a value of FBFh to instruct the P...";
CM_ SG_ 2566549246 PwrCnvrtr1LmtsRqstCrrntMnmm "Power Converter 1 Limits Request Current Minimum: This requests a minimum current the Power Converter should command for this device.Refer to SPN 20690 (Power Converter 1 Reference Current) to convert % to A. Request a value of FBFh to instruct the P...";
CM_ SG_ 2566549246 PwrCnvrtr1LmtsRqstFrqnMxmm "Power Converter 1 Limits Request Frequency Maximum: This is a request to the Power Converter to set a maximum frequency limit for this device.Refer to SPN 20701 (Power Converter 1 Reference Frequency) to convert % to Hz. Request a value of FBFh to in...";
CM_ SG_ 2566549246 PwrCnvrtr1LmtsRqstFrqnMnmm "Power Converter 1 Limits Request Frequency Minimum: This is a request to the Power Converter to set a minimum frequency limit for this device.Refer to SPN 20701 (Power Converter 1 Reference Frequency) to convert % to Hz. Request a value of FBFh to in...";
CM_ BO_ 2566549502 "Power Converter 1 Limits Request Power";
CM_ SG_ 2566549502 PwrCnvrtr1LmtsRqstPwrCr "Power Converter 1 Limits Request Power CRC: The CRC is defined as follows: - Length: 8 bits- Polynomial: x^8+x^5+x^3+x^2+x+1- Initial Value: FFh- Input Data Reflection: Not reflected- Result Data Reflection: Not reflected- XOR value: FFh SAE makes no...";
CM_ SG_ 2566549502 PwrCnvrtr1LmtsRqstPwrCntr "Power Converter 1 Limits Request Power Counter: The message counter is used to detect situations where the transmitting ECU malfunction repeats the same frame all the time. The receiver of the information may use the counter parameter to detect this ...";
CM_ SG_ 2566549502 PwrCnvrtr1LmtsRqstEltrlPwrMxmm "Power Converter 1 Limits Request Electrical Power Maximum: This requests a maximum limit for the electrical power.Refer to SPN 20702 (Power Converter 1 Reference Power) to convert % to kW. Request a value of FBFh to instruct the Power Converter to us...";
CM_ SG_ 2566549502 PwrCnvrtr1LmtsRqstEltrlPwrMnmm "Power Converter 1 Limits Request Electrical Power Minimum: This requests a minimum limit for the electrical power.Refer to SPN 20702 (Power Converter 1 Reference Power) to convert % to kW. Request a value of FBFh to instruct the Power Converter to us...";
CM_ SG_ 2566549502 PwCvt1LtsRqstDES1PwMx "Power Converter 1 Limits Request DC Energy Source 1 Power Maximum: This requests a maximum limit for the DC Energy Source 1 power.Refer to SPN 20702 (Power Converter 1 Reference Power) to convert % to kW. Request a value of FBFh to instruct the Power...";
CM_ SG_ 2566549502 PwCvt1LtsRqstDES1PwM "Power Converter 1 Limits Request DC Energy Source 1 Power Minimum: This requests a minimum limit for the DC Energy Source 1 power.Refer to SPN 20702 (Power Converter 1 Reference Power) to convert % to kW. Request a value of FBFh to instruct the Power...";
CM_ BO_ 2566549758 "Inverter 1 Lifetime Data";
CM_ SG_ 2566549758 PwrCnvrtr1TtlEnrgCnsmd "Power Converter 1 Total Energy Consumed: Indicates the total lifetime energy consumed by this Inverter.  For example, this would include the energy used for propulsion in a propulsion system.";
CM_ SG_ 2566549758 PwrCnvrtr1TtlEnrgGnrtd "Power Converter 1 Total Energy Generated : Indicates the total lifetime energy generated by this Inverter.  For example, this would include the energy created during regerative braking in a propulsion system.";
CM_ SG_ 2566549758 PwrCnvrtr1TtlChrgCnsmd "Power Converter 1 Total Charge Consumed: Indicates the total lifetime charge consumed by this Inverter.  For example, this would include the charge used for propulsion in a propulsion system.";
CM_ SG_ 2566549758 PwrCnvrtr1TtlChrgGnrtd "Power Converter 1 Total Charge Generated: Indicates the total lifetime charge generated by this Inverter.  For example, this would include the charge created during regerative braking in a propulsion system.";
CM_ BO_ 2566550014 "Inverter 2 Lifetime Data";
CM_ SG_ 2566550014 PwrCnvrtr2TtlEnrgCnsmd "Power Converter 2 Total Energy Consumed: Indicates the total lifetime energy consumed by this Inverter.  For example, this would include the energy used for propulsion in a propulsion system.";
CM_ SG_ 2566550014 PwrCnvrtr2TtlEnrgGnrtd "Power Converter 2 Total Energy Generated : Indicates the total lifetime energy generated by this Inverter.  For example, this would include the energy created during regerative braking in a propulsion system.";
CM_ SG_ 2566550014 PwrCnvrtr2TtlChrgCnsmd "Power Converter 2 Total Charge Consumed: Indicates the total lifetime charge consumed by this Inverter.  For example, this would include the charge used for propulsion in a propulsion system.";
CM_ SG_ 2566550014 PwrCnvrtr2TtlChrgGnrtd "Power Converter 2 Total Charge Generated: Indicates the total lifetime charge generated by this Inverter.  For example, this would include the charge created during regerative braking in a propulsion system.";
CM_ BO_ 2566550270 "Power Converter 2 Active Power Limits";
CM_ SG_ 2566550270 PwrCnvrtr2PwrLmtdDTUndfndRsn "Power Converter 2 Power Limited due to Undefined Reason: Output power is being limited due to an undefined reason.00b = No power limit for this reason01b = Power limited for this reason10b = Error11b = Not Available";
CM_ SG_ 2566550270 PwCvt2PwLtdDTDES1CtMx "Power Converter 2 Power Limited due to DC Energy Source 1 Current Maximum: Output power is being limited due to SPN 20674 (Power Converter 2 DC Energy Source 1 Current) approaching or exceeding the SPN 20589 (Power Converter 2 Limits Active DC Energy...";
CM_ SG_ 2566550270 PwCvt2PwLtdDTDES1CtM "Power Converter 2 Power Limited due to DC Energy Source 1 Current Minimum: Output power is being limited due to SPN 20674 (Power Converter 2 DC Energy Source 1 Current) approaching or falling below the SPN 20590 (Power Converter 2 Limits Active DC En...";
CM_ SG_ 2566550270 PwCvt2PwLtdDTDES1VtMx "Power Converter 2 Power Limited due to DC Energy Source 1 Voltage Maximum: Output power is being limited due to SPN 20675(Power Converter 2 DC Energy Source 1 Voltage) approaching or exceeding the SPN 20587 (Power Converter 2 Limits Active DC Energy ...";
CM_ SG_ 2566550270 PwCvt2PwLtdDTDES1VtM "Power Converter 2 Power Limited due to DC Energy Source 1 Voltage Minimum: Output power is being limited due to SPN 20675(Power Converter 2 DC Energy Source 1 Voltage) approaching or falling below the SPN 20588 (Power Converter 2 Limits Active DC Ene...";
CM_ SG_ 2566550270 PwrCnvrtr2PwrLmtdDTEltrlPwrMxmm "Power Converter 2 Power Limited due to Electrical Power Maximum: Output power is being limited due to Electrical Power (product of SPN 20672(Power Converter 2 Current) and SPN 20673(Power Converter 2 Frequency)) approaching or exceeding the SPN 20575...";
CM_ SG_ 2566550270 PwrCnvrtr2PwrLmtdDTEltrlPwrMnmm "Power Converter 2 Power Limited due to Electrical Power Minimum: Output power is being limited due to Electrical Power (product of SPN 20672(Power Converter 2 Current) and SPN 20673(Power Converter 2 Frequency)) approaching or falling below the SPN 2...";
CM_ SG_ 2566550270 PwCvt2PwLtdDTDES1PwMx "Power Converter 2 Power Limited due to DC Energy Source 1 Power Maximum: Output power is being limited due to DC Energy Source 1 Power (product of SPN 20674 (Power Converter 2 DC Energy Source 1 Current) and SPN 20675(Power Converter 2 DC Energy Sour...";
CM_ SG_ 2566550270 PwCvt2PwLtdDTDES1PwM "Power Converter 2 Power Limited due to DC Energy Source 1 Power Minimum: Output power is being limited due to DC Energy Source 1 Power (product of SPN 20674 (Power Converter 2 DC Energy Source 1 Current) and SPN 20675(Power Converter 2 DC Energy Sour...";
CM_ SG_ 2566550270 PwrCnvrtr2PwrLmtdDTCrrntMxmm "Power Converter 2 Power Limited due to Current Maximum: Output power is being limited due to SPN 20672(Power Converter 2 Current) approaching or exceeding the SPN 20581 (Power Converter 2 Limits Active Current Maximum).00b = No power limit for this r...";
CM_ SG_ 2566550270 PwrCnvrtr2PwrLmtdDTCrrntMnmm "Power Converter 2 Power Limited due to Current Minimum: Output power is being limited due to SPN 20672(Power Converter 2 Current) approaching or falling below the SPN 20582 (Power Converter 2 Limits Active Current Minimum).00b = No power limit for th...";
CM_ SG_ 2566550270 PwrCnvrtr2PwrLmtdDTFrqnMxmm "Power Converter 2 Power Limited due to Frequency Maximum: Output power is being limited due to SPN 20673(Power Converter 2 Frequency) approaching or exceeding the SPN 20583 (Power Converter 2 Limits Active Frequency Maximum).00b = No power limit for ...";
CM_ SG_ 2566550270 PwrCnvrtr2PwrLmtdDTFrqnMnmm "Power Converter 2 Power Limited due to Frequency Minimum: Output power is being limited due to SPN 20673(Power Converter 2 Frequency) approaching or falling below the SPN 20584 (Power Converter 2 Limits Active Frequency Minimum).00b = No power limit ...";
CM_ SG_ 2566550270 PwrCnvrtr2PwrLmtdDTInvrtrTmprtr "Power Converter 2 Power Limited due to Inverter Temperature: Output power is being limited due to one or more inverter temperature(s), see SPNs 10282 through 10285 (Inverter Temperature 1-4) approaching or exceeding internally defined limit(s).00b = ...";
CM_ SG_ 2566550270 PwrCnvrtr2PwrLmtdDTTmprtr "Power Converter 2 Power Limited due to Temperature: Output power is being limited due to one or more temperature(s), see SPNs 9060 and 10286 through 10288 (Temperature 1-4) approaching or exceeding internally defined limit(s).00b = No power limit for...";
CM_ SG_ 2566550270 PwrCnvrtr2PwrLmtdDTFltCndtn "Power Converter 2 Power Limited Due to Fault Condition: Output power is being limited due to an fault condition that requires a current limitation to prevent further damage (e.g. 'limp home mode').  For example, this could be in case of temperature s...";
CM_ SG_ 2566550270 PwCvt2PwLtdDTAtvCtRtLt "Power Converter 2 Power Limited Due to Active Current Rate Limit: Output power is being limited due to exceeding internally defined current rate limit(s) or SPN 20486 (Power Converter 2 Rate Limits Request Absolute Current Rate Limit).00b = No power ...";
CM_ SG_ 2566550270 PwCvt2CtLtdDTMCtsts "Power Converter 2 Current Limited Due to Machine Characteristics: Output current is being limited due to SPN 20672(Power Converter 2 Current) approaching or exceeding a system design characteristic.  For example, for permanent magnet machines, this w...";
CM_ BO_ 2566550526 "Power Converter 1 Active Power Limits";
CM_ SG_ 2566550526 PwrCnvrtr1PwrLmtdDTUndfndRsn "Power Converter 1 Power Limited due to Undefined Reason: Output power is being limited due to an undefined reason.00b = No power limit for this reason01b = Power limited for this reason10b = Error11b = Not Available";
CM_ SG_ 2566550526 PwCvt1PwLtdDTDES1CtMx "Power Converter 1 Power Limited due to DC Energy Source 1 Current Maximum: Output power is being limited due to SPN 20696 (Power Converter 1 DC Energy Source 1 Current) approaching or exceeding the SPN 20564 (Power Converter 1 Limits Active DC Energy...";
CM_ SG_ 2566550526 PwCvt1PwLtdDTDES1CtM "Power Converter 1 Power Limited due to DC Energy Source 1 Current Minimum: Output power is being limited due to SPN 20696 (Power Converter 1 DC Energy Source 1 Current) approaching or falling below the SPN 20565 (Power Converter 1 Limits Active DC En...";
CM_ SG_ 2566550526 PwCvt1PwLtdDTDES1VtMx "Power Converter 1 Power Limited due to DC Energy Source 1 Voltage Maximum: Output power is being limited due to SPN 20697(Power Converter 1 DC Energy Source 1 Voltage) approaching or exceeding the SPN 20562 (Power Converter 1 Limits Active DC Energy ...";
CM_ SG_ 2566550526 PwCvt1PwLtdDTDES1VtM "Power Converter 1 Power Limited due to DC Energy Source 1 Voltage Minimum: Output power is being limited due to SPN 20697(Power Converter 1 DC Energy Source 1 Voltage) approaching or falling below the SPN 20563 (Power Converter 1 Limits Active DC Ene...";
CM_ SG_ 2566550526 PwrCnvrtr1PwrLmtdDTEltrlPwrMxmm "Power Converter 1 Power Limited due to Electrical Power Maximum: Output power is being limited due to Electrical Power (product of SPN 20694(Power Converter 1 Current) and SPN 20695(Power Converter 1 Frequency)) approaching or exceeding the SPN 20550...";
CM_ SG_ 2566550526 PwrCnvrtr1PwrLmtdDTEltrlPwrMnmm "Power Converter 1 Power Limited due to Electrical Power Minimum: Output power is being limited due to Electrical Power (product of SPN 20694(Power Converter 1 Current) and SPN 20695(Power Converter 1 Frequency)) approaching or falling below the SPN 2...";
CM_ SG_ 2566550526 PwCvt1PwLtdDTDES1PwMx "Power Converter 1 Power Limited due to DC Energy Source 1 Power Maximum: Output power is being limited due to DC Energy Source 1 Power (product of SPN 20696 (Power Converter 1 DC Energy Source 1 Current) and SPN 20697(Power Converter 1 DC Energy Sour...";
CM_ SG_ 2566550526 PwCvt1PwLtdDTDES1PwM "Power Converter 1 Power Limited due to DC Energy Source 1 Power Minimum: Output power is being limited due to DC Energy Source 1 Power (product of SPN 20696 (Power Converter 1 DC Energy Source 1 Current) and SPN 20697(Power Converter 1 DC Energy Sour...";
CM_ SG_ 2566550526 PwrCnvrtr1PwrLmtdDTCrrntMxmm "Power Converter 1 Power Limited due to Current Maximum: Output power is being limited due to SPN 20694(Power Converter 1 Current) approaching or exceeding the SPN 20556 (Power Converter 1 Limits Active Current Maximum).00b = No power limit for this r...";
CM_ SG_ 2566550526 PwrCnvrtr1PwrLmtdDTCrrntMnmm "Power Converter 1 Power Limited due to Current Minimum: Output power is being limited due to SPN 20694(Power Converter 1 Current) approaching or falling below the SPN 20557 (Power Converter 1 Limits Active Current Minimum).00b = No power limit for th...";
CM_ SG_ 2566550526 PwrCnvrtr1PwrLmtdDTFrqnMxmm "Power Converter 1 Power Limited due to Frequency Maximum: Output power is being limited due to SPN 20695(Power Converter 1 Frequency) approaching or exceeding the SPN 20558 (Power Converter 1 Limits Active Frequency Maximum).00b = No power limit for ...";
CM_ SG_ 2566550526 PwrCnvrtr1PwrLmtdDTFrqnMnmm "Power Converter 1 Power Limited due to Frequency Minimum: Output power is being limited due to SPN 20695(Power Converter 1 Frequency) approaching or falling below the SPN 20559 (Power Converter 1 Limits Active Frequency Minimum).00b = No power limit ...";
CM_ SG_ 2566550526 PwrCnvrtr1PwrLmtdDTInvrtrTmprtr "Power Converter 1 Power Limited due to Inverter Temperature: Output power is being limited due to one or more inverter temperature(s), see SPNs 10216 through 10219 (Power Converter 1 Temperature 1-4) approaching or exceeding internally defined limit(...";
CM_ SG_ 2566550526 PwrCnvrtr1PwrLmtdDTTmprtr "Power Converter 1 Power Limited due to Temperature: Output power is being limited due to one or more temperature(s), see SPNs 9059 and 10220 through 10222 (Temperature 1-4) approaching or exceeding internally defined limit(s).00b = No power limit for...";
CM_ SG_ 2566550526 PwrCnvrtr1PwrLmtdDTFltCndtn "Power Converter 1 Power Limited Due to Fault Condition: Output power is being limited due to an fault condition that requires a current limitation to prevent further damage (e.g. 'limp home mode').  For example, this could be in case of temperature s...";
CM_ SG_ 2566550526 PwCvt1PwLtdDTAtvCtRtLt "Power Converter 1 Power Limited Due to Active Current Rate Limit: Output power is being limited due to exceeding internally defined current rate limit(s) or SPN 20482 (Power Converter 1 Rate Limits Request Absolute Current Rate Limit). 00b = No power...";
CM_ SG_ 2566550526 PwCvt1CtLtdDTMCtsts "Power Converter 1 Current Limited Due to Machine Characteristics: Output current is being limited due to SPN 20694(Power Converter 1 Current) approaching or exceeding a system design characteristic.  For example, for permanent magnet machines, this w...";
CM_ BO_ 2365224190 "Power Converter 2 Reference 1";
CM_ SG_ 2365224190 PowerConverter2Reference1Crc "Power Converter 2 Reference 1 CRC: The CRC is defined as follows: - Length: 8 bits- Polynomial: x^8+x^5+x^3+x^2+x+1- Initial Value: FFh- Input Data Reflection: Not reflected- Result Data Reflection: Not reflected- XOR value: FFh SAE makes no claim of...";
CM_ SG_ 2365224190 PwrCnvrtr2Rfrn1Cntr "Power Converter 2 Reference 1 Counter: The message counter is used to detect situations where the transmitting ECU malfunction repeats the same frame all the time. The receiver of the information may use the counter parameter to detect this situation...";
CM_ SG_ 2365224190 PwrCnvrtr2RfrnFrqn "Power Converter 2 Reference Frequency: This value is used for converting Frequency in percent to units of Hz.Value in Hz = (Percent Value)/(100%) * (Reference Frequency)For example, if this parameter has a value of 8192 Hz and the percent value is eq...";
CM_ SG_ 2365224190 PowerConverter2ReferencePower "Power Converter 2 Reference Power: This value is used for converting power in percent to units of kW.  It is applicable to both electrical and electrical power.(Value in kW) = (Percent Value)/(100%) * (Reference Power)For example, if this parameter h...";
CM_ SG_ 2365224190 PowerConverter2ReferenceTorque "Power Converter 2 Reference Torque: This value is used for converting torque in percent to units of Nm.Value in Nm = (Percent Value)/(100%) * (Reference Torque)For example, if this parameter has a value of 4000 Nm and the percent value is equal to 75...";
CM_ BO_ 2365224446 "Power Converter 2 Reference 2";
CM_ SG_ 2365224446 PowerConverter2ReferenceCurrent "Power Converter 2 Reference Current: This value is used for converting inverter current in percent to units of Amps (RMS or DC).(Value in Amps) = (Percent Value)/(100%) * (Reference Current)For example, if this parameter has a value of 200 A and the ...";
CM_ SG_ 2365224446 PowerConverter2Reference2Crc "Power Converter 2 Reference 2 CRC: The CRC is defined as follows: - Length: 8 bits- Polynomial: x^8+x^5+x^3+x^2+x+1- Initial Value: FFh- Input Data Reflection: Not reflected- Result Data Reflection: Not reflected- XOR value: FFh SAE makes no claim of...";
CM_ SG_ 2365224446 PwrCnvrtr2Rfrn2Cntr "Power Converter 2 Reference 2 Counter: The message counter is used to detect situations where the transmitting ECU malfunction repeats the same frame all the time. The receiver of the information may use the counter parameter to detect this situation...";
CM_ SG_ 2365224446 PowerConverter2ReferenceVoltage "Power Converter 2 Reference Voltage: This value is used for converting inverter voltage in percent to units of Volts (RMS or DC).(Value in Volts) = (Percent Value)/(100%) * (Reference Voltage)For example, if this parameter has a value of 400 V and th...";
CM_ BO_ 2566551294 "Power Converter 2 Temperature";
CM_ SG_ 2566551294 PowerConverter2Temperature1 "Power Converter 2 Temperature 1: The exact location of this temperature can be defined by the manufacturer.  It is intended to be located somewhere on the Power Converter. ";
CM_ SG_ 2566551294 PowerConverter2Temperature2 "Power Converter 2 Temperature 2: The exact location of this temperature can be defined by the manufacturer.  It is intended to be located somewhere on the Power Converter. ";
CM_ SG_ 2566551294 PowerConverter2Temperature3 "Power Converter 2 Temperature 3: The exact location of this temperature can be defined by the manufacturer.  It is intended to be located somewhere on the Power Converter. ";
CM_ SG_ 2566551294 PowerConverter2Temperature4 "Power Converter 2 Temperature 4: The exact location of this temperature can be defined by the manufacturer.  It is intended to be located somewhere on the Power Converter. ";
CM_ BO_ 2566551550 "Power Converter 1 Temperature";
CM_ SG_ 2566551550 PowerConverter1Temperature1 "Power Converter 1 Temperature 1: The exact location of this temperature can be defined by the manufacturer.  It is intended to be located somewhere on the Power Converter. ";
CM_ SG_ 2566551550 PowerConverter1Temperature2 "Power Converter 1 Temperature 2: The exact location of this temperature can be defined by the manufacturer.  It is intended to be located somewhere on the Power Converter. ";
CM_ SG_ 2566551550 PowerConverter1Temperature3 "Power Converter 1 Temperature 3: The exact location of this temperature can be defined by the manufacturer.  It is intended to be located somewhere on the Power Converter. ";
CM_ SG_ 2566551550 PowerConverter1Temperature4 "Power Converter 1 Temperature 4: The exact location of this temperature can be defined by the manufacturer.  It is intended to be located somewhere on the Power Converter. ";
CM_ BO_ 2365225214 "Power Converter 1 Reference 2";
CM_ SG_ 2365225214 PowerConverter1Reference2Crc "Power Converter 1 Reference 2 CRC: The CRC is defined as follows: - Length: 8 bits- Polynomial: x^8+x^5+x^3+x^2+x+1- Initial Value: FFh- Input Data Reflection: Not reflected- Result Data Reflection: Not reflected- XOR value: FFh SAE makes no claim of...";
CM_ SG_ 2365225214 PwrCnvrtr1Rfrn2Cntr "Power Converter 1 Reference 2 Counter: The message counter is used to detect situations where the transmitting ECU malfunction repeats the same frame all the time. The receiver of the information may use the counter parameter to detect this situation...";
CM_ SG_ 2365225214 PowerConverter1ReferenceCurrent "Power Converter 1 Reference Current: This value is used for converting inverter current in percent to units of Amps (RMS or DC).(Value in Amps) = (Percent Value)/(100%) * (Reference Current)For example, if this parameter has a value of 200 A and the ...";
CM_ SG_ 2365225214 PowerConverter1ReferenceVoltage "Power Converter 1 Reference Voltage: This value is used for converting inverter voltage in percent to units of Volts (RMS or DC).(Value in Volts) = (Percent Value)/(100%) * (Reference Voltage)For example, if this parameter has a value of 400 V and th...";
CM_ BO_ 2365225470 "Power Converter 1 Reference 1";
CM_ SG_ 2365225470 PowerConverter1Reference1Crc "Power Converter 1 Reference 1 CRC: The CRC is defined as follows: - Length: 8 bits- Polynomial: x^8+x^5+x^3+x^2+x+1- Initial Value: FFh- Input Data Reflection: Not reflected- Result Data Reflection: Not reflected- XOR value: FFh SAE makes no claim of...";
CM_ SG_ 2365225470 PwrCnvrtr1Rfrn1Cntr "Power Converter 1 Reference 1 Counter: The message counter is used to detect situations where the transmitting ECU malfunction repeats the same frame all the time. The receiver of the information may use the counter parameter to detect this situation...";
CM_ SG_ 2365225470 PwrCnvrtr1RfrnFrqn "Power Converter 1 Reference Frequency: This value is used for converting Frequency in percent to units of Hz.Value in Hz = (Percent Value)/(100%) * (Reference Frequency)For example, if this parameter has a value of 8192 Hz and the percent value is eq...";
CM_ SG_ 2365225470 PowerConverter1ReferencePower "Power Converter 1 Reference Power: This value is used for converting power in percent to units of kW.  It is applicable to both electrical and electrical power.(Value in kW) = (Percent Value)/(100%) * (Reference Power)For example, if this parameter h...";
CM_ SG_ 2365225470 PowerConverter1ReferenceTorque "Power Converter 1 Reference Torque: This value is used for converting torque in percent to units of Nm.Value in Nm = (Percent Value)/(100%) * (Reference Torque)For example, if this parameter has a value of 4000 Nm and the percent value is equal to 75...";
CM_ BO_ 2365225726 "Power Converter 1 Phase Current";
CM_ SG_ 2365225726 PwrCnvrtr1PwrCnvrtrPhsUCrrnt "Power Converter 1 Power Converter Phase U Current: Current output of phase U of Inverter 1.  Note:  Manufacturer-specific phase nomenclature (e.g. 1,2,3 or a,b,c) may differ.";
CM_ SG_ 2365225726 PwrCnvrtr1PwrCnvrtrPhsVCrrnt "Power Converter 1 Power Converter Phase V Current: Current output of phase V of Inverter 1.  Note:  Manufacturer-specific phase nomenclature (e.g. 1,2,3 or a,b,c) may differ.";
CM_ SG_ 2365225726 PwrCnvrtr1PwrCnvrtrPhsWCrrnt "Power Converter 1 Power Converter Phase W Current: Current output of phase W of Inverter 1.  Note:  Manufacturer-specific phase nomenclature (e.g. 1,2,3 or a,b,c) may differ.";
CM_ BO_ 2365225982 "Power Converter 2 Phase Current";
CM_ SG_ 2365225982 PwrCnvrtr2PwrCnvrtrPhsUCrrnt "Power Converter 2 Power Converter Phase U Current: Current output of phase U of Inverter 2.  Note:  Manufacturer-specific phase nomenclature (e.g. 1,2,3 or a,b,c) may differ.";
CM_ SG_ 2365225982 PwrCnvrtr2PwrCnvrtrPhsVCrrnt "Power Converter 2 Power Converter Phase V Current: Current output of phase V of Inverter 2.  Note:  Manufacturer-specific phase nomenclature (e.g. 1,2,3 or a,b,c) may differ.";
CM_ SG_ 2365225982 PwrCnvrtr2PwrCnvrtrPhsWCrrnt "Power Converter 2 Power Converter Phase W Current: Current output of phase W of Inverter 2.  Note:  Manufacturer-specific phase nomenclature (e.g. 1,2,3 or a,b,c) may differ.";
CM_ BO_ 2365226238 "Power Converter 1 Phase Voltage";
CM_ SG_ 2365226238 PwrCnvrtr1PwrCnvrtrPhsUVltg "Power Converter 1 Power Converter Phase U Voltage: Voltage output of phase U of Inverter 1.  Note:  Manufacturer-specific phase nomenclature (e.g. 1,2,3 or a,b,c) may differ.";
CM_ SG_ 2365226238 PwrCnvrtr1PwrCnvrtrPhsVVltg "Power Converter 1 Power Converter Phase V Voltage: Voltage output of phase V of Inverter 1.  Note:  Manufacturer-specific phase nomenclature (e.g. 1,2,3 or a,b,c) may differ.";
CM_ SG_ 2365226238 PwrCnvrtr1PwrCnvrtrPhsWVltg "Power Converter 1 Power Converter Phase W Voltage: Voltage output of phase W of Inverter 1.  Note:  Manufacturer-specific phase nomenclature (e.g. 1,2,3 or a,b,c) may differ.";
CM_ BO_ 2365226494 "Power Converter 2 Phase Voltage";
CM_ SG_ 2365226494 PwrCnvrtr2PwrCnvrtrPhsUVltg "Power Converter 2 Power Converter Phase U Voltage: Voltage output of phase U of Inverter 2.  Note:  Manufacturer-specific phase nomenclature (e.g. 1,2,3 or a,b,c) may differ.";
CM_ SG_ 2365226494 PwrCnvrtr2PwrCnvrtrPhsVVltg "Power Converter 2 Power Converter Phase V Voltage: Voltage output of phase V of Inverter 2.  Note:  Manufacturer-specific phase nomenclature (e.g. 1,2,3 or a,b,c) may differ.";
CM_ SG_ 2365226494 PwrCnvrtr2PwrCnvrtrPhsWVltg "Power Converter 2 Power Converter Phase W Voltage: Voltage output of phase W of Inverter 2.  Note:  Manufacturer-specific phase nomenclature (e.g. 1,2,3 or a,b,c) may differ.";
CM_ BO_ 2566553342 "Power Converter Power Module Switch Temperatures";
CM_ SG_ 2566553342 PwCvt1PwCvtPsUPwMdSwtTpt "Power Converter 1 Power Converter Phase U Power Module Switch Temperature: Indicates the temperature of the Phase U power module switch (e.g. transistor, IGBT or MOSFET) in this inverter instance.Note:  Manufacturer-specific phase nomenclature (e.g. ...";
CM_ SG_ 2566553342 PwCvt1PwCvtPsVPwMdSwtTpt "Power Converter 1 Power Converter Phase V Power Module Switch Temperature: Indicates the temperature of the Phase V power module switch (e.g. transistor, IGBT or MOSFET) in Inverter 1.Note:  Manufacturer-specific phase nomenclature (e.g. 1,2,3 or a,b...";
CM_ SG_ 2566553342 PwCvt1PwCvtPsWPwMdSwtTpt "Power Converter 1 Power Converter Phase W Power Module Switch Temperature: Indicates the temperature of the Phase W power module switch (e.g. transistor, IGBT or MOSFET) in Inverter 1.Note:  Manufacturer-specific phase nomenclature (e.g. 1,2,3 or a,b...";
CM_ SG_ 2566553342 PwCvt2PwCvtPsUPwMdSwtTpt "Power Converter 2 Power Converter Phase U Power Module Switch Temperature: Indicates the temperature of the Phase U power module switch (e.g. transistor, IGBT or MOSFET) in Inverter 2.Note:  Manufacturer-specific phase nomenclature (e.g. 1,2,3 or a,b...";
CM_ SG_ 2566553342 PwCvt2PwCvtPsVPwMdSwtTpt "Power Converter 2 Power Converter Phase V Power Module Switch Temperature: Indicates the temperature of the Phase V power module switch (e.g. transistor, IGBT or MOSFET) in Inverter 2.Note:  Manufacturer-specific phase nomenclature (e.g. 1,2,3 or a,b...";
CM_ SG_ 2566553342 PwCvt2PwCvtPsWPwMdSwtTpt "Power Converter 2 Power Converter Phase W Power Module Switch Temperature: Indicates the temperature of the Phase W power module switch (e.g. transistor, IGBT or MOSFET) in Inverter 2.Note:  Manufacturer-specific phase nomenclature (e.g. 1,2,3 or a,b...";
CM_ BO_ 2365227006 "Power Converter 1 Power Module Switch Power Supply Voltage";
CM_ SG_ 2365227006 PwCvt1PwCvtPsUPwMdSwtPwSppVt "Power Converter 1 Power Converter Phase U Power Module Switch Power Supply Voltage: Indicates the voltage being supplied to the Phase U power module switch (e.g. transistor, IGBT or MOSFET) in Inverter 1.Note:  Manufacturer-specific phase nomenclatur...";
CM_ SG_ 2365227006 PwCvt1PwCvtPsVPwMdSwtPwSppVt "Power Converter 1 Power Converter Phase V Power Module Switch Power Supply Voltage: Indicates the voltage being supplied to the Phase V power module switch (e.g. transistor, IGBT or MOSFET) in Inverter 1.Note:  Manufacturer-specific phase nomenclatur...";
CM_ SG_ 2365227006 PwCvt1PwCvtPsWPwMdSwtPwSppVt "Power Converter 1 Power Converter Phase W Power Module Switch Power Supply Voltage: Indicates the voltage being supplied to the Phase W power module switch (e.g. transistor, IGBT or MOSFET) in Inverter 1.Note:  Manufacturer-specific phase nomenclatur...";
CM_ BO_ 2365227262 "Power Converter 2 Power Module Switch Power Supply Voltage";
CM_ SG_ 2365227262 PwCvt2PwCvtPsUPwMdSwtPwSppVt "Power Converter 2 Power Converter Phase U Power Module Switch Power Supply Voltage: Indicates the voltage being supplied to the Phase U power module switch (e.g. transistor, IGBT or MOSFET) in Inverter 2.Note:  Manufacturer-specific phase nomenclatur...";
CM_ SG_ 2365227262 PwCvt2PwCvtPsVPwMdSwtPwSppVt "Power Converter 2 Power Converter Phase V Power Module Switch Power Supply Voltage: Indicates the voltage being supplied to the Phase V power module switch (e.g. transistor, IGBT or MOSFET) in Inverter 2.Note:  Manufacturer-specific phase nomenclatur...";
CM_ SG_ 2365227262 PwCvt2PwCvtPsWPwMdSwtPwSppVt "Power Converter 2 Power Converter Phase W Power Module Switch Power Supply Voltage: Indicates the voltage being supplied to the Phase W power module switch (e.g. transistor, IGBT or MOSFET) in Inverter 2.Note:  Manufacturer-specific phase nomenclatur...";
CM_ BO_ 2365227518 "Power Converter Totals 1";
CM_ SG_ 2365227518 PwrCnvrtr1PwrCnvrtrACrrntOtpt "Power Converter 1 Power Converter AC Current Output: The AC current being produced by Inverter 1.";
CM_ SG_ 2365227518 PwrCnvrtr2PwrCnvrtrACrrntOtpt "Power Converter 2 Power Converter AC Current Output: The AC current being produced by Inverter 2.";
CM_ SG_ 2365227518 PwCvt1PwCvtPwMdSwtTpt "Power Converter 1 Power Converter Power Module Switch Temperature: Indicates the overall power module switch (e.g. transistor, IGBT or MOSFET) temperature in Inverter 1.";
CM_ SG_ 2365227518 PwCvt2PwCvtPwMdSwtTpt "Power Converter 2 Power Converter Power Module Switch Temperature: Indicates the overall power module switch (e.g. transistor, IGBT or MOSFET) temperature in Inverter 2.";
CM_ BO_ 2566554366 "Transformer Temperatures";
CM_ SG_ 2566554366 Transformer1PhaseUTemperature "Transformer 1 Phase U Temperature: Indicates the temperature of the Phase U in this transformer instance.Note:  Manufacturer-specific phase nomenclature (e.g. 1,2,3 or a,b,c) may differ.";
CM_ SG_ 2566554366 Transformer1PhaseVTemperature "Transformer 1 Phase V Temperature: Indicates the temperature of the Phase V in transformer 1.Note:  Manufacturer-specific phase nomenclature (e.g. 1,2,3 or a,b,c) may differ.";
CM_ SG_ 2566554366 Transformer1PhaseWTemperature "Transformer 1 Phase W Temperature: Indicates the temperature of the Phase W in transformer 1.Note:  Manufacturer-specific phase nomenclature (e.g. 1,2,3 or a,b,c) may differ.";
CM_ SG_ 2566554366 Transformer2PhaseUTemperature "Transformer 2 Phase U Temperature: Indicates the temperature of the Phase U in transformer 2.Note:  Manufacturer-specific phase nomenclature (e.g. 1,2,3 or a,b,c) may differ.";
CM_ SG_ 2566554366 Transformer2PhaseVTemperature "Transformer 2 Phase V Temperature: Indicates the temperature of the Phase V in transformer 2.Note:  Manufacturer-specific phase nomenclature (e.g. 1,2,3 or a,b,c) may differ.";
CM_ SG_ 2566554366 Transformer2PhaseWTemperature "Transformer 2 Phase W Temperature: Indicates the temperature of the Phase W in transformer 2.Note:  Manufacturer-specific phase nomenclature (e.g. 1,2,3 or a,b,c) may differ.";
CM_ BO_ 2566554622 "Electrified Accessory Engine Coolant Pump Status";
CM_ SG_ 2566554622 EngnClntEltrPmpEnlStts "Engine Coolant Electric Pump Enable Status: Enable and direction status of the Engine Coolant Electric Pump system or component.00b = Motor Off01b = Motor On - Normal, Forward, or Default Direction10b = Motor On - Reverse Direction11b = Not available...";
CM_ SG_ 2566554622 EngnClntEltrPmpCntrllrSttsRsn "Engine Coolant Electric Pump Controller Status Reason: Provides the reason code describing the unique failure of the Engine Coolant Electric Pump system or component.If a detailed reason code is not used by the supporting application, or this reason ...";
CM_ SG_ 2566554622 EngnClntEltrPmpCntrllrCmmndStts "Engine Coolant Electric Pump Controller Command Status: Indicates the source of the speed command to the Engine Electric Coolant Pump system or component.00b = Internal Command01b = External Command10b = Default Command11b = Not AvailableNote:00b is ...";
CM_ SG_ 2566554622 EngnClntEltrPmpMtrSpd "Engine Coolant Electric Pump Motor Speed: Motor Speed of the Engine Coolant Electric Pump.";
CM_ SG_ 2566554622 EngnClntEltrPmpCntrlTmprtr "Engine Coolant Electric Pump Control Temperature: A temperature measured and reported by the device.It may be used for direct or remote (e.g. by another controller) control of the pump. For example, this may be the temperature of the fluid flowing th...";
CM_ SG_ 2566554622 EngineCoolantElectricPumpPower "Engine Coolant Electric Pump Power: Calculated electrical power consumed by the Engine Coolant Electric Pump.";
CM_ SG_ 2566554622 EngnClntEltrPmpSrvIndtr "Engine Coolant Electric Pump Service Indicator: Indicates that service is required for the Engine Coolant Electric Pump system or component.An active indication may convey a need for component replacement or periodic service. The Engine Coolant Elect...";
CM_ SG_ 2566554622 EngnClntEltrPmpOprtngStts "Engine Coolant Electric Pump Operating Status: Indicates the operating status of the Engine Coolant Electric Pump system or component.This parameter is used to inform other devices that this system or component is no longer performing to its operatio...";
BA_DEF_ SG_  "SPN" INT 0 524287;
BA_DEF_ BO_  "VFrameFormat" ENUM  "StandardCAN","ExtendedCAN","reserved","J1939PG";
BA_DEF_DEF_  "SPN" 0;
BA_DEF_DEF_  "VFrameFormat" "J1939PG";
BA_ "SPN" SG_ 2364747006 Hvesp25Module1OperationalStatus 17325;
BA_ "SPN" SG_ 2364747006 Hvesp25Module2OperationalStatus 17326;
BA_ "SPN" SG_ 2364747006 Hvesp25Module3OperationalStatus 17327;
BA_ "SPN" SG_ 2364747006 Hvesp25Module4OperationalStatus 17328;
BA_ "SPN" SG_ 2364747006 Hvesp25Module5OperationalStatus 17329;
BA_ "SPN" SG_ 2364747006 Hvesp25Module6OperationalStatus 17330;
BA_ "SPN" SG_ 2364747006 Hvesp25Module7OperationalStatus 17331;
BA_ "SPN" SG_ 2364747006 Hvesp25Module8OperationalStatus 17332;
BA_ "SPN" SG_ 2364747006 Hvesp25Module9OperationalStatus 17333;
BA_ "SPN" SG_ 2364747006 Hvsp25Mdl10OprtnlStts 17334;
BA_ "SPN" SG_ 2364747006 Hvsp25Mdl11OprtnlStts 17335;
BA_ "SPN" SG_ 2364747006 Hvsp25Mdl12OprtnlStts 17336;
BA_ "SPN" SG_ 2364747006 Hvsp25Mdl13OprtnlStts 17337;
BA_ "SPN" SG_ 2364747006 Hvsp25Mdl14OprtnlStts 17338;
BA_ "SPN" SG_ 2364747006 Hvsp25Mdl15OprtnlStts 17339;
BA_ "SPN" SG_ 2364747006 Hvsp25Mdl16OprtnlStts 17340;
BA_ "SPN" SG_ 2364747006 Hvsp25Mdl17OprtnlStts 17341;
BA_ "SPN" SG_ 2364747006 Hvsp25Mdl18OprtnlStts 17342;
BA_ "SPN" SG_ 2364747006 Hvsp25Mdl19OprtnlStts 17343;
BA_ "SPN" SG_ 2364747006 Hvsp25Mdl20OprtnlStts 17344;
BA_ "SPN" SG_ 2364747006 Hvsp25Mdl21OprtnlStts 17345;
BA_ "SPN" SG_ 2364747006 Hvsp25Mdl22OprtnlStts 17346;
BA_ "SPN" SG_ 2364747006 Hvsp25Mdl23OprtnlStts 17347;
BA_ "SPN" SG_ 2364747006 Hvsp25Mdl24OprtnlStts 17348;
BA_ "SPN" SG_ 2364747006 Hvsp25Mdl25OprtnlStts 17349;
BA_ "SPN" SG_ 2364747006 Hvsp25Mdl26OprtnlStts 17350;
BA_ "SPN" SG_ 2364747006 Hvsp25Mdl27OprtnlStts 17351;
BA_ "SPN" SG_ 2364747006 Hvsp25Mdl28OprtnlStts 17352;
BA_ "SPN" SG_ 2364747006 Hvsp25Mdl29OprtnlStts 17353;
BA_ "SPN" SG_ 2364747006 Hvsp25Mdl30OprtnlStts 17354;
BA_ "SPN" SG_ 2364747006 Hvsp25Mdl31OprtnlStts 17355;
BA_ "SPN" SG_ 2364747006 Hvsp25Mdl32OprtnlStts 17356;
BA_ "SPN" SG_ 2364747262 Hvsp25ThrmlMngmntSstmSlInptPwr 17357;
BA_ "SPN" SG_ 2364747262 Hvsp25TMtSstHVtIptPw 17358;
BA_ "SPN" SG_ 2364747262 Hvsp25ThrmlMngmntSstmCmprssrSpd 17359;
BA_ "SPN" SG_ 2364747262 Hvsp25ThrmlMngmntSstmRltvHmdt 17360;
BA_ "SPN" SG_ 2364747262 Hvsp25ThrmlMngmntSstmHtrStts 17361;
BA_ "SPN" SG_ 2364747262 Hvsp25ThrmlMngmntSstmHvlStts 17362;
BA_ "SPN" SG_ 2364747262 Hvsp25ThrmlMngmntSstmMd 17363;
BA_ "SPN" SG_ 2364747262 Hvsp25ThrmlMngmntSstmClntLvl 17364;
BA_ "SPN" SG_ 2364747518 Hvsp25HghstCllVltgMdlNmr 17365;
BA_ "SPN" SG_ 2364747518 Hvsp25HghstCllVltgCllNmr 17366;
BA_ "SPN" SG_ 2364747518 Hvsp25LwstCllVltgMdlNmr 17367;
BA_ "SPN" SG_ 2364747518 Hvsp25LwstCllVltgCllNmr 17368;
BA_ "SPN" SG_ 2364747518 Hvesp25AverageCellVoltage 17369;
BA_ "SPN" SG_ 2364747774 Hvsp25HghstCllTmprtrMdlNmr 17370;
BA_ "SPN" SG_ 2364747774 Hvsp25HghstCllTmprtrCllNmr 17371;
BA_ "SPN" SG_ 2364747774 Hvsp25LwstCllTmprtrMdlNmr 17372;
BA_ "SPN" SG_ 2364747774 Hvsp25LwstCllTmprtrCllNmr 17373;
BA_ "SPN" SG_ 2364747774 Hvess25ThermalEventDetected 21312;
BA_ "SPN" SG_ 2364747774 Hvsp25Dt9EmdddIntgrtSpprt 23046;
BA_ "SPN" SG_ 2364747774 Hvesp25Data9Counter 23047;
BA_ "SPN" SG_ 2364747774 Hvesp25Data9Crc 23048;
BA_ "SPN" SG_ 2364748030 Hvsp25HghstCllSttOfChrgMdlNmr 17374;
BA_ "SPN" SG_ 2364748030 Hvsp25HghstCllSttOfChrgCllNmr 17375;
BA_ "SPN" SG_ 2364748030 Hvsp25LwstCllSttOfChrgMdlNmr 17376;
BA_ "SPN" SG_ 2364748030 Hvsp25LwstCllSttOfChrgCllNmr 17377;
BA_ "SPN" SG_ 2364748030 Hvsp25HghVltgBsAtvIsltnTstRslts 17378;
BA_ "SPN" SG_ 2364748030 Hvsp25HVtBsPssvIstTstRsts 17379;
BA_ "SPN" SG_ 2364748286 Hvsp25BsVltgNgtvTChsssGrndVltg 17380;
BA_ "SPN" SG_ 2364748286 Hvsp25VltgLvlNgtvTChsssGrndVltg 17381;
BA_ "SPN" SG_ 2364748286 Hvesp25ActualChargeRate 17382;
BA_ "SPN" SG_ 2364748542 Hvsp26DshrgPwrLmtDTSttOfChrg 17410;
BA_ "SPN" SG_ 2364748542 Hvsp26DshrgPwrLmtDTBttrTmprtr 17411;
BA_ "SPN" SG_ 2364748542 Hvsp26DsPwLtDTBttDstCdt 17412;
BA_ "SPN" SG_ 2364748542 Hvsp26DsPwLtDTBttOCVt 17413;
BA_ "SPN" SG_ 2364748542 Hvsp26DshrgPwrLmtDTBttrCrrnt 17414;
BA_ "SPN" SG_ 2364748542 Hvsp26DshrgPwrLmtDTAnUndfndCs 17415;
BA_ "SPN" SG_ 2364748542 Hvsp26ChrgPwrLmtDTSttOfChrg 17416;
BA_ "SPN" SG_ 2364748542 Hvsp26ChrgPwrLmtDTBttrTmprtr 17417;
BA_ "SPN" SG_ 2364748542 Hvsp26CPwLtDTBttDstCdt 17418;
BA_ "SPN" SG_ 2364748542 Hvsp26ChrgPwrLmtDTBttrOrCllVltg 17419;
BA_ "SPN" SG_ 2364748542 Hvsp26ChrgPwrLmtDTBttrCrrnt 17420;
BA_ "SPN" SG_ 2364748542 Hvsp26ChrgPwrLmtDTAnUndfndCs 17421;
BA_ "SPN" SG_ 2364748798 Hvesp26AvailableDischargePower 17422;
BA_ "SPN" SG_ 2364748798 Hvesp26AvailableChargePower 17423;
BA_ "SPN" SG_ 2364748798 Hvesp26VoltageLevel 17424;
BA_ "SPN" SG_ 2364748798 Hvesp26Current 17425;
BA_ "SPN" SG_ 2364749054 Hvesp26FastUpdateStateOfCharge 17426;
BA_ "SPN" SG_ 2364749054 Hvesp26HighestCellVoltage 17427;
BA_ "SPN" SG_ 2364749054 Hvesp26LowestCellVoltage 17428;
BA_ "SPN" SG_ 2364749054 Hvsp26CllVltgDffrntlStts 17429;
BA_ "SPN" SG_ 2364749310 Hvesp26HighestCellTemperature 17430;
BA_ "SPN" SG_ 2364749310 Hvesp26LowestCellTemperature 17431;
BA_ "SPN" SG_ 2364749310 Hvesp26AverageCellTemperature 17432;
BA_ "SPN" SG_ 2364749310 Hvsp26CllTmprtrDffrntlStts 17433;
BA_ "SPN" SG_ 2364749566 Hvesp26DischargeCapacity 17434;
BA_ "SPN" SG_ 2364749566 Hvesp26ChargeCapacity 17435;
BA_ "SPN" SG_ 2364749566 Hvesp26CellBalancingCount 17436;
BA_ "SPN" SG_ 2364749822 Hvesp26LowestCellStateOfCharge 17439;
BA_ "SPN" SG_ 2364749822 Hvesp26HighestCellStateOfCharge 17440;
BA_ "SPN" SG_ 2364749822 Hvsp26MxmmInstntnsDshrgCrrntLmt 17437;
BA_ "SPN" SG_ 2364749822 Hvsp26MxmmInstntnsChrgCrrntLmt 17438;
BA_ "SPN" SG_ 2364750078 Hvesp26BusVoltage 17441;
BA_ "SPN" SG_ 2364750078 Hvesp26IgnitionVoltage 17442;
BA_ "SPN" SG_ 2364750078 Hvesp26IntakeCoolantTemperature 17443;
BA_ "SPN" SG_ 2364750078 Hvesp26OutletCoolantTemperature 17444;
BA_ "SPN" SG_ 2364750078 Hvesp26ElectronicsTemperature 17445;
BA_ "SPN" SG_ 2364750078 Hvesp26Temperature 17446;
BA_ "SPN" SG_ 2364750334 Hvsp26HghVltgBsPstvCnttrStt 17447;
BA_ "SPN" SG_ 2364750334 Hvsp26HghVltgBsNgtvCnttrStt 17448;
BA_ "SPN" SG_ 2364750334 Hvsp26HghVltgBsDsnntFrwrnng 17449;
BA_ "SPN" SG_ 2364750334 Hvsp26HghVltgBsPrChrgRlStt 17450;
BA_ "SPN" SG_ 2364750334 Hvsp26CntrOfPkCnttrStt 17451;
BA_ "SPN" SG_ 2364750334 Hvsp26HghVltgBsAtvIsltnTstStts 17452;
BA_ "SPN" SG_ 2364750334 Hvsp26HghVltgBsPssvIsltnTstStts 17453;
BA_ "SPN" SG_ 2364750334 Hvesp26HvilStatus 17454;
BA_ "SPN" SG_ 2364750334 Hvesp26InertiaSwitchStatus 17455;
BA_ "SPN" SG_ 2364750334 Hvesp26StateOfChargeStatus 17456;
BA_ "SPN" SG_ 2364750334 Hvesp26CellBalanceStatus 17457;
BA_ "SPN" SG_ 2364750334 Hvesp26CellBalancingActive 17458;
BA_ "SPN" SG_ 2364750334 Hvesp26InternalChargerStatus 17459;
BA_ "SPN" SG_ 2364750334 Hvsp26HghVltgBsCnntnStts 17460;
BA_ "SPN" SG_ 2364750334 Hvesp26OperationalStatus 17461;
BA_ "SPN" SG_ 2364750334 Hvesp26Status1Counter 17462;
BA_ "SPN" SG_ 2364750334 Hvesp26Status1Crc 17463;
BA_ "SPN" SG_ 2364750590 Hvesp26DischargeEnergyCapacity 17464;
BA_ "SPN" SG_ 2364750590 Hvesp26ChargeEnergyCapacity 17465;
BA_ "SPN" SG_ 2364750590 Hvsp26MxmmChrgVltgLmt 17466;
BA_ "SPN" SG_ 2364750846 Hvesp26Module1OperationalStatus 17467;
BA_ "SPN" SG_ 2364750846 Hvesp26Module2OperationalStatus 17468;
BA_ "SPN" SG_ 2364750846 Hvesp26Module3OperationalStatus 17469;
BA_ "SPN" SG_ 2364750846 Hvesp26Module4OperationalStatus 17470;
BA_ "SPN" SG_ 2364750846 Hvesp26Module5OperationalStatus 17471;
BA_ "SPN" SG_ 2364750846 Hvesp26Module6OperationalStatus 17472;
BA_ "SPN" SG_ 2364750846 Hvesp26Module7OperationalStatus 17473;
BA_ "SPN" SG_ 2364750846 Hvesp26Module8OperationalStatus 17474;
BA_ "SPN" SG_ 2364750846 Hvesp26Module9OperationalStatus 17475;
BA_ "SPN" SG_ 2364750846 Hvsp26Mdl10OprtnlStts 17476;
BA_ "SPN" SG_ 2364750846 Hvsp26Mdl11OprtnlStts 17477;
BA_ "SPN" SG_ 2364750846 Hvsp26Mdl12OprtnlStts 17478;
BA_ "SPN" SG_ 2364750846 Hvsp26Mdl13OprtnlStts 17479;
BA_ "SPN" SG_ 2364750846 Hvsp26Mdl14OprtnlStts 17480;
BA_ "SPN" SG_ 2364750846 Hvsp26Mdl15OprtnlStts 17481;
BA_ "SPN" SG_ 2364750846 Hvsp26Mdl16OprtnlStts 17482;
BA_ "SPN" SG_ 2364750846 Hvsp26Mdl17OprtnlStts 17483;
BA_ "SPN" SG_ 2364750846 Hvsp26Mdl18OprtnlStts 17484;
BA_ "SPN" SG_ 2364750846 Hvsp26Mdl19OprtnlStts 17485;
BA_ "SPN" SG_ 2364750846 Hvsp26Mdl20OprtnlStts 17486;
BA_ "SPN" SG_ 2364750846 Hvsp26Mdl21OprtnlStts 17487;
BA_ "SPN" SG_ 2364750846 Hvsp26Mdl22OprtnlStts 17488;
BA_ "SPN" SG_ 2364750846 Hvsp26Mdl23OprtnlStts 17489;
BA_ "SPN" SG_ 2364750846 Hvsp26Mdl24OprtnlStts 17490;
BA_ "SPN" SG_ 2364750846 Hvsp26Mdl25OprtnlStts 17491;
BA_ "SPN" SG_ 2364750846 Hvsp26Mdl26OprtnlStts 17492;
BA_ "SPN" SG_ 2364750846 Hvsp26Mdl27OprtnlStts 17493;
BA_ "SPN" SG_ 2364750846 Hvsp26Mdl28OprtnlStts 17494;
BA_ "SPN" SG_ 2364750846 Hvsp26Mdl29OprtnlStts 17495;
BA_ "SPN" SG_ 2364750846 Hvsp26Mdl30OprtnlStts 17496;
BA_ "SPN" SG_ 2364750846 Hvsp26Mdl31OprtnlStts 17497;
BA_ "SPN" SG_ 2364750846 Hvsp26Mdl32OprtnlStts 17498;
BA_ "SPN" SG_ 2364751102 Hvsp26ThrmlMngmntSstmSlInptPwr 17499;
BA_ "SPN" SG_ 2364751102 Hvsp26TMtSstHVtIptPw 17500;
BA_ "SPN" SG_ 2364751102 Hvsp26ThrmlMngmntSstmCmprssrSpd 17501;
BA_ "SPN" SG_ 2364751102 Hvsp26ThrmlMngmntSstmRltvHmdt 17502;
BA_ "SPN" SG_ 2364751102 Hvsp26ThrmlMngmntSstmHtrStts 17503;
BA_ "SPN" SG_ 2364751102 Hvsp26ThrmlMngmntSstmHvlStts 17504;
BA_ "SPN" SG_ 2364751102 Hvsp26ThrmlMngmntSstmMd 17505;
BA_ "SPN" SG_ 2364751102 Hvsp26ThrmlMngmntSstmClntLvl 17506;
BA_ "SPN" SG_ 2364751358 Hvsp26HghstCllVltgMdlNmr 17507;
BA_ "SPN" SG_ 2364751358 Hvsp26HghstCllVltgCllNmr 17508;
BA_ "SPN" SG_ 2364751358 Hvsp26LwstCllVltgMdlNmr 17509;
BA_ "SPN" SG_ 2364751358 Hvsp26LwstCllVltgCllNmr 17510;
BA_ "SPN" SG_ 2364751358 Hvesp26AverageCellVoltage 17511;
BA_ "SPN" SG_ 2364751614 Hvsp26HghstCllTmprtrMdlNmr 17512;
BA_ "SPN" SG_ 2364751614 Hvsp26HghstCllTmprtrCllNmr 17513;
BA_ "SPN" SG_ 2364751614 Hvsp26LwstCllTmprtrMdlNmr 17514;
BA_ "SPN" SG_ 2364751614 Hvsp26LwstCllTmprtrCllNmr 17515;
BA_ "SPN" SG_ 2364751614 Hvess26ThermalEventDetected 21313;
BA_ "SPN" SG_ 2364751614 Hvsp26Dt9EmdddIntgrtSpprt 23049;
BA_ "SPN" SG_ 2364751614 Hvesp26Data9Counter 23050;
BA_ "SPN" SG_ 2364751614 Hvesp26Data9Crc 23051;
BA_ "SPN" SG_ 2364751870 Hvsp26HghstCllSttOfChrgMdlNmr 17516;
BA_ "SPN" SG_ 2364751870 Hvsp26HghstCllSttOfChrgCllNmr 17517;
BA_ "SPN" SG_ 2364751870 Hvsp26LwstCllSttOfChrgMdlNmr 17518;
BA_ "SPN" SG_ 2364751870 Hvsp26LwstCllSttOfChrgCllNmr 17519;
BA_ "SPN" SG_ 2364751870 Hvsp26HghVltgBsAtvIsltnTstRslts 17520;
BA_ "SPN" SG_ 2364751870 Hvsp26HVtBsPssvIstTstRsts 17521;
BA_ "SPN" SG_ 2364752126 Hvsp26BsVltgNgtvTChsssGrndVltg 17522;
BA_ "SPN" SG_ 2364752126 Hvsp26VltgLvlNgtvTChsssGrndVltg 17523;
BA_ "SPN" SG_ 2364752126 Hvesp26ActualChargeRate 17524;
BA_ "SPN" SG_ 2297643518 ExtrnlStrngRqstOprtngMd 21090;
BA_ "SPN" SG_ 2297643518 ExtrnlStrngWhlPstnRqst 21091;
BA_ "SPN" SG_ 2297643518 ExtrnlStrngWhlTrqRqst 21092;
BA_ "SPN" SG_ 2297643518 ExternalSteeringRequestPriority 21093;
BA_ "SPN" SG_ 2297643518 XsrMessageCounter 21094;
BA_ "SPN" SG_ 2297643518 XsrMessageChecksum 21095;
BA_ "SPN" SG_ 2364752638 ActiveSteeringActualMode 21096;
BA_ "SPN" SG_ 2364752638 ActiveSteeringSystemState 21097;
BA_ "SPN" SG_ 2364752638 ActiveSteeringErrorType 21098;
BA_ "SPN" SG_ 2364752638 ActiveSteeringRequestedMode 21099;
BA_ "SPN" SG_ 2364752638 ActiveSteeringIgnitionPower 21100;
BA_ "SPN" SG_ 2364752638 AsltStrngPstnQltFtr 21101;
BA_ "SPN" SG_ 2364752638 AtvStrngSstmStrngWhlPstn 21102;
BA_ "SPN" SG_ 2364752638 AtvStrngSstmStrngWhlTrq 21103;
BA_ "SPN" SG_ 2364752638 Assc2MessageCounter 21104;
BA_ "SPN" SG_ 2364752638 Assc2MessageChecksum 21105;
BA_ "SPN" SG_ 2566540286 Atttt2DsExstFdDs2PssExtddR 20910;
BA_ "SPN" SG_ 2566540286 Atttt2DsExstFdDs3PssExtddR 20911;
BA_ "SPN" SG_ 2566540542 Atttt1DsExstFdDs2PssExtddR 20907;
BA_ "SPN" SG_ 2566540542 Atttt1DsExstFdDs3PssExtddR 20908;
BA_ "SPN" SG_ 2566540798 TotalTripEnergyConsumed 20876;
BA_ "SPN" SG_ 2566540798 TripDriveEnergyEconomy 20875;
BA_ "SPN" SG_ 2566541054 AttdDvSstOptSttsAwdt 20871;
BA_ "SPN" SG_ 2566541054 AdsManualModeSupport 20872;
BA_ "SPN" SG_ 2566541054 AdsAtmtdMdWthOprtrOvrrdSpprt 20873;
BA_ "SPN" SG_ 2566541054 AdsAutomatedModeSupport 20874;
BA_ "SPN" SG_ 2566541054 AdsCntrllr1CmmntnStts 21247;
BA_ "SPN" SG_ 2566541054 AdsCntrllr2CmmntnStts 21248;
BA_ "SPN" SG_ 2566541054 AdsCntrllr3CmmntnStts 21249;
BA_ "SPN" SG_ 2566541054 AdsCntrllr4CmmntnStts 21250;
BA_ "SPN" SG_ 2566541054 CmpnntDgnstAndMtgtnCplt 22678;
BA_ "SPN" SG_ 2566541054 Adss2EmbeddedIntegritySupport 23062;
BA_ "SPN" SG_ 2566541054 Adss2Counter 23063;
BA_ "SPN" SG_ 2566541054 Adss2Crc 23064;
BA_ "SPN" SG_ 2566541310 AtmtdDrvngSstmOprtnStts 20870;
BA_ "SPN" SG_ 2566541310 Adsc3Counter 14455;
BA_ "SPN" SG_ 2566541310 Adsc3Crc 14456;
BA_ "SPN" SG_ 2566541310 Adsc3EmbeddedIntegritySupport 22264;
BA_ "SPN" SG_ 2566541566 EngnAftrlrClntTmprtr 20807;
BA_ "SPN" SG_ 2566541566 EDsdAtCtItTptHRst 20808;
BA_ "SPN" SG_ 2566541566 EAtCtDtPssSwtStts 20809;
BA_ "SPN" SG_ 2566541566 EngnAftrlrClntPmpCntrl 20810;
BA_ "SPN" SG_ 2566541566 EngnAftrlrClntDvrtrVlvPstn 23500;
BA_ "SPN" SG_ 2566541822 EngnRdtr1CntrlTmprtr 20811;
BA_ "SPN" SG_ 2566541822 DsrdEngnRdtr1CntrlTmprtr 20812;
BA_ "SPN" SG_ 2566541822 EngineRadiator1Fan1Status 20813;
BA_ "SPN" SG_ 2566541822 EngineRadiator1Fan2Status 20814;
BA_ "SPN" SG_ 2566541822 EngineRadiator1Fan3Status 20815;
BA_ "SPN" SG_ 2566541822 EngineRadiator1Fan4Status 20816;
BA_ "SPN" SG_ 2566541822 EngineRadiator1Fan5Status 20817;
BA_ "SPN" SG_ 2566541822 EngineRadiator1Fan6Status 20818;
BA_ "SPN" SG_ 2566541822 EngineRadiator1Fan7Status 20819;
BA_ "SPN" SG_ 2566541822 EngineRadiator1Fan8Status 20820;
BA_ "SPN" SG_ 2566541822 EngnRdtrTmprtrCntrlSltnStts 21160;
BA_ "SPN" SG_ 2566542078 EngnRdtr2CntrlTmprtr 20821;
BA_ "SPN" SG_ 2566542078 DsrdEngnRdtr2CntrlTmprtr 20822;
BA_ "SPN" SG_ 2566542078 EngineRadiator2Fan1Status 20823;
BA_ "SPN" SG_ 2566542078 EngineRadiator2Fan2Status 20824;
BA_ "SPN" SG_ 2566542078 EngineRadiator2Fan3Status 20825;
BA_ "SPN" SG_ 2566542078 EngineRadiator2Fan4Status 20826;
BA_ "SPN" SG_ 2566542078 EngineRadiator2Fan5Status 20827;
BA_ "SPN" SG_ 2566542078 EngineRadiator2Fan6Status 20828;
BA_ "SPN" SG_ 2566542078 EngineRadiator2Fan7Status 20829;
BA_ "SPN" SG_ 2566542078 EngineRadiator2Fan8Status 20830;
BA_ "SPN" SG_ 2566542334 GnstEnlsrIntkArTmprtr 20831;
BA_ "SPN" SG_ 2566542334 GnstEnlsrOtltArTmprtr 20832;
BA_ "SPN" SG_ 2566542334 GnstEnlsrFnRqstdPrntSpd 20833;
BA_ "SPN" SG_ 2566542334 GensetEnclosureFanStatus 21156;
BA_ "SPN" SG_ 2566542590 HtExhngr1PrmrIntkTmprtr 20834;
BA_ "SPN" SG_ 2566542590 HtExhngr1PrmrOtltTmprtr 20835;
BA_ "SPN" SG_ 2566542590 HtExhngr1SndrIntkTmprtr 20836;
BA_ "SPN" SG_ 2566542590 HtExhngr1SndrOtltTmprtr 20837;
BA_ "SPN" SG_ 2566542846 HtExhngr2PrmrIntkTmprtr 20838;
BA_ "SPN" SG_ 2566542846 HtExhngr2PrmrOtltTmprtr 20839;
BA_ "SPN" SG_ 2566542846 HtExhngr2SndrIntkTmprtr 20840;
BA_ "SPN" SG_ 2566542846 HtExhngr2SndrOtltTmprtr 20841;
BA_ "SPN" SG_ 2566543102 HtExhngr3PrmrIntkTmprtr 20842;
BA_ "SPN" SG_ 2566543102 HtExhngr3PrmrOtltTmprtr 20843;
BA_ "SPN" SG_ 2566543102 HtExhngr3SndrIntkTmprtr 20844;
BA_ "SPN" SG_ 2566543102 HtExhngr3SndrOtltTmprtr 20845;
BA_ "SPN" SG_ 2566543358 HtExhngr4PrmrIntkTmprtr 20846;
BA_ "SPN" SG_ 2566543358 HtExhngr4PrmrOtltTmprtr 20847;
BA_ "SPN" SG_ 2566543358 HtExhngr4SndrIntkTmprtr 20848;
BA_ "SPN" SG_ 2566543358 HtExhngr4SndrOtltTmprtr 20849;
BA_ "SPN" SG_ 2566543614 EngnExhstHtExhngrOtltTmprtr 20850;
BA_ "SPN" SG_ 2566543614 EExstHtExBpssAtt1DsdPst 20851;
BA_ "SPN" SG_ 2566543614 EngnExhstHtExhngrBpssAttr1Pstn 20852;
BA_ "SPN" SG_ 2566543870 GnstEnlsrVntltnLvrAttr1DsrdPstn 20853;
BA_ "SPN" SG_ 2566543870 GnstEnlsrVntltnLvrAttr1Pstn 20854;
BA_ "SPN" SG_ 2566543870 GnstEnlsrVntltnLvrAttr2DsrdPstn 20855;
BA_ "SPN" SG_ 2566543870 GnstEnlsrVntltnLvrAttr2Pstn 20856;
BA_ "SPN" SG_ 2566543870 GstEsVttRtLvAttDsdPst 20857;
BA_ "SPN" SG_ 2566543870 GnstEnlsrVntltnRrltnLvrAttrPstn 20858;
BA_ "SPN" SG_ 2566544126 DsrdHtngCrtThrmsttOpnng 20861;
BA_ "SPN" SG_ 2566544126 HeatingCircuitThermostatOpening 20862;
BA_ "SPN" SG_ 2566544126 HtngCrtDffrntlPrssrSwthStts 20863;
BA_ "SPN" SG_ 2566544126 HeatingCircuitPumpControl 20864;
BA_ "SPN" SG_ 2566544126 HtngCrtSpplOtltClntTmprtr 20859;
BA_ "SPN" SG_ 2566544126 HtngCrtRtrnClntTmprtr 20860;
BA_ "SPN" SG_ 2566544382 EvCabinConditioningFlag 21061;
BA_ "SPN" SG_ 2566544382 EvRessConditioningFlag 21062;
BA_ "SPN" SG_ 2566544382 EvErrorCode 21063;
BA_ "SPN" SG_ 2566544638 EvseEnergyToBeDelivered 21064;
BA_ "SPN" SG_ 2566545406 EvBulkStateOfCharge 21075;
BA_ "SPN" SG_ 2566545406 EvFullStateOfCharge 21076;
BA_ "SPN" SG_ 2566545406 EvEnergyCapacity 21077;
BA_ "SPN" SG_ 2566545406 EvEnergyRequested 21078;
BA_ "SPN" SG_ 2566545662 EvBulkChargingComplete 21079;
BA_ "SPN" SG_ 2566545662 EvFullChargingComplete 21080;
BA_ "SPN" SG_ 2566545662 EvBulkChargeTimeRemaining 21081;
BA_ "SPN" SG_ 2566545662 EvFullChargeTimeRemaining 21082;
BA_ "SPN" SG_ 2566545662 EvDepartureTime 21083;
BA_ "SPN" SG_ 2566546174 TractorHazardLights 20800;
BA_ "SPN" SG_ 2365219838 LightingData2RequestCommand 20798;
BA_ "SPN" SG_ 2365219838 TractorHazardLightsCommand 20799;
BA_ "SPN" SG_ 2566546686 Aftrtrtmnt1SrIntkHghTmprtrCnt 20796;
BA_ "SPN" SG_ 2566546686 Aftrtrtmnt1TtlEvntCntWthNDfDlvr 20797;
BA_ "SPN" SG_ 2566546942 AftrtrtmntSrMlfntnCnt 20794;
BA_ "SPN" SG_ 2566546942 DieselExhaustFluidFrozenCount 20795;
BA_ "SPN" SG_ 2566547198 DslExhstFldTnk1EmptCnt 20792;
BA_ "SPN" SG_ 2566547198 DslExhstFldQltMlfntnCnt 20793;
BA_ "SPN" SG_ 2633656318 EngineOilResistance 20785;
BA_ "SPN" SG_ 2633656318 HydraulicOilResistance 20786;
BA_ "SPN" SG_ 2566547710 PwCvt2HVtBsAtvIstTstCd 20499;
BA_ "SPN" SG_ 2566547710 PwCvt2HVtBsPssvIstTstCd 20500;
BA_ "SPN" SG_ 2566547710 PwCvt2HVtBsHSdRsstCtRqst 20501;
BA_ "SPN" SG_ 2566547710 PwCvt2HVtBsLwSdRsstCtRqst 20502;
BA_ "SPN" SG_ 2566547966 PwCvt1HVtBsAtvIstTstCd 20503;
BA_ "SPN" SG_ 2566547966 PwCvt1HVtBsPssvIstTstCd 20504;
BA_ "SPN" SG_ 2566547966 PwCvt1HVtBsHSdRsstCtRqst 20505;
BA_ "SPN" SG_ 2566547966 PwCvt1HVtBsLwSdRsstCtRqst 20506;
BA_ "SPN" SG_ 2566548222 PwrCnvrtr2LmtsRqstPwrCr 20507;
BA_ "SPN" SG_ 2566548222 PwrCnvrtr2LmtsRqstPwrCntr 20508;
BA_ "SPN" SG_ 2566548222 PwrCnvrtr2LmtsRqstEltrlPwrMxmm 20509;
BA_ "SPN" SG_ 2566548222 PwrCnvrtr2LmtsRqstEltrlPwrMnmm 20510;
BA_ "SPN" SG_ 2566548222 PwCvt2LtsRqstDES1PwMx 20511;
BA_ "SPN" SG_ 2566548222 PwCvt2LtsRqstDES1PwM 20512;
BA_ "SPN" SG_ 2566548478 PwrCnvrtr2LmtsRqstEltrlCr 20513;
BA_ "SPN" SG_ 2566548478 PwrCnvrtr2LmtsRqstEltrlCntr 20514;
BA_ "SPN" SG_ 2566548478 PwrCnvrtr2LmtsRqstCrrntMxmm 20515;
BA_ "SPN" SG_ 2566548478 PwrCnvrtr2LmtsRqstCrrntMnmm 20516;
BA_ "SPN" SG_ 2566548478 PwrCnvrtr2LmtsRqstFrqnMxmm 20517;
BA_ "SPN" SG_ 2566548478 PwrCnvrtr2LmtsRqstFrqnMnmm 20518;
BA_ "SPN" SG_ 2566548734 PwrCnvrtr2LmtsRqstDEnrgSr1Cr 20519;
BA_ "SPN" SG_ 2566548734 PwrCnvrtr2LmtsRqstDEnrgSr1Cntr 20520;
BA_ "SPN" SG_ 2566548734 PwCvt2LtsRqstDES1VtMx 20521;
BA_ "SPN" SG_ 2566548734 PwCvt2LtsRqstDES1VtM 20522;
BA_ "SPN" SG_ 2566548734 PwCvt2LtsRqstDES1CtMx 20523;
BA_ "SPN" SG_ 2566548734 PwCvt2LtsRqstDES1CtM 20524;
BA_ "SPN" SG_ 2566548990 PwrCnvrtr1LmtsRqstDEnrgSr1Cr 20525;
BA_ "SPN" SG_ 2566548990 PwrCnvrtr1LmtsRqstDEnrgSr1Cntr 20526;
BA_ "SPN" SG_ 2566548990 PwCvt1LtsRqstDES1VtMx 20527;
BA_ "SPN" SG_ 2566548990 PwCvt1LtsRqstDES1VtM 20528;
BA_ "SPN" SG_ 2566548990 PwCvt1LtsRqstDES1CtMx 20529;
BA_ "SPN" SG_ 2566548990 PwCvt1LtsRqstDES1CtM 20530;
BA_ "SPN" SG_ 2566549246 PwrCnvrtr1LmtsRqstEltrlCr 20531;
BA_ "SPN" SG_ 2566549246 PwrCnvrtr1LmtsRqstEltrlCntr 20532;
BA_ "SPN" SG_ 2566549246 PwrCnvrtr1LmtsRqstCrrntMxmm 20533;
BA_ "SPN" SG_ 2566549246 PwrCnvrtr1LmtsRqstCrrntMnmm 20534;
BA_ "SPN" SG_ 2566549246 PwrCnvrtr1LmtsRqstFrqnMxmm 20535;
BA_ "SPN" SG_ 2566549246 PwrCnvrtr1LmtsRqstFrqnMnmm 20536;
BA_ "SPN" SG_ 2566549502 PwrCnvrtr1LmtsRqstPwrCr 20537;
BA_ "SPN" SG_ 2566549502 PwrCnvrtr1LmtsRqstPwrCntr 20538;
BA_ "SPN" SG_ 2566549502 PwrCnvrtr1LmtsRqstEltrlPwrMxmm 20539;
BA_ "SPN" SG_ 2566549502 PwrCnvrtr1LmtsRqstEltrlPwrMnmm 20540;
BA_ "SPN" SG_ 2566549502 PwCvt1LtsRqstDES1PwMx 20541;
BA_ "SPN" SG_ 2566549502 PwCvt1LtsRqstDES1PwM 20542;
BA_ "SPN" SG_ 2566549758 PwrCnvrtr1TtlEnrgCnsmd 20607;
BA_ "SPN" SG_ 2566549758 PwrCnvrtr1TtlEnrgGnrtd 20608;
BA_ "SPN" SG_ 2566549758 PwrCnvrtr1TtlChrgCnsmd 20609;
BA_ "SPN" SG_ 2566549758 PwrCnvrtr1TtlChrgGnrtd 20610;
BA_ "SPN" SG_ 2566550014 PwrCnvrtr2TtlEnrgCnsmd 20611;
BA_ "SPN" SG_ 2566550014 PwrCnvrtr2TtlEnrgGnrtd 20612;
BA_ "SPN" SG_ 2566550014 PwrCnvrtr2TtlChrgCnsmd 20613;
BA_ "SPN" SG_ 2566550014 PwrCnvrtr2TtlChrgGnrtd 20614;
BA_ "SPN" SG_ 2566550270 PwrCnvrtr2PwrLmtdDTUndfndRsn 20615;
BA_ "SPN" SG_ 2566550270 PwCvt2PwLtdDTDES1CtMx 20616;
BA_ "SPN" SG_ 2566550270 PwCvt2PwLtdDTDES1CtM 20617;
BA_ "SPN" SG_ 2566550270 PwCvt2PwLtdDTDES1VtMx 20618;
BA_ "SPN" SG_ 2566550270 PwCvt2PwLtdDTDES1VtM 20619;
BA_ "SPN" SG_ 2566550270 PwrCnvrtr2PwrLmtdDTEltrlPwrMxmm 20620;
BA_ "SPN" SG_ 2566550270 PwrCnvrtr2PwrLmtdDTEltrlPwrMnmm 20621;
BA_ "SPN" SG_ 2566550270 PwCvt2PwLtdDTDES1PwMx 20622;
BA_ "SPN" SG_ 2566550270 PwCvt2PwLtdDTDES1PwM 20623;
BA_ "SPN" SG_ 2566550270 PwrCnvrtr2PwrLmtdDTCrrntMxmm 20624;
BA_ "SPN" SG_ 2566550270 PwrCnvrtr2PwrLmtdDTCrrntMnmm 20625;
BA_ "SPN" SG_ 2566550270 PwrCnvrtr2PwrLmtdDTFrqnMxmm 20626;
BA_ "SPN" SG_ 2566550270 PwrCnvrtr2PwrLmtdDTFrqnMnmm 20627;
BA_ "SPN" SG_ 2566550270 PwrCnvrtr2PwrLmtdDTInvrtrTmprtr 20628;
BA_ "SPN" SG_ 2566550270 PwrCnvrtr2PwrLmtdDTTmprtr 20629;
BA_ "SPN" SG_ 2566550270 PwrCnvrtr2PwrLmtdDTFltCndtn 20630;
BA_ "SPN" SG_ 2566550270 PwCvt2PwLtdDTAtvCtRtLt 20631;
BA_ "SPN" SG_ 2566550270 PwCvt2CtLtdDTMCtsts 20632;
BA_ "SPN" SG_ 2566550526 PwrCnvrtr1PwrLmtdDTUndfndRsn 20640;
BA_ "SPN" SG_ 2566550526 PwCvt1PwLtdDTDES1CtMx 20641;
BA_ "SPN" SG_ 2566550526 PwCvt1PwLtdDTDES1CtM 20642;
BA_ "SPN" SG_ 2566550526 PwCvt1PwLtdDTDES1VtMx 20643;
BA_ "SPN" SG_ 2566550526 PwCvt1PwLtdDTDES1VtM 20644;
BA_ "SPN" SG_ 2566550526 PwrCnvrtr1PwrLmtdDTEltrlPwrMxmm 20645;
BA_ "SPN" SG_ 2566550526 PwrCnvrtr1PwrLmtdDTEltrlPwrMnmm 20646;
BA_ "SPN" SG_ 2566550526 PwCvt1PwLtdDTDES1PwMx 20647;
BA_ "SPN" SG_ 2566550526 PwCvt1PwLtdDTDES1PwM 20648;
BA_ "SPN" SG_ 2566550526 PwrCnvrtr1PwrLmtdDTCrrntMxmm 20649;
BA_ "SPN" SG_ 2566550526 PwrCnvrtr1PwrLmtdDTCrrntMnmm 20650;
BA_ "SPN" SG_ 2566550526 PwrCnvrtr1PwrLmtdDTFrqnMxmm 20651;
BA_ "SPN" SG_ 2566550526 PwrCnvrtr1PwrLmtdDTFrqnMnmm 20652;
BA_ "SPN" SG_ 2566550526 PwrCnvrtr1PwrLmtdDTInvrtrTmprtr 20653;
BA_ "SPN" SG_ 2566550526 PwrCnvrtr1PwrLmtdDTTmprtr 20654;
BA_ "SPN" SG_ 2566550526 PwrCnvrtr1PwrLmtdDTFltCndtn 20655;
BA_ "SPN" SG_ 2566550526 PwCvt1PwLtdDTAtvCtRtLt 20656;
BA_ "SPN" SG_ 2566550526 PwCvt1CtLtdDTMCtsts 20657;
BA_ "SPN" SG_ 2365224190 PowerConverter2Reference1Crc 20665;
BA_ "SPN" SG_ 2365224190 PwrCnvrtr2Rfrn1Cntr 20666;
BA_ "SPN" SG_ 2365224190 PwrCnvrtr2RfrnFrqn 20668;
BA_ "SPN" SG_ 2365224190 PowerConverter2ReferencePower 20669;
BA_ "SPN" SG_ 2365224190 PowerConverter2ReferenceTorque 20667;
BA_ "SPN" SG_ 2365224446 PowerConverter2ReferenceCurrent 20678;
BA_ "SPN" SG_ 2365224446 PowerConverter2Reference2Crc 20676;
BA_ "SPN" SG_ 2365224446 PwrCnvrtr2Rfrn2Cntr 20677;
BA_ "SPN" SG_ 2365224446 PowerConverter2ReferenceVoltage 20679;
BA_ "SPN" SG_ 2566551294 PowerConverter2Temperature1 20680;
BA_ "SPN" SG_ 2566551294 PowerConverter2Temperature2 20681;
BA_ "SPN" SG_ 2566551294 PowerConverter2Temperature3 20682;
BA_ "SPN" SG_ 2566551294 PowerConverter2Temperature4 20683;
BA_ "SPN" SG_ 2566551550 PowerConverter1Temperature1 20684;
BA_ "SPN" SG_ 2566551550 PowerConverter1Temperature2 20685;
BA_ "SPN" SG_ 2566551550 PowerConverter1Temperature3 20686;
BA_ "SPN" SG_ 2566551550 PowerConverter1Temperature4 20687;
BA_ "SPN" SG_ 2365225214 PowerConverter1Reference2Crc 20688;
BA_ "SPN" SG_ 2365225214 PwrCnvrtr1Rfrn2Cntr 20689;
BA_ "SPN" SG_ 2365225214 PowerConverter1ReferenceCurrent 20690;
BA_ "SPN" SG_ 2365225214 PowerConverter1ReferenceVoltage 20691;
BA_ "SPN" SG_ 2365225470 PowerConverter1Reference1Crc 20698;
BA_ "SPN" SG_ 2365225470 PwrCnvrtr1Rfrn1Cntr 20699;
BA_ "SPN" SG_ 2365225470 PwrCnvrtr1RfrnFrqn 20701;
BA_ "SPN" SG_ 2365225470 PowerConverter1ReferencePower 20702;
BA_ "SPN" SG_ 2365225470 PowerConverter1ReferenceTorque 20700;
BA_ "SPN" SG_ 2365225726 PwrCnvrtr1PwrCnvrtrPhsUCrrnt 20703;
BA_ "SPN" SG_ 2365225726 PwrCnvrtr1PwrCnvrtrPhsVCrrnt 20704;
BA_ "SPN" SG_ 2365225726 PwrCnvrtr1PwrCnvrtrPhsWCrrnt 20705;
BA_ "SPN" SG_ 2365225982 PwrCnvrtr2PwrCnvrtrPhsUCrrnt 20706;
BA_ "SPN" SG_ 2365225982 PwrCnvrtr2PwrCnvrtrPhsVCrrnt 20707;
BA_ "SPN" SG_ 2365225982 PwrCnvrtr2PwrCnvrtrPhsWCrrnt 20708;
BA_ "SPN" SG_ 2365226238 PwrCnvrtr1PwrCnvrtrPhsUVltg 20709;
BA_ "SPN" SG_ 2365226238 PwrCnvrtr1PwrCnvrtrPhsVVltg 20710;
BA_ "SPN" SG_ 2365226238 PwrCnvrtr1PwrCnvrtrPhsWVltg 20711;
BA_ "SPN" SG_ 2365226494 PwrCnvrtr2PwrCnvrtrPhsUVltg 20712;
BA_ "SPN" SG_ 2365226494 PwrCnvrtr2PwrCnvrtrPhsVVltg 20713;
BA_ "SPN" SG_ 2365226494 PwrCnvrtr2PwrCnvrtrPhsWVltg 20714;
BA_ "SPN" SG_ 2566553342 PwCvt1PwCvtPsUPwMdSwtTpt 20715;
BA_ "SPN" SG_ 2566553342 PwCvt1PwCvtPsVPwMdSwtTpt 20716;
BA_ "SPN" SG_ 2566553342 PwCvt1PwCvtPsWPwMdSwtTpt 20717;
BA_ "SPN" SG_ 2566553342 PwCvt2PwCvtPsUPwMdSwtTpt 20718;
BA_ "SPN" SG_ 2566553342 PwCvt2PwCvtPsVPwMdSwtTpt 20719;
BA_ "SPN" SG_ 2566553342 PwCvt2PwCvtPsWPwMdSwtTpt 20720;
BA_ "SPN" SG_ 2365227006 PwCvt1PwCvtPsUPwMdSwtPwSppVt 20721;
BA_ "SPN" SG_ 2365227006 PwCvt1PwCvtPsVPwMdSwtPwSppVt 20722;
BA_ "SPN" SG_ 2365227006 PwCvt1PwCvtPsWPwMdSwtPwSppVt 20723;
BA_ "SPN" SG_ 2365227262 PwCvt2PwCvtPsUPwMdSwtPwSppVt 20724;
BA_ "SPN" SG_ 2365227262 PwCvt2PwCvtPsVPwMdSwtPwSppVt 20725;
BA_ "SPN" SG_ 2365227262 PwCvt2PwCvtPsWPwMdSwtPwSppVt 20726;
BA_ "SPN" SG_ 2365227518 PwrCnvrtr1PwrCnvrtrACrrntOtpt 20727;
BA_ "SPN" SG_ 2365227518 PwrCnvrtr2PwrCnvrtrACrrntOtpt 20728;
BA_ "SPN" SG_ 2365227518 PwCvt1PwCvtPwMdSwtTpt 20729;
BA_ "SPN" SG_ 2365227518 PwCvt2PwCvtPwMdSwtTpt 20730;
BA_ "SPN" SG_ 2566554366 Transformer1PhaseUTemperature 20731;
BA_ "SPN" SG_ 2566554366 Transformer1PhaseVTemperature 20732;
BA_ "SPN" SG_ 2566554366 Transformer1PhaseWTemperature 20733;
BA_ "SPN" SG_ 2566554366 Transformer2PhaseUTemperature 20734;
BA_ "SPN" SG_ 2566554366 Transformer2PhaseVTemperature 20735;
BA_ "SPN" SG_ 2566554366 Transformer2PhaseWTemperature 20736;
BA_ "SPN" SG_ 2566554622 EngnClntEltrPmpEnlStts 20178;
BA_ "SPN" SG_ 2566554622 EngnClntEltrPmpCntrllrSttsRsn 20177;
BA_ "SPN" SG_ 2566554622 EngnClntEltrPmpCntrllrCmmndStts 20176;
BA_ "SPN" SG_ 2566554622 EngnClntEltrPmpMtrSpd 20179;
BA_ "SPN" SG_ 2566554622 EngnClntEltrPmpCntrlTmprtr 20180;
BA_ "SPN" SG_ 2566554622 EngineCoolantElectricPumpPower 20181;
BA_ "SPN" SG_ 2566554622 EngnClntEltrPmpSrvIndtr 20182;
BA_ "SPN" SG_ 2566554622 EngnClntEltrPmpOprtngStts 20183;
